AUTOSAR XML (schema 4-2-2)
package /STELLANTIS/EPT/ASWCs
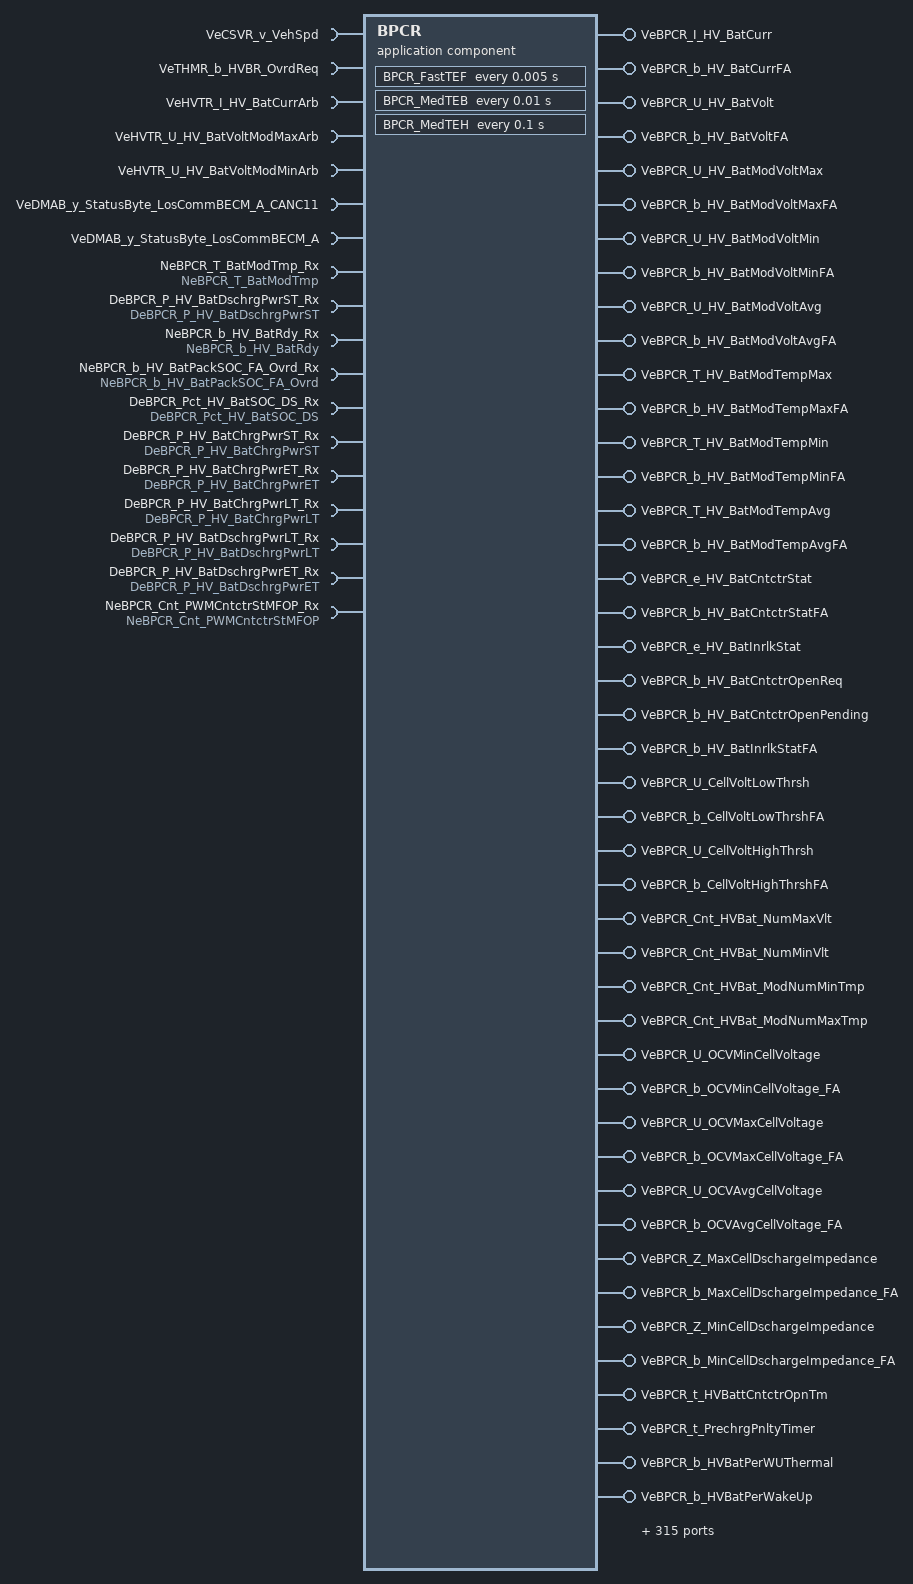
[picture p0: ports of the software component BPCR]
  application sw component type BPCR
    7 x require port, all with nonqueued-receiver-com-spec{data-element=Value, init-value=0}:
      VeCSVR_v_VehSpd: required-interface=VeCSVR_v_VehSpd
      VeTHMR_b_HVBR_OvrdReq: required-interface=VeTHMR_b_HVBR_OvrdReq
      VeHVTR_I_HV_BatCurrArb: required-interface=VeHVTR_I_HV_BatCurrArb
      VeHVTR_U_HV_BatVoltModMaxArb: required-interface=VeHVTR_U_HV_BatVoltModMaxArb
      VeHVTR_U_HV_BatVoltModMinArb: required-interface=VeHVTR_U_HV_BatVoltModMinArb
      VeDMAB_y_StatusByte_LosCommBECM_A_CANC11: required-interface=VeDMAB_y_StatusByte_LosCommBECM_A_CANC11
      VeDMAB_y_StatusByte_LosCommBECM_A: required-interface=VeDMAB_y_StatusByte_LosCommBECM_A
    348 x provide port:
      VeBPCR_I_HV_BatCurr: nonqueued-sender-com-spec{data-element=Value, init-value=0}, provided-interface=VeBPCR_I_HV_BatCurr
      VeBPCR_b_HV_BatCurrFA: nonqueued-sender-com-spec{data-element=Value, init-value=0}, provided-interface=VeBPCR_b_HV_BatCurrFA
      VeBPCR_U_HV_BatVolt: nonqueued-sender-com-spec{data-element=Value, init-value=0}, provided-interface=VeBPCR_U_HV_BatVolt
      VeBPCR_b_HV_BatVoltFA: nonqueued-sender-com-spec{data-element=Value, init-value=0}, provided-interface=VeBPCR_b_HV_BatVoltFA
      VeBPCR_U_HV_BatModVoltMax: nonqueued-sender-com-spec{data-element=Value, init-value=0}, provided-interface=VeBPCR_U_HV_BatModVoltMax
      VeBPCR_b_HV_BatModVoltMaxFA: nonqueued-sender-com-spec{data-element=Value, init-value=0}, provided-interface=VeBPCR_b_HV_BatModVoltMaxFA
      VeBPCR_U_HV_BatModVoltMin: nonqueued-sender-com-spec{data-element=Value, init-value=0}, provided-interface=VeBPCR_U_HV_BatModVoltMin
      VeBPCR_b_HV_BatModVoltMinFA: nonqueued-sender-com-spec{data-element=Value, init-value=0}, provided-interface=VeBPCR_b_HV_BatModVoltMinFA
      VeBPCR_U_HV_BatModVoltAvg: nonqueued-sender-com-spec{data-element=Value, init-value=0}, provided-interface=VeBPCR_U_HV_BatModVoltAvg
      VeBPCR_b_HV_BatModVoltAvgFA: nonqueued-sender-com-spec{data-element=Value, init-value=0}, provided-interface=VeBPCR_b_HV_BatModVoltAvgFA
      VeBPCR_T_HV_BatModTempMax: nonqueued-sender-com-spec{data-element=Value, init-value=0}, provided-interface=VeBPCR_T_HV_BatModTempMax
      VeBPCR_b_HV_BatModTempMaxFA: nonqueued-sender-com-spec{data-element=Value, init-value=0}, provided-interface=VeBPCR_b_HV_BatModTempMaxFA
      VeBPCR_T_HV_BatModTempMin: nonqueued-sender-com-spec{data-element=Value, init-value=0}, provided-interface=VeBPCR_T_HV_BatModTempMin
      VeBPCR_b_HV_BatModTempMinFA: nonqueued-sender-com-spec{data-element=Value, init-value=0}, provided-interface=VeBPCR_b_HV_BatModTempMinFA
      VeBPCR_T_HV_BatModTempAvg: nonqueued-sender-com-spec{data-element=Value, init-value=0}, provided-interface=VeBPCR_T_HV_BatModTempAvg
      VeBPCR_b_HV_BatModTempAvgFA: nonqueued-sender-com-spec{data-element=Value, init-value=0}, provided-interface=VeBPCR_b_HV_BatModTempAvgFA
      VeBPCR_e_HV_BatCntctrStat: nonqueued-sender-com-spec{data-element=Value, init-value=CeHVTR_e_Open}, provided-interface=VeBPCR_e_HV_BatCntctrStat
      VeBPCR_b_HV_BatCntctrStatFA: nonqueued-sender-com-spec{data-element=Value, init-value=0}, provided-interface=VeBPCR_b_HV_BatCntctrStatFA
      VeBPCR_e_HV_BatInrlkStat: nonqueued-sender-com-spec{data-element=Value, init-value=CeHVTR_e_IntrlkNotSourced}, provided-interface=VeBPCR_e_HV_BatInrlkStat
      VeBPCR_b_HV_BatCntctrOpenReq: nonqueued-sender-com-spec{data-element=Value, init-value=0}, provided-interface=VeBPCR_b_HV_BatCntctrOpenReq
      VeBPCR_b_HV_BatCntctrOpenPending: nonqueued-sender-com-spec{data-element=Value, init-value=0}, provided-interface=VeBPCR_b_HV_BatCntctrOpenPending
      VeBPCR_b_HV_BatInrlkStatFA: nonqueued-sender-com-spec{data-element=Value, init-value=0}, provided-interface=VeBPCR_b_HV_BatInrlkStatFA
      VeBPCR_U_CellVoltLowThrsh: nonqueued-sender-com-spec{data-element=Value, init-value=0}, provided-interface=VeBPCR_U_CellVoltLowThrsh
      VeBPCR_b_CellVoltLowThrshFA: nonqueued-sender-com-spec{data-element=Value, init-value=0}, provided-interface=VeBPCR_b_CellVoltLowThrshFA
      VeBPCR_U_CellVoltHighThrsh: nonqueued-sender-com-spec{data-element=Value, init-value=0}, provided-interface=VeBPCR_U_CellVoltHighThrsh
      VeBPCR_b_CellVoltHighThrshFA: nonqueued-sender-com-spec{data-element=Value, init-value=0}, provided-interface=VeBPCR_b_CellVoltHighThrshFA
      VeBPCR_Cnt_HVBat_NumMaxVlt: nonqueued-sender-com-spec{data-element=Value, init-value=0}, provided-interface=VeBPCR_Cnt_HVBat_NumMaxVlt
      VeBPCR_Cnt_HVBat_NumMinVlt: nonqueued-sender-com-spec{data-element=Value, init-value=0}, provided-interface=VeBPCR_Cnt_HVBat_NumMinVlt
      VeBPCR_Cnt_HVBat_ModNumMinTmp: nonqueued-sender-com-spec{data-element=Value, init-value=0}, provided-interface=VeBPCR_Cnt_HVBat_ModNumMinTmp
      VeBPCR_Cnt_HVBat_ModNumMaxTmp: nonqueued-sender-com-spec{data-element=Value, init-value=0}, provided-interface=VeBPCR_Cnt_HVBat_ModNumMaxTmp
      VeBPCR_U_OCVMinCellVoltage: nonqueued-sender-com-spec{data-element=Value, init-value=0}, provided-interface=VeBPCR_U_OCVMinCellVoltage
      VeBPCR_b_OCVMinCellVoltage_FA: nonqueued-sender-com-spec{data-element=Value, init-value=0}, provided-interface=VeBPCR_b_OCVMinCellVoltage_FA
      VeBPCR_U_OCVMaxCellVoltage: nonqueued-sender-com-spec{data-element=Value, init-value=0}, provided-interface=VeBPCR_U_OCVMaxCellVoltage
      VeBPCR_b_OCVMaxCellVoltage_FA: nonqueued-sender-com-spec{data-element=Value, init-value=0}, provided-interface=VeBPCR_b_OCVMaxCellVoltage_FA
      VeBPCR_U_OCVAvgCellVoltage: nonqueued-sender-com-spec{data-element=Value, init-value=0}, provided-interface=VeBPCR_U_OCVAvgCellVoltage
      VeBPCR_b_OCVAvgCellVoltage_FA: nonqueued-sender-com-spec{data-element=Value, init-value=0}, provided-interface=VeBPCR_b_OCVAvgCellVoltage_FA
      VeBPCR_Z_MaxCellDschargeImpedance: nonqueued-sender-com-spec{data-element=Value, init-value=0}, provided-interface=VeBPCR_Z_MaxCellDschargeImpedance
      VeBPCR_b_MaxCellDschargeImpedance_FA: nonqueued-sender-com-spec{data-element=Value, init-value=0}, provided-interface=VeBPCR_b_MaxCellDschargeImpedance_FA
      VeBPCR_Z_MinCellDschargeImpedance: nonqueued-sender-com-spec{data-element=Value, init-value=0}, provided-interface=VeBPCR_Z_MinCellDschargeImpedance
      VeBPCR_b_MinCellDschargeImpedance_FA: nonqueued-sender-com-spec{data-element=Value, init-value=0}, provided-interface=VeBPCR_b_MinCellDschargeImpedance_FA
      VeBPCR_t_HVBattCntctrOpnTm: nonqueued-sender-com-spec{data-element=Value, init-value=0}, provided-interface=VeBPCR_t_HVBattCntctrOpnTm
      VeBPCR_t_PrechrgPnltyTimer: nonqueued-sender-com-spec{data-element=Value, init-value=0}, provided-interface=VeBPCR_t_PrechrgPnltyTimer
      VeBPCR_b_HVBatPerWUThermal: nonqueued-sender-com-spec{data-element=Value, init-value=0}, provided-interface=VeBPCR_b_HVBatPerWUThermal
      VeBPCR_b_HVBatPerWakeUp: nonqueued-sender-com-spec{data-element=Value, init-value=0}, provided-interface=VeBPCR_b_HVBatPerWakeUp
      VeBPCR_t_HVBatSleepTime: nonqueued-sender-com-spec{data-element=Value, init-value=0}, provided-interface=VeBPCR_t_HVBatSleepTime
      VeBPCR_e_BPCMShtDwnRdy: nonqueued-sender-com-spec{data-element=Value, init-value=CeBPCR_e_Not_Ready_for_Shutdown}, provided-interface=VeBPCR_e_BPCMShtDwnRdy
      VeBPCR_e_PwrtrnHV_IsolStat: nonqueued-sender-com-spec{data-element=Value, init-value=CeHMIR_e_IsolUndetermined}, provided-interface=VeBPCR_e_PwrtrnHV_IsolStat
      VeBPCR_b_PwrLimON: nonqueued-sender-com-spec{data-element=Value, init-value=0}, provided-interface=VeBPCR_b_PwrLimON
      VeBPCR_Pct_HVBatSOH: nonqueued-sender-com-spec{data-element=Value, init-value=0}, provided-interface=VeBPCR_Pct_HVBatSOH
      VeBPCR_U_MaxCellVltAlld: nonqueued-sender-com-spec{data-element=Value, init-value=0}, provided-interface=VeBPCR_U_MaxCellVltAlld
      VeBPCR_b_MaxCellVltAlld_FA: nonqueued-sender-com-spec{data-element=Value, init-value=0}, provided-interface=VeBPCR_b_MaxCellVltAlld_FA
      VeBPCR_U_MinCellVltAlld: nonqueued-sender-com-spec{data-element=Value, init-value=0}, provided-interface=VeBPCR_U_MinCellVltAlld
      VeBPCR_b_MinCellVltAlld_FA: nonqueued-sender-com-spec{data-element=Value, init-value=0}, provided-interface=VeBPCR_b_MinCellVltAlld_FA
      VeBPCR_U_MaxPkVltAlld: nonqueued-sender-com-spec{data-element=Value, init-value=0}, provided-interface=VeBPCR_U_MaxPkVltAlld
      VeBPCR_b_MaxPkVltAlld_FA: nonqueued-sender-com-spec{data-element=Value, init-value=0}, provided-interface=VeBPCR_b_MaxPkVltAlld_FA
      VeBPCR_U_MinPkVltAlld: nonqueued-sender-com-spec{data-element=Value, init-value=0}, provided-interface=VeBPCR_U_MinPkVltAlld
      VeBPCR_b_MinPkVltAlld_FA: nonqueued-sender-com-spec{data-element=Value, init-value=0}, provided-interface=VeBPCR_b_MinPkVltAlld_FA
      VeBPCR_b_HVBatRdy: nonqueued-sender-com-spec{data-element=Value, init-value=0}, provided-interface=VeBPCR_b_HVBatRdy
      VeBPCR_Pct_HVBatSOHLow: nonqueued-sender-com-spec{data-element=Value, init-value=0}, provided-interface=VeBPCR_Pct_HVBatSOHLow
      VeBPCR_t_HVBatRealTimeClock: nonqueued-sender-com-spec{data-element=Value, init-value=0}, provided-interface=VeBPCR_t_HVBatRealTimeClock
      VeBPCR_e_HVBatIntrlkIntrnlStat: nonqueued-sender-com-spec{data-element=Value, init-value=CeBPCR_e_HVBatIntrlkSNA}, provided-interface=VeBPCR_e_HVBatIntrlkIntrnlStat
      VeBPCR_b_HVBatIntrlkIntrnlStatFA: nonqueued-sender-com-spec{data-element=Value, init-value=0}, provided-interface=VeBPCR_b_HVBatIntrlkIntrnlStatFA
      VeBPCR_b_HEVOnRqBPCM: nonqueued-sender-com-spec{data-element=Value, init-value=0}, provided-interface=VeBPCR_b_HEVOnRqBPCM
      VeBPCR_b_HEVOnRqBPCM_Debounced: nonqueued-sender-com-spec{data-element=Value, init-value=0}, provided-interface=VeBPCR_b_HEVOnRqBPCM_Debounced
      VeBPCR_b_BPCM_OVActv: nonqueued-sender-com-spec{data-element=Value, init-value=0}, provided-interface=VeBPCR_b_BPCM_OVActv
      VeBPCR_b_BPCM_UVActv: nonqueued-sender-com-spec{data-element=Value, init-value=0}, provided-interface=VeBPCR_b_BPCM_UVActv
      VeBPCR_e_HVBatRdy: nonqueued-sender-com-spec{data-element=Value, init-value=0}, provided-interface=VeBPCR_e_HVBatRdy
      VeBPCR_b_HVBatRealTimeClock_FA: nonqueued-sender-com-spec{data-element=Value, init-value=0}, provided-interface=VeBPCR_b_HVBatRealTimeClock_FA
      VeBPCR_e_PWMDecodedCntctrSts: nonqueued-sender-com-spec{data-element=Value, init-value=CeBPCR_e_CloseCntctrCmd}, provided-interface=VeBPCR_e_PWMDecodedCntctrSts
      VeBPCR_P_TracBat_EChrgPowLong: nonqueued-sender-com-spec{data-element=Value, init-value=0}, provided-interface=VeBPCR_P_TracBat_EChrgPowLong
      VeBPCR_b_TracBat_EChrgPowLongFA: nonqueued-sender-com-spec{data-element=Value, init-value=0}, provided-interface=VeBPCR_b_TracBat_EChrgPowLongFA
      VeBPCR_b_PWMTimerOOR: nonqueued-sender-com-spec{data-element=Value, init-value=0}, provided-interface=VeBPCR_b_PWMTimerOOR
      VeBPCR_b_CntctrCntrl_PWM_FA: nonqueued-sender-com-spec{data-element=Value, init-value=0}, provided-interface=VeBPCR_b_CntctrCntrl_PWM_FA
      VeBPCR_T_HVBatClgOutletTemp: nonqueued-sender-com-spec{data-element=Value, init-value=0}, provided-interface=VeBPCR_T_HVBatClgOutletTemp
      VeBPCR_b_HVBatClgOutletTempFA: nonqueued-sender-com-spec{data-element=Value, init-value=0}, provided-interface=VeBPCR_b_HVBatClgOutletTempFA
      VeBPCR_e_BPCM_LIN_BusOff: nonqueued-sender-com-spec{data-element=Value, init-value=CeBPCR_e_LIN_BusOff_Disabled}, provided-interface=VeBPCR_e_BPCM_LIN_BusOff
      VeBPCR_b_BPCM_LIN_BusOff_FA: nonqueued-sender-com-spec{data-element=Value, init-value=0}, provided-interface=VeBPCR_b_BPCM_LIN_BusOff_FA
      VeBPCR_b_BPCM_LIN_BusOff_SgnlRcvd: nonqueued-sender-com-spec{data-element=Value, init-value=0}, provided-interface=VeBPCR_b_BPCM_LIN_BusOff_SgnlRcvd
      VeBPCR_e_BPCM_LOC_BCP: nonqueued-sender-com-spec{data-element=Value, init-value=CeBPCR_e_LOC_BCP_False}, provided-interface=VeBPCR_e_BPCM_LOC_BCP
      VeBPCR_b_BPCM_LOC_BCP_FA: nonqueued-sender-com-spec{data-element=Value, init-value=0}, provided-interface=VeBPCR_b_BPCM_LOC_BCP_FA
      VeBPCR_b_BPCM_LOC_BCP_SgnlRcvd: nonqueued-sender-com-spec{data-element=Value, init-value=0}, provided-interface=VeBPCR_b_BPCM_LOC_BCP_SgnlRcvd
      VeBPCR_e_BPCM_LOC_BatClntHtr: nonqueued-sender-com-spec{data-element=Value, init-value=CeBPCR_e_LOC_BatClntHtr_False}, provided-interface=VeBPCR_e_BPCM_LOC_BatClntHtr
      VeBPCR_b_BPCM_LOC_BatClntHtr_FA: nonqueued-sender-com-spec{data-element=Value, init-value=0}, provided-interface=VeBPCR_b_BPCM_LOC_BatClntHtr_FA
      VeBPCR_b_BPCM_LOC_BatClntHtr_SgnlRcvd: nonqueued-sender-com-spec{data-element=Value, init-value=0}, provided-interface=VeBPCR_b_BPCM_LOC_BatClntHtr_SgnlRcvd
      VeBPCR_I_MaxChrgCurrAlwd: nonqueued-sender-com-spec{data-element=Value, init-value=0}, provided-interface=VeBPCR_I_MaxChrgCurrAlwd
      VeBPCR_e_ChargingStat_BPCM: nonqueued-sender-com-spec{data-element=Value, init-value=CeOBCR_e_BattNotReady}, provided-interface=VeBPCR_e_ChargingStat_BPCM
      VeBPCR_P_HV_BatDschrgPwrET: nonqueued-sender-com-spec{data-element=Value, init-value=0}, provided-interface=VeBPCR_P_HV_BatDschrgPwrET
      VeBPCR_b_HV_BatDschrgPwrET_FA: nonqueued-sender-com-spec{data-element=Value, init-value=0}, provided-interface=VeBPCR_b_HV_BatDschrgPwrET_FA
      VeBPCR_b_HV_BatDschrgPwrETSgnl_Rcvd: nonqueued-sender-com-spec{data-element=Value, init-value=0}, provided-interface=VeBPCR_b_HV_BatDschrgPwrETSgnl_Rcvd
      VeBPCR_P_HV_BatDschrgPwrLT: nonqueued-sender-com-spec{data-element=Value, init-value=0}, provided-interface=VeBPCR_P_HV_BatDschrgPwrLT
      VeBPCR_b_HV_BatDschrgPwrLT_FA: nonqueued-sender-com-spec{data-element=Value, init-value=0}, provided-interface=VeBPCR_b_HV_BatDschrgPwrLT_FA
      VeBPCR_b_HV_BatDschrgPwrLTSgnl_Rcvd: nonqueued-sender-com-spec{data-element=Value, init-value=0}, provided-interface=VeBPCR_b_HV_BatDschrgPwrLTSgnl_Rcvd
      VeBPCR_P_HV_BatDschrgPwrST: nonqueued-sender-com-spec{data-element=Value, init-value=0}, provided-interface=VeBPCR_P_HV_BatDschrgPwrST
      VeBPCR_b_HV_BatDschrgPwrST_FA: nonqueued-sender-com-spec{data-element=Value, init-value=0}, provided-interface=VeBPCR_b_HV_BatDschrgPwrST_FA
      VeBPCR_b_HV_BatDschrgPwrSTSgnl_Rcvd: nonqueued-sender-com-spec{data-element=Value, init-value=0}, provided-interface=VeBPCR_b_HV_BatDschrgPwrSTSgnl_Rcvd
      VeBPCR_P_HV_BatChrgPwrET: nonqueued-sender-com-spec{data-element=Value, init-value=0}, provided-interface=VeBPCR_P_HV_BatChrgPwrET
      VeBPCR_b_HV_BatChrgPwrET_FA: nonqueued-sender-com-spec{data-element=Value, init-value=0}, provided-interface=VeBPCR_b_HV_BatChrgPwrET_FA
      VeBPCR_b_HV_BatChrgPwrETSgnl_Rcvd: nonqueued-sender-com-spec{data-element=Value, init-value=0}, provided-interface=VeBPCR_b_HV_BatChrgPwrETSgnl_Rcvd
      VeBPCR_P_HV_BatChrgPwrLT: nonqueued-sender-com-spec{data-element=Value, init-value=0}, provided-interface=VeBPCR_P_HV_BatChrgPwrLT
      VeBPCR_b_HV_BatChrgPwrLT_FA: nonqueued-sender-com-spec{data-element=Value, init-value=0}, provided-interface=VeBPCR_b_HV_BatChrgPwrLT_FA
      VeBPCR_b_HV_BatChrgPwrLTSgnl_Rcvd: nonqueued-sender-com-spec{data-element=Value, init-value=0}, provided-interface=VeBPCR_b_HV_BatChrgPwrLTSgnl_Rcvd
      VeBPCR_P_HV_BatChrgPwrST: nonqueued-sender-com-spec{data-element=Value, init-value=0}, provided-interface=VeBPCR_P_HV_BatChrgPwrST
      VeBPCR_b_HV_BatChrgPwrST_FA: nonqueued-sender-com-spec{data-element=Value, init-value=0}, provided-interface=VeBPCR_b_HV_BatChrgPwrST_FA
      VeBPCR_b_HV_BatChrgPwrSTSgnl_Rcvd: nonqueued-sender-com-spec{data-element=Value, init-value=0}, provided-interface=VeBPCR_b_HV_BatChrgPwrSTSgnl_Rcvd
      VeBPCR_Pct_HV_BatPackSOC: nonqueued-sender-com-spec{data-element=Value, init-value=0}, provided-interface=VeBPCR_Pct_HV_BatPackSOC
      VeBPCR_b_HV_BatPackSOC_FA: nonqueued-sender-com-spec{data-element=Value, init-value=0}, provided-interface=VeBPCR_b_HV_BatPackSOC_FA
      VeBPCR_b_HV_BatPackSOC_SgnlRcvd: nonqueued-sender-com-spec{data-element=Value, init-value=0}, provided-interface=VeBPCR_b_HV_BatPackSOC_SgnlRcvd
      VeBPCR_q_FullAmpHrCap: nonqueued-sender-com-spec{data-element=Value, init-value=0}, provided-interface=VeBPCR_q_FullAmpHrCap
      VeBPCR_b_HVBatPerWU12VChrg: nonqueued-sender-com-spec{data-element=Value, init-value=0}, provided-interface=VeBPCR_b_HVBatPerWU12VChrg
      VeBPCR_b_HVBat_DC_CntctrOpn: nonqueued-sender-com-spec{data-element=Value, init-value=0}, provided-interface=VeBPCR_b_HVBat_DC_CntctrOpn
      VeBPCR_b_HVBat_DC_CntctrReq: nonqueued-sender-com-spec{data-element=Value, init-value=0}, provided-interface=VeBPCR_b_HVBat_DC_CntctrReq
      VeBPCR_b_DC_Isolation_Sts: nonqueued-sender-com-spec{data-element=Value, init-value=0}, provided-interface=VeBPCR_b_DC_Isolation_Sts
      VeBPCR_e_HVBat_DC_CntctrStat: nonqueued-sender-com-spec{data-element=Value, init-value=CeBPCR_e_DCCntctrSts_Open}, provided-interface=VeBPCR_e_HVBat_DC_CntctrStat
      VeBPCR_b_HVBat_DC_CntctrStat_FA: nonqueued-sender-com-spec{data-element=Value, init-value=0}, provided-interface=VeBPCR_b_HVBat_DC_CntctrStat_FA
      VeBPCR_b_ChargingStat_BPCMFA: nonqueued-sender-com-spec{data-element=Value, init-value=0}, provided-interface=VeBPCR_b_ChargingStat_BPCMFA
      VeBPCR_b_MaxChgCurrAlwdFA: nonqueued-sender-com-spec{data-element=Value, init-value=0}, provided-interface=VeBPCR_b_MaxChgCurrAlwdFA
      VeBPCR_q_RemainingAmpHrCap: nonqueued-sender-com-spec{data-element=Value, init-value=0}, provided-interface=VeBPCR_q_RemainingAmpHrCap
      VeBPCR_b_RemainingAmpHrCapFA: nonqueued-sender-com-spec{data-element=Value, init-value=0}, provided-interface=VeBPCR_b_RemainingAmpHrCapFA
      VeBPCR_T_BatModTmp: nonqueued-sender-com-spec{data-element=Value, init-value=0}, provided-interface=VeBPCR_T_BatModTmp
      VeBPCR_T_HV_BatModTempMax_Arb: nonqueued-sender-com-spec{data-element=Value, init-value=0}, provided-interface=VeBPCR_T_HV_BatModTempMax_Arb
      VeBPCR_T_HV_BatModTempMin_Arb: nonqueued-sender-com-spec{data-element=Value, init-value=0}, provided-interface=VeBPCR_T_HV_BatModTempMin_Arb
      VeBPCR_b_HV_BatDschrgPwrLT_FA_Ovrd: nonqueued-sender-com-spec{data-element=Value, init-value=0}, provided-interface=VeBPCR_b_HV_BatDschrgPwrLT_FA_Ovrd
      VeBPCR_P_HV_BatDschrgPwrLT_Arb: nonqueued-sender-com-spec{data-element=Value, init-value=0}, provided-interface=VeBPCR_P_HV_BatDschrgPwrLT_Arb
      VeBPCR_b_HV_BatChrgPwrLT_FA_Ovrd: nonqueued-sender-com-spec{data-element=Value, init-value=0}, provided-interface=VeBPCR_b_HV_BatChrgPwrLT_FA_Ovrd
      VeBPCR_P_HV_BatChrgPwrLT_Arb: nonqueued-sender-com-spec{data-element=Value, init-value=0}, provided-interface=VeBPCR_P_HV_BatChrgPwrLT_Arb
      VeBPCR_b_HV_BatDschrgPwrET_FA_Ovrd: nonqueued-sender-com-spec{data-element=Value, init-value=0}, provided-interface=VeBPCR_b_HV_BatDschrgPwrET_FA_Ovrd
      VeBPCR_P_HV_BatDschrgPwrET_Arb: nonqueued-sender-com-spec{data-element=Value, init-value=0}, provided-interface=VeBPCR_P_HV_BatDschrgPwrET_Arb
      VeBPCR_b_HV_BatChrgPwrET_FA_Ovrd: nonqueued-sender-com-spec{data-element=Value, init-value=0}, provided-interface=VeBPCR_b_HV_BatChrgPwrET_FA_Ovrd
      VeBPCR_P_HV_BatChrgPwrET_Arb: nonqueued-sender-com-spec{data-element=Value, init-value=0}, provided-interface=VeBPCR_P_HV_BatChrgPwrET_Arb
      VeBPCR_b_HV_BatDschrgPwrST_FA_Ovrd: nonqueued-sender-com-spec{data-element=Value, init-value=0}, provided-interface=VeBPCR_b_HV_BatDschrgPwrST_FA_Ovrd
      VeBPCR_P_HV_BatDschrgPwrST_Arb: nonqueued-sender-com-spec{data-element=Value, init-value=0}, provided-interface=VeBPCR_P_HV_BatDschrgPwrST_Arb
      VeBPCR_b_HV_BatChrgPwrST_FA_Ovrd: nonqueued-sender-com-spec{data-element=Value, init-value=0}, provided-interface=VeBPCR_b_HV_BatChrgPwrST_FA_Ovrd
      VeBPCR_P_HV_BatChrgPwrST_Arb: nonqueued-sender-com-spec{data-element=Value, init-value=0}, provided-interface=VeBPCR_P_HV_BatChrgPwrST_Arb
      VeBPCR_b_HV_BatPackSOC_FA_Ovrd: nonqueued-sender-com-spec{data-element=Value, init-value=0}, provided-interface=VeBPCR_b_HV_BatPackSOC_FA_Ovrd
      VeBPCR_U_CellVoltOVThrsh: nonqueued-sender-com-spec{data-element=Value, init-value=0}, provided-interface=VeBPCR_U_CellVoltOVThrsh
      VeBPCR_U_CellVoltUVThrsh: nonqueued-sender-com-spec{data-element=Value, init-value=0}, provided-interface=VeBPCR_U_CellVoltUVThrsh
      VeBPCR_b_HV_BatCurrSFA: nonqueued-sender-com-spec{data-element=Value, init-value=0}, provided-interface=VeBPCR_b_HV_BatCurrSFA
      VeBPCR_b_HV_BatPackSOC_SFA: nonqueued-sender-com-spec{data-element=Value, init-value=0}, provided-interface=VeBPCR_b_HV_BatPackSOC_SFA
      VeBPCR_b_HV_BatVoltModMaxSFA: nonqueued-sender-com-spec{data-element=Value, init-value=0}, provided-interface=VeBPCR_b_HV_BatVoltModMaxSFA
      VeBPCR_b_CmdBatPwrLimSFA_Enbl: nonqueued-sender-com-spec{data-element=Value, init-value=0}, provided-interface=VeBPCR_b_CmdBatPwrLimSFA_Enbl
      VeBPCR_b_HV_BatMaxModTmpSFA: nonqueued-sender-com-spec{data-element=Value, init-value=0}, provided-interface=VeBPCR_b_HV_BatMaxModTmpSFA
      VeBPCR_Pct_HV_BatPackSOC_Arb: nonqueued-sender-com-spec{data-element=Value, init-value=0}, provided-interface=VeBPCR_Pct_HV_BatPackSOC_Arb
      VeBPCR_Pct_HV_BatPackSOC_Ovrd: nonqueued-sender-com-spec{data-element=Value, init-value=0}, provided-interface=VeBPCR_Pct_HV_BatPackSOC_Ovrd
      VeBPCR_b_MIL_OnRq_BPCM_Debounced: nonqueued-sender-com-spec{data-element=Value, init-value=0}, provided-interface=VeBPCR_b_MIL_OnRq_BPCM_Debounced
      VeBPCR_b_ThrmlRnawyFlg: nonqueued-sender-com-spec{data-element=Value, init-value=0}, provided-interface=VeBPCR_b_ThrmlRnawyFlg
      VeBPCR_P_TracBat_EChrgPowLongMod: nonqueued-sender-com-spec{data-element=Value, init-value=0}, provided-interface=VeBPCR_P_TracBat_EChrgPowLongMod
      VeBPCR_b_StkOpnChkCmpl: nonqueued-sender-com-spec{data-element=Value, init-value=0}, provided-interface=VeBPCR_b_StkOpnChkCmpl
      VeBPCR_b_BatShtOffFlg: nonqueued-sender-com-spec{data-element=Value, init-value=0}, provided-interface=VeBPCR_b_BatShtOffFlg
      VeBPCR_e_BPCM_CommFail: nonqueued-sender-com-spec{data-element=Value, init-value=CeSRAR_e_CommFail_NoFault}, provided-interface=VeBPCR_e_BPCM_CommFail
      VeBPCR_b_BPCM_CommFailFA: nonqueued-sender-com-spec{data-element=Value, init-value=0}, provided-interface=VeBPCR_b_BPCM_CommFailFA
      VeBPCR_T_BusBarTemp: nonqueued-sender-com-spec{data-element=Value, init-value=0}, provided-interface=VeBPCR_T_BusBarTemp
      VeBPCR_T_BDUBusBarTemp: nonqueued-sender-com-spec{data-element=Value, init-value=0}, provided-interface=VeBPCR_T_BDUBusBarTemp
      VeBPCR_e_FaultSts_HybBatPosConConCirPer: nonqueued-sender-com-spec{data-element=Value, init-value=CeDFIB_e_Init}, provided-interface=VeBPCR_e_FaultSts_HybBatPosConConCirPer
      VeBPCR_e_DCIsolSts: nonqueued-sender-com-spec{data-element=Value, init-value=CeBPCR_e_DCIsolSts_NotPerformed}, provided-interface=VeBPCR_e_DCIsolSts
      VeBPCR_b_DCIsolStsFA: nonqueued-sender-com-spec{data-element=Value, init-value=0}, provided-interface=VeBPCR_b_DCIsolStsFA
      VeBPCR_U_HV_InternalStringVolt1: nonqueued-sender-com-spec{data-element=Value, init-value=0}, provided-interface=VeBPCR_U_HV_InternalStringVolt1
      VeBPCR_b_HV_InternalStringVolt1FA: nonqueued-sender-com-spec{data-element=Value, init-value=0}, provided-interface=VeBPCR_b_HV_InternalStringVolt1FA
      VeBPCR_U_HV_InternalStringVolt2: nonqueued-sender-com-spec{data-element=Value, init-value=0}, provided-interface=VeBPCR_U_HV_InternalStringVolt2
      VeBPCR_b_HV_InternalStringVolt2FA: nonqueued-sender-com-spec{data-element=Value, init-value=0}, provided-interface=VeBPCR_b_HV_InternalStringVolt2FA
      VeBPCR_U_HV_SeriesVolt: nonqueued-sender-com-spec{data-element=Value, init-value=0}, provided-interface=VeBPCR_U_HV_SeriesVolt
      VeBPCR_b_HV_SeriesVoltFA: nonqueued-sender-com-spec{data-element=Value, init-value=0}, provided-interface=VeBPCR_b_HV_SeriesVoltFA
      VeBPCR_b_HV_AuxLoadOffReq: nonqueued-sender-com-spec{data-element=Value, init-value=0}, provided-interface=VeBPCR_b_HV_AuxLoadOffReq
      VeBPCR_b_HV_AuxLoadOffReqFA: nonqueued-sender-com-spec{data-element=Value, init-value=0}, provided-interface=VeBPCR_b_HV_AuxLoadOffReqFA
      VeBPCR_I_HV_Current_String2: nonqueued-sender-com-spec{data-element=Value, init-value=0}, provided-interface=VeBPCR_I_HV_Current_String2
      VeBPCR_b_HV_Current_String2_FA: nonqueued-sender-com-spec{data-element=Value, init-value=0}, provided-interface=VeBPCR_b_HV_Current_String2_FA
      VeBPCR_U_BPCM_HV_InternalVoltage: nonqueued-sender-com-spec{data-element=Value, init-value=0}, provided-interface=VeBPCR_U_BPCM_HV_InternalVoltage
      VeBPCR_b_BPCM_HV_InternalVoltage_FA: nonqueued-sender-com-spec{data-element=Value, init-value=0}, provided-interface=VeBPCR_b_BPCM_HV_InternalVoltage_FA
      VeBPCR_e_HV_BatIsolStat: nonqueued-sender-com-spec{data-element=Value, init-value=CeHVTR_e_IsolUndetermined}, provided-interface=VeBPCR_e_HV_BatIsolStat
      VeBPCR_e_HV_BatIsolStat_raw: nonqueued-sender-com-spec{data-element=Value, init-value=CeBPCR_e_GFD_NotPerformed}, provided-interface=VeBPCR_e_HV_BatIsolStat_raw
      VeBPCR_e_HVTracBatCntctrConfig: nonqueued-sender-com-spec{data-element=Value, init-value=CeBPCR_e_HVTracBatConfig_Closed_Parallel}, provided-interface=VeBPCR_e_HVTracBatCntctrConfig
      VeBPCR_b_HVTracBatCntctrConfigFA: nonqueued-sender-com-spec{data-element=Value, init-value=0}, provided-interface=VeBPCR_b_HVTracBatCntctrConfigFA
      VeBPCR_e_HVDcChargeTypeStat: nonqueued-sender-com-spec{data-element=Value, init-value=CeBPCR_e_HVDcChargeStat_400V}, provided-interface=VeBPCR_e_HVDcChargeTypeStat
      VeBPCR_b_HVDcChargeTypeStatFA: nonqueued-sender-com-spec{data-element=Value, init-value=0}, provided-interface=VeBPCR_b_HVDcChargeTypeStatFA
      VeBPCR_b_HVBatCntrWeld_ImpdOpn: nonqueued-sender-com-spec{data-element=Value, init-value=0}, provided-interface=VeBPCR_b_HVBatCntrWeld_ImpdOpn
      VeBPCR_b_Flst_HVBatCntrWeld_ImpdOpn: nonqueued-sender-com-spec{data-element=Value, init-value=0}, provided-interface=VeBPCR_b_Flst_HVBatCntrWeld_ImpdOpn
      FsftBPCR_I_HV_BatCurr: server-com-spec=FsftBPCR_I_HV_BatCurr, provided-interface=FsftBPCR_I_HV_BatCurr
      FsftBPCR_I_MaxChgCurrAlwd: server-com-spec=FsftBPCR_I_MaxChgCurrAlwd, provided-interface=FsftBPCR_I_MaxChgCurrAlwd
      FsftBPCR_P_TracBat_EChrgPowLong: server-com-spec=FsftBPCR_P_TracBat_EChrgPowLong, provided-interface=FsftBPCR_P_TracBat_EChrgPowLong
      FsftBPCR_R_HV_BatImped: server-com-spec=FsftBPCR_R_HV_BatImped, provided-interface=FsftBPCR_R_HV_BatImped
      FsftBPCR_U_CellVoltHighThrsh: server-com-spec=FsftBPCR_U_CellVoltHighThrsh, provided-interface=FsftBPCR_U_CellVoltHighThrsh
      FsftBPCR_U_CellVoltLowThrsh: server-com-spec=FsftBPCR_U_CellVoltLowThrsh, provided-interface=FsftBPCR_U_CellVoltLowThrsh
      FsftBPCR_U_HV_BatModVoltAvg: server-com-spec=FsftBPCR_U_HV_BatModVoltAvg, provided-interface=FsftBPCR_U_HV_BatModVoltAvg
      FsftBPCR_U_HV_BatModVoltMax: server-com-spec=FsftBPCR_U_HV_BatModVoltMax, provided-interface=FsftBPCR_U_HV_BatModVoltMax
      FsftBPCR_U_HV_BatModVoltMin: server-com-spec=FsftBPCR_U_HV_BatModVoltMin, provided-interface=FsftBPCR_U_HV_BatModVoltMin
      FsftBPCR_U_HV_BatVolt: server-com-spec=FsftBPCR_U_HV_BatVolt, provided-interface=FsftBPCR_U_HV_BatVolt
      FsftBPCR_U_MaxCellVltAlld: server-com-spec=FsftBPCR_U_MaxCellVltAlld, provided-interface=FsftBPCR_U_MaxCellVltAlld
      FsftBPCR_U_MaxPkVltAlld: server-com-spec=FsftBPCR_U_MaxPkVltAlld, provided-interface=FsftBPCR_U_MaxPkVltAlld
      FsftBPCR_U_MinCellVltAlld: server-com-spec=FsftBPCR_U_MinCellVltAlld, provided-interface=FsftBPCR_U_MinCellVltAlld
      FsftBPCR_U_MinPkVltAlld: server-com-spec=FsftBPCR_U_MinPkVltAlld, provided-interface=FsftBPCR_U_MinPkVltAlld
      FsftBPCR_U_OCVAveCellVoltage: server-com-spec=FsftBPCR_U_OCVAveCellVoltage, provided-interface=FsftBPCR_U_OCVAveCellVoltage
      FsftBPCR_U_OCVMaxCellVoltage: server-com-spec=FsftBPCR_U_OCVMaxCellVoltage, provided-interface=FsftBPCR_U_OCVMaxCellVoltage
      FsftBPCR_U_OCVMinCellVoltage: server-com-spec=FsftBPCR_U_OCVMinCellVoltage, provided-interface=FsftBPCR_U_OCVMinCellVoltage
      FsftBPCR_Z_MaxCellDischargeImpedance: server-com-spec=FsftBPCR_Z_MaxCellDischargeImpedance, provided-interface=FsftBPCR_Z_MaxCellDischargeImpedance
      FsftBPCR_Z_MinCellDischargeImpedance: server-com-spec=FsftBPCR_Z_MinCellDischargeImpedance, provided-interface=FsftBPCR_Z_MinCellDischargeImpedance
      FsftBPCR_b_BPCM_LIN_BusOff: server-com-spec=FsftBPCR_b_BPCM_LIN_BusOff, provided-interface=FsftBPCR_b_BPCM_LIN_BusOff
      FsftBPCR_b_BPCM_LOC_BCP: server-com-spec=FsftBPCR_b_BPCM_LOC_BCP, provided-interface=FsftBPCR_b_BPCM_LOC_BCP
      FsftBPCR_b_BPCM_LOC_BatClntHtr: server-com-spec=FsftBPCR_b_BPCM_LOC_BatClntHtr, provided-interface=FsftBPCR_b_BPCM_LOC_BatClntHtr
      FsftBPCR_b_HVBatCntrWeld_ImpdOpn: server-com-spec=FsftBPCR_b_HVBatCntrWeld_ImpdOpn, provided-interface=FsftBPCR_b_HVBatCntrWeld_ImpdOpn
      FsftBPCR_b_HVBatRdy: server-com-spec=FsftBPCR_b_HVBatRdy, provided-interface=FsftBPCR_b_HVBatRdy
      FsftBPCR_b_HVBat_DC_CntctrStat: server-com-spec=FsftBPCR_b_HVBat_DC_CntctrStat, provided-interface=FsftBPCR_b_HVBat_DC_CntctrStat
      FsftBPCR_b_HV_AuxLoadOffReq: server-com-spec=FsftBPCR_b_HV_AuxLoadOffReq, provided-interface=FsftBPCR_b_HV_AuxLoadOffReq
      FsftBPCR_b_HV_BatChrgPwrET: server-com-spec=FsftBPCR_b_HV_BatChrgPwrET, provided-interface=FsftBPCR_b_HV_BatChrgPwrET
      FsftBPCR_b_HV_BatChrgPwrLT: server-com-spec=FsftBPCR_b_HV_BatChrgPwrLT, provided-interface=FsftBPCR_b_HV_BatChrgPwrLT
      FsftBPCR_b_HV_BatChrgPwrST: server-com-spec=FsftBPCR_b_HV_BatChrgPwrST, provided-interface=FsftBPCR_b_HV_BatChrgPwrST
      FsftBPCR_b_HV_BatCurrString2: server-com-spec=FsftBPCR_b_HV_BatCurrString2, provided-interface=FsftBPCR_b_HV_BatCurrString2
      FsftBPCR_b_HV_BatDschrgPwrET: server-com-spec=FsftBPCR_b_HV_BatDschrgPwrET, provided-interface=FsftBPCR_b_HV_BatDschrgPwrET
      FsftBPCR_b_HV_BatDschrgPwrLT: server-com-spec=FsftBPCR_b_HV_BatDschrgPwrLT, provided-interface=FsftBPCR_b_HV_BatDschrgPwrLT
      FsftBPCR_b_HV_BatDschrgPwrST: server-com-spec=FsftBPCR_b_HV_BatDschrgPwrST, provided-interface=FsftBPCR_b_HV_BatDschrgPwrST
      FsftBPCR_b_HV_BatModTempAvg: server-com-spec=FsftBPCR_b_HV_BatModTempAvg, provided-interface=FsftBPCR_b_HV_BatModTempAvg
      FsftBPCR_b_HV_BatModTempMax: server-com-spec=FsftBPCR_b_HV_BatModTempMax, provided-interface=FsftBPCR_b_HV_BatModTempMax
      FsftBPCR_b_HV_BatModTempMin: server-com-spec=FsftBPCR_b_HV_BatModTempMin, provided-interface=FsftBPCR_b_HV_BatModTempMin
      FsftBPCR_b_HV_BatPackSOC: server-com-spec=FsftBPCR_b_HV_BatPackSOC, provided-interface=FsftBPCR_b_HV_BatPackSOC
      FsftBPCR_b_HV_DcChargeTypeStat: server-com-spec=FsftBPCR_b_HV_DcChargeTypeStat, provided-interface=FsftBPCR_b_HV_DcChargeTypeStat
      FsftBPCR_b_HV_InternalStringVolt1: server-com-spec=FsftBPCR_b_HV_InternalStringVolt1, provided-interface=FsftBPCR_b_HV_InternalStringVolt1
      FsftBPCR_b_HV_InternalStringVolt2: server-com-spec=FsftBPCR_b_HV_InternalStringVolt2, provided-interface=FsftBPCR_b_HV_InternalStringVolt2
      FsftBPCR_b_HV_InternalVolt: server-com-spec=FsftBPCR_b_HV_InternalVolt, provided-interface=FsftBPCR_b_HV_InternalVolt
      FsftBPCR_b_HV_SeriesVolt: server-com-spec=FsftBPCR_b_HV_SeriesVolt, provided-interface=FsftBPCR_b_HV_SeriesVolt
      FsftBPCR_b_HV_TracBatCntctrConfig: server-com-spec=FsftBPCR_b_HV_TracBatCntctrConfig, provided-interface=FsftBPCR_b_HV_TracBatCntctrConfig
      FsftBPCR_b_ThrmlRnawy_Warn: server-com-spec=FsftBPCR_b_ThrmlRnawy_Warn, provided-interface=FsftBPCR_b_ThrmlRnawy_Warn
      FsftBPCR_cnt_HVBatt_ModNumMaxTmp: server-com-spec=FsftBPCR_cnt_HVBatt_ModNumMaxTmp, provided-interface=FsftBPCR_cnt_HVBatt_ModNumMaxTmp
      FsftBPCR_cnt_HVBatt_ModNumMinTmp: server-com-spec=FsftBPCR_cnt_HVBatt_ModNumMinTmp, provided-interface=FsftBPCR_cnt_HVBatt_ModNumMinTmp
      FsftBPCR_e_BPCM_Comm_Fail: server-com-spec=FsftBPCR_e_BPCM_Comm_Fail, provided-interface=FsftBPCR_e_BPCM_Comm_Fail
      FsftBPCR_e_ChargingStat_BPCM: server-com-spec=FsftBPCR_e_ChargingStat_BPCM, provided-interface=FsftBPCR_e_ChargingStat_BPCM
      FsftBPCR_e_DCIsolSts: server-com-spec=FsftBPCR_e_DCIsolSts, provided-interface=FsftBPCR_e_DCIsolSts
      FsftBPCR_e_HVBatIntrlkIntrnlStat: server-com-spec=FsftBPCR_e_HVBatIntrlkIntrnlStat, provided-interface=FsftBPCR_e_HVBatIntrlkIntrnlStat
      FsftBPCR_e_HV_BatCntctrStat: server-com-spec=FsftBPCR_e_HV_BatCntctrStat, provided-interface=FsftBPCR_e_HV_BatCntctrStat
      FsftBPCR_e_HV_BatInrlkStat: server-com-spec=FsftBPCR_e_HV_BatInrlkStat, provided-interface=FsftBPCR_e_HV_BatInrlkStat
      FsftBPCR_e_HV_BatIsolStat: server-com-spec=FsftBPCR_e_HV_BatIsolStat, provided-interface=FsftBPCR_e_HV_BatIsolStat
      FsftBPCR_q_FullAmpHrCap: server-com-spec=FsftBPCR_q_FullAmpHrCap, provided-interface=FsftBPCR_q_FullAmpHrCap
      FsftBPCR_q_RemainingAmpHrCap: server-com-spec=FsftBPCR_q_RemainingAmpHrCap, provided-interface=FsftBPCR_q_RemainingAmpHrCap
      FsftBPCR_t_HVBatRealTimeClock: server-com-spec=FsftBPCR_t_HVBatRealTimeClock, provided-interface=FsftBPCR_t_HVBatRealTimeClock
      FsftBPCR_t_HVBattCntctrOpnTm: server-com-spec=FsftBPCR_t_HVBattCntctrOpnTm, provided-interface=FsftBPCR_t_HVBattCntctrOpnTm
      PokeBPCR_Cnt_HVBatt_NumMaxVlt: server-com-spec{operation=PokeBPCR_Cnt_HVBatt_NumMaxVlt, queue-length=1}, provided-interface=PokeBPCR_Cnt_HVBatt_NumMaxVlt
      PokeBPCR_Cnt_HVBatt_NumMinVlt: server-com-spec{operation=PokeBPCR_Cnt_HVBatt_NumMinVlt, queue-length=1}, provided-interface=PokeBPCR_Cnt_HVBatt_NumMinVlt
      PokeBPCR_DC_CntctrCntrl_PWM: server-com-spec{operation=PokeBPCR_DC_CntctrCntrl_PWM, queue-length=1}, provided-interface=PokeBPCR_DC_CntctrCntrl_PWM
      PokeBPCR_I_HV_BatCurr: server-com-spec{operation=PokeBPCR_I_HV_BatCurr, queue-length=1}, provided-interface=PokeBPCR_I_HV_BatCurr
      PokeBPCR_I_HV_BatCurrString2: server-com-spec{operation=PokeBPCR_I_HV_BatCurrString2, queue-length=1}, provided-interface=PokeBPCR_I_HV_BatCurrString2
      PokeBPCR_I_MaxChgCurrAlwd: server-com-spec{operation=PokeBPCR_I_MaxChgCurrAlwd, queue-length=1}, provided-interface=PokeBPCR_I_MaxChgCurrAlwd
      PokeBPCR_I_MaxDisChgCurrAlwd: server-com-spec{operation=PokeBPCR_I_MaxDisChgCurrAlwd, queue-length=1}, provided-interface=PokeBPCR_I_MaxDisChgCurrAlwd
      PokeBPCR_P_HV_BatChrgPwrET: server-com-spec{operation=PokeBPCR_P_HV_BatChrgPwrET, queue-length=1}, provided-interface=PokeBPCR_P_HV_BatChrgPwrET
      PokeBPCR_P_HV_BatChrgPwrLT: server-com-spec{operation=PokeBPCR_P_HV_BatChrgPwrLT, queue-length=1}, provided-interface=PokeBPCR_P_HV_BatChrgPwrLT
      PokeBPCR_P_HV_BatChrgPwrST: server-com-spec{operation=PokeBPCR_P_HV_BatChrgPwrST, queue-length=1}, provided-interface=PokeBPCR_P_HV_BatChrgPwrST
      PokeBPCR_P_HV_BatDschrgPwrET: server-com-spec{operation=PokeBPCR_P_HV_BatDschrgPwrET, queue-length=1}, provided-interface=PokeBPCR_P_HV_BatDschrgPwrET
      PokeBPCR_P_HV_BatDschrgPwrLT: server-com-spec{operation=PokeBPCR_P_HV_BatDschrgPwrLT, queue-length=1}, provided-interface=PokeBPCR_P_HV_BatDschrgPwrLT
      PokeBPCR_P_HV_BatDschrgPwrST: server-com-spec{operation=PokeBPCR_P_HV_BatDschrgPwrST, queue-length=1}, provided-interface=PokeBPCR_P_HV_BatDschrgPwrST
      PokeBPCR_P_TracBat_EChrgPowLong: server-com-spec{operation=PokeBPCR_P_TracBat_EChrgPowLong, queue-length=1}, provided-interface=PokeBPCR_P_TracBat_EChrgPowLong
      PokeBPCR_Pct_ContctCntrlVerif: server-com-spec{operation=PokeBPCR_Pct_ContctCntrlVerif, queue-length=1}, provided-interface=PokeBPCR_Pct_ContctCntrlVerif
      PokeBPCR_Pct_HVBatSOH: server-com-spec{operation=PokeBPCR_Pct_HVBatSOH, queue-length=1}, provided-interface=PokeBPCR_Pct_HVBatSOH
      PokeBPCR_Pct_HVBatSOHLow: server-com-spec{operation=PokeBPCR_Pct_HVBatSOHLow, queue-length=1}, provided-interface=PokeBPCR_Pct_HVBatSOHLow
      PokeBPCR_Pct_HV_BatPackSOC: server-com-spec{operation=PokeBPCR_Pct_HV_BatPackSOC, queue-length=1}, provided-interface=PokeBPCR_Pct_HV_BatPackSOC
      PokeBPCR_R_HV_BatImped: server-com-spec{operation=PokeBPCR_R_HV_BatImped, queue-length=1}, provided-interface=PokeBPCR_R_HV_BatImped
      PokeBPCR_T_BDUBusBarTemp: server-com-spec{operation=PokeBPCR_T_BDUBusBarTemp, queue-length=1}, provided-interface=PokeBPCR_T_BDUBusBarTemp
      PokeBPCR_T_BusBarTemp: server-com-spec{operation=PokeBPCR_T_BusBarTemp, queue-length=1}, provided-interface=PokeBPCR_T_BusBarTemp
      PokeBPCR_T_HVBatClgOutletTemp: server-com-spec{operation=PokeBPCR_T_HVBatClgOutletTemp, queue-length=1}, provided-interface=PokeBPCR_T_HVBatClgOutletTemp
      PokeBPCR_T_HV_BatModTempAvg: server-com-spec{operation=PokeBPCR_T_HV_BatModTempAvg, queue-length=1}, provided-interface=PokeBPCR_T_HV_BatModTempAvg
      PokeBPCR_T_HV_BatModTempMax: server-com-spec{operation=PokeBPCR_T_HV_BatModTempMax, queue-length=1}, provided-interface=PokeBPCR_T_HV_BatModTempMax
      PokeBPCR_T_HV_BatModTempMin: server-com-spec{operation=PokeBPCR_T_HV_BatModTempMin, queue-length=1}, provided-interface=PokeBPCR_T_HV_BatModTempMin
      PokeBPCR_U_CellVoltHighThrsh: server-com-spec{operation=PokeBPCR_U_CellVoltHighThrsh, queue-length=1}, provided-interface=PokeBPCR_U_CellVoltHighThrsh
      PokeBPCR_U_CellVoltLowThrsh: server-com-spec{operation=PokeBPCR_U_CellVoltLowThrsh, queue-length=1}, provided-interface=PokeBPCR_U_CellVoltLowThrsh
      PokeBPCR_U_HV_BatModVoltAvg: server-com-spec{operation=PokeBPCR_U_HV_BatModVoltAvg, queue-length=1}, provided-interface=PokeBPCR_U_HV_BatModVoltAvg
      PokeBPCR_U_HV_BatModVoltMax: server-com-spec{operation=PokeBPCR_U_HV_BatModVoltMax, queue-length=1}, provided-interface=PokeBPCR_U_HV_BatModVoltMax
      PokeBPCR_U_HV_BatModVoltMin: server-com-spec{operation=PokeBPCR_U_HV_BatModVoltMin, queue-length=1}, provided-interface=PokeBPCR_U_HV_BatModVoltMin
      PokeBPCR_U_HV_BatVolt: server-com-spec{operation=PokeBPCR_U_HV_BatVolt, queue-length=1}, provided-interface=PokeBPCR_U_HV_BatVolt
      PokeBPCR_U_HV_InternalStringVolt1: server-com-spec{operation=PokeBPCR_U_HV_InternalStringVolt1, queue-length=1}, provided-interface=PokeBPCR_U_HV_InternalStringVolt1
      PokeBPCR_U_HV_InternalStringVolt2: server-com-spec{operation=PokeBPCR_U_HV_InternalStringVolt2, queue-length=1}, provided-interface=PokeBPCR_U_HV_InternalStringVolt2
      PokeBPCR_U_HV_InternalVolt: server-com-spec{operation=PokeBPCR_U_HV_InternalVolt, queue-length=1}, provided-interface=PokeBPCR_U_HV_InternalVolt
      PokeBPCR_U_HV_SeriesVolt: server-com-spec{operation=PokeBPCR_U_HV_SeriesVolt, queue-length=1}, provided-interface=PokeBPCR_U_HV_SeriesVolt
      PokeBPCR_U_MaxCellVltAlld: server-com-spec{operation=PokeBPCR_U_MaxCellVltAlld, queue-length=1}, provided-interface=PokeBPCR_U_MaxCellVltAlld
      PokeBPCR_U_MaxPkVltAlld: server-com-spec{operation=PokeBPCR_U_MaxPkVltAlld, queue-length=1}, provided-interface=PokeBPCR_U_MaxPkVltAlld
      PokeBPCR_U_MinCellVltAlld: server-com-spec{operation=PokeBPCR_U_MinCellVltAlld, queue-length=1}, provided-interface=PokeBPCR_U_MinCellVltAlld
      PokeBPCR_U_MinPkVltAlld: server-com-spec{operation=PokeBPCR_U_MinPkVltAlld, queue-length=1}, provided-interface=PokeBPCR_U_MinPkVltAlld
      PokeBPCR_U_OCVAveCellVoltage: server-com-spec{operation=PokeBPCR_U_OCVAveCellVoltage, queue-length=1}, provided-interface=PokeBPCR_U_OCVAveCellVoltage
      PokeBPCR_U_OCVMaxCellVoltage: server-com-spec{operation=PokeBPCR_U_OCVMaxCellVoltage, queue-length=1}, provided-interface=PokeBPCR_U_OCVMaxCellVoltage
      PokeBPCR_U_OCVMinCellVoltage: server-com-spec{operation=PokeBPCR_U_OCVMinCellVoltage, queue-length=1}, provided-interface=PokeBPCR_U_OCVMinCellVoltage
      PokeBPCR_U_OCVPckVoltage: server-com-spec{operation=PokeBPCR_U_OCVPckVoltage, queue-length=1}, provided-interface=PokeBPCR_U_OCVPckVoltage
      PokeBPCR_Z_MaxCellChargeImpedance: server-com-spec{operation=PokeBPCR_Z_MaxCellChargeImpedance, queue-length=1}, provided-interface=PokeBPCR_Z_MaxCellChargeImpedance
      PokeBPCR_Z_MaxCellDischargeImpedance: server-com-spec{operation=PokeBPCR_Z_MaxCellDischargeImpedance, queue-length=1}, provided-interface=PokeBPCR_Z_MaxCellDischargeImpedance
      PokeBPCR_Z_MinCellChargeImpedance: server-com-spec{operation=PokeBPCR_Z_MinCellChargeImpedance, queue-length=1}, provided-interface=PokeBPCR_Z_MinCellChargeImpedance
      PokeBPCR_Z_MinCellDischargeImpedance: server-com-spec{operation=PokeBPCR_Z_MinCellDischargeImpedance, queue-length=1}, provided-interface=PokeBPCR_Z_MinCellDischargeImpedance
      PokeBPCR_b_BalMd: server-com-spec{operation=PokeBPCR_b_BalMd, queue-length=1}, provided-interface=PokeBPCR_b_BalMd
      PokeBPCR_b_CellVoltImbalance: server-com-spec{operation=PokeBPCR_b_CellVoltImbalance, queue-length=1}, provided-interface=PokeBPCR_b_CellVoltImbalance
      PokeBPCR_b_ChrgFail_On_BPCM: server-com-spec{operation=PokeBPCR_b_ChrgFail_On_BPCM, queue-length=1}, provided-interface=PokeBPCR_b_ChrgFail_On_BPCM
      PokeBPCR_b_DC_Isolation_Sts: server-com-spec{operation=PokeBPCR_b_DC_Isolation_Sts, queue-length=1}, provided-interface=PokeBPCR_b_DC_Isolation_Sts
      PokeBPCR_b_EVSer_On_BPCM: server-com-spec{operation=PokeBPCR_b_EVSer_On_BPCM, queue-length=1}, provided-interface=PokeBPCR_b_EVSer_On_BPCM
      PokeBPCR_b_HBCNC_LV_LO: server-com-spec{operation=PokeBPCR_b_HBCNC_LV_LO, queue-length=1}, provided-interface=PokeBPCR_b_HBCNC_LV_LO
      PokeBPCR_b_HEVOnRqBPCM: server-com-spec{operation=PokeBPCR_b_HEVOnRqBPCM, queue-length=1}, provided-interface=PokeBPCR_b_HEVOnRqBPCM
      PokeBPCR_b_HVBatPerWU12VChrg: server-com-spec{operation=PokeBPCR_b_HVBatPerWU12VChrg, queue-length=1}, provided-interface=PokeBPCR_b_HVBatPerWU12VChrg
      PokeBPCR_b_HVBatPerWUBal: server-com-spec{operation=PokeBPCR_b_HVBatPerWUBal, queue-length=1}, provided-interface=PokeBPCR_b_HVBatPerWUBal
      PokeBPCR_b_HVBatPerWUCharge: server-com-spec{operation=PokeBPCR_b_HVBatPerWUCharge, queue-length=1}, provided-interface=PokeBPCR_b_HVBatPerWUCharge
      PokeBPCR_b_HVBatPerWUThermal: server-com-spec{operation=PokeBPCR_b_HVBatPerWUThermal, queue-length=1}, provided-interface=PokeBPCR_b_HVBatPerWUThermal
      PokeBPCR_b_HVBatRdy: server-com-spec{operation=PokeBPCR_b_HVBatRdy, queue-length=1}, provided-interface=PokeBPCR_b_HVBatRdy
      PokeBPCR_b_HVBatRdyForChrg: server-com-spec{operation=PokeBPCR_b_HVBatRdyForChrg, queue-length=1}, provided-interface=PokeBPCR_b_HVBatRdyForChrg
      PokeBPCR_b_HVBat_DC_CntctrOpn: server-com-spec{operation=PokeBPCR_b_HVBat_DC_CntctrOpn, queue-length=1}, provided-interface=PokeBPCR_b_HVBat_DC_CntctrOpn
      PokeBPCR_b_HVBat_DC_CntctrReq: server-com-spec{operation=PokeBPCR_b_HVBat_DC_CntctrReq, queue-length=1}, provided-interface=PokeBPCR_b_HVBat_DC_CntctrReq
      PokeBPCR_b_HVBat_Real_Time_Clock_V: server-com-spec{operation=PokeBPCR_b_HVBat_Real_Time_Clock_V, queue-length=1}, provided-interface=PokeBPCR_b_HVBat_Real_Time_Clock_V
      PokeBPCR_b_HVBattPerWakeUp: server-com-spec{operation=PokeBPCR_b_HVBattPerWakeUp, queue-length=1}, provided-interface=PokeBPCR_b_HVBattPerWakeUp
      PokeBPCR_b_HV_AuxLoadOffReq: server-com-spec{operation=PokeBPCR_b_HV_AuxLoadOffReq, queue-length=1}, provided-interface=PokeBPCR_b_HV_AuxLoadOffReq
      PokeBPCR_b_HV_BatCntctrOpenPending: server-com-spec{operation=PokeBPCR_b_HV_BatCntctrOpenPending, queue-length=1}, provided-interface=PokeBPCR_b_HV_BatCntctrOpenPending
      PokeBPCR_b_HV_BatCntctrOpenReq: server-com-spec{operation=PokeBPCR_b_HV_BatCntctrOpenReq, queue-length=1}, provided-interface=PokeBPCR_b_HV_BatCntctrOpenReq
      PokeBPCR_b_HV_BatDriveRdy: server-com-spec{operation=PokeBPCR_b_HV_BatDriveRdy, queue-length=1}, provided-interface=PokeBPCR_b_HV_BatDriveRdy
      PokeBPCR_b_MIL_OnRq_BPCM: server-com-spec{operation=PokeBPCR_b_MIL_OnRq_BPCM, queue-length=1}, provided-interface=PokeBPCR_b_MIL_OnRq_BPCM
      PokeBPCR_b_PwrLimON: server-com-spec{operation=PokeBPCR_b_PwrLimON, queue-length=1}, provided-interface=PokeBPCR_b_PwrLimON
      PokeBPCR_b_StkOpnChkCmpl: server-com-spec{operation=PokeBPCR_b_StkOpnChkCmpl, queue-length=1}, provided-interface=PokeBPCR_b_StkOpnChkCmpl
      PokeBPCR_cnt_BatteryModel: server-com-spec{operation=PokeBPCR_cnt_BatteryModel, queue-length=1}, provided-interface=PokeBPCR_cnt_BatteryModel
      PokeBPCR_cnt_HVBatt_ModNumMaxTmp: server-com-spec{operation=PokeBPCR_cnt_HVBatt_ModNumMaxTmp, queue-length=1}, provided-interface=PokeBPCR_cnt_HVBatt_ModNumMaxTmp
      PokeBPCR_cnt_HVBatt_ModNumMinTmp: server-com-spec{operation=PokeBPCR_cnt_HVBatt_ModNumMinTmp, queue-length=1}, provided-interface=PokeBPCR_cnt_HVBatt_ModNumMinTmp
      PokeBPCR_e_BPCMShtDwnRdy: server-com-spec{operation=PokeBPCR_e_BPCMShtDwnRdy, queue-length=1}, provided-interface=PokeBPCR_e_BPCMShtDwnRdy
      PokeBPCR_e_BPCM_Comm_Fail: server-com-spec{operation=PokeBPCR_e_BPCM_Comm_Fail, queue-length=1}, provided-interface=PokeBPCR_e_BPCM_Comm_Fail
      PokeBPCR_e_BPCM_LIN_BusOff: server-com-spec{operation=PokeBPCR_e_BPCM_LIN_BusOff, queue-length=1}, provided-interface=PokeBPCR_e_BPCM_LIN_BusOff
      PokeBPCR_e_BPCM_LOC_BCP: server-com-spec{operation=PokeBPCR_e_BPCM_LOC_BCP, queue-length=1}, provided-interface=PokeBPCR_e_BPCM_LOC_BCP
      PokeBPCR_e_BPCM_LOC_BatClntHtr: server-com-spec{operation=PokeBPCR_e_BPCM_LOC_BatClntHtr, queue-length=1}, provided-interface=PokeBPCR_e_BPCM_LOC_BatClntHtr
      PokeBPCR_e_ChargingStat_BPCM: server-com-spec{operation=PokeBPCR_e_ChargingStat_BPCM, queue-length=1}, provided-interface=PokeBPCR_e_ChargingStat_BPCM
      PokeBPCR_e_DCIsolSts: server-com-spec{operation=PokeBPCR_e_DCIsolSts, queue-length=1}, provided-interface=PokeBPCR_e_DCIsolSts
      PokeBPCR_e_HVBatCntrWeld_ImpdOpn: server-com-spec{operation=PokeBPCR_e_HVBatCntrWeld_ImpdOpn, queue-length=1}, provided-interface=PokeBPCR_e_HVBatCntrWeld_ImpdOpn
      PokeBPCR_e_HVBatIntrlkIntrnlStat: server-com-spec{operation=PokeBPCR_e_HVBatIntrlkIntrnlStat, queue-length=1}, provided-interface=PokeBPCR_e_HVBatIntrlkIntrnlStat
      PokeBPCR_e_HVBatPerWU_Rsn: server-com-spec{operation=PokeBPCR_e_HVBatPerWU_Rsn, queue-length=1}, provided-interface=PokeBPCR_e_HVBatPerWU_Rsn
      PokeBPCR_e_HVBat_DC_CntctrStat: server-com-spec{operation=PokeBPCR_e_HVBat_DC_CntctrStat, queue-length=1}, provided-interface=PokeBPCR_e_HVBat_DC_CntctrStat
      PokeBPCR_e_HV_BatCntctrStat: server-com-spec{operation=PokeBPCR_e_HV_BatCntctrStat, queue-length=1}, provided-interface=PokeBPCR_e_HV_BatCntctrStat
      PokeBPCR_e_HV_BatInrlkStat: server-com-spec{operation=PokeBPCR_e_HV_BatInrlkStat, queue-length=1}, provided-interface=PokeBPCR_e_HV_BatInrlkStat
      PokeBPCR_e_HV_BatIsolStat: server-com-spec{operation=PokeBPCR_e_HV_BatIsolStat, queue-length=1}, provided-interface=PokeBPCR_e_HV_BatIsolStat
      PokeBPCR_e_HV_DcChargeTypeStat: server-com-spec{operation=PokeBPCR_e_HV_DcChargeTypeStat, queue-length=1}, provided-interface=PokeBPCR_e_HV_DcChargeTypeStat
      PokeBPCR_e_HV_TracBatCntctrConfig: server-com-spec{operation=PokeBPCR_e_HV_TracBatCntctrConfig, queue-length=1}, provided-interface=PokeBPCR_e_HV_TracBatCntctrConfig
      PokeBPCR_e_PowerModeState: server-com-spec{operation=PokeBPCR_e_PowerModeState, queue-length=1}, provided-interface=PokeBPCR_e_PowerModeState
      PokeBPCR_e_PwrtrnHV_IsolStat: server-com-spec{operation=PokeBPCR_e_PwrtrnHV_IsolStat, queue-length=1}, provided-interface=PokeBPCR_e_PwrtrnHV_IsolStat
      PokeBPCR_e_ThrmlRnawy_Warn: server-com-spec{operation=PokeBPCR_e_ThrmlRnawy_Warn, queue-length=1}, provided-interface=PokeBPCR_e_ThrmlRnawy_Warn
      PokeBPCR_i_DC_Isolation_Sts_M182: server-com-spec{operation=PokeBPCR_i_DC_Isolation_Sts_M182, queue-length=1}, provided-interface=PokeBPCR_i_DC_Isolation_Sts_M182
      PokeBPCR_q_FullAmpHrCap: server-com-spec{operation=PokeBPCR_q_FullAmpHrCap, queue-length=1}, provided-interface=PokeBPCR_q_FullAmpHrCap
      PokeBPCR_q_RemainingAmpHrCap: server-com-spec{operation=PokeBPCR_q_RemainingAmpHrCap, queue-length=1}, provided-interface=PokeBPCR_q_RemainingAmpHrCap
      PokeBPCR_t_BSW_PWMCntctrTmr: server-com-spec{operation=PokeBPCR_t_BSW_PWMCntctrTmr, queue-length=1}, provided-interface=PokeBPCR_t_BSW_PWMCntctrTmr
      PokeBPCR_t_HVBatRealTimeClock: server-com-spec{operation=PokeBPCR_t_HVBatRealTimeClock, queue-length=1}, provided-interface=PokeBPCR_t_HVBatRealTimeClock
      PokeBPCR_t_HVBatSleepTime: server-com-spec{operation=PokeBPCR_t_HVBatSleepTime, queue-length=1}, provided-interface=PokeBPCR_t_HVBatSleepTime
      PokeBPCR_t_HVBattCntctrOpnTm: server-com-spec{operation=PokeBPCR_t_HVBattCntctrOpnTm, queue-length=1}, provided-interface=PokeBPCR_t_HVBattCntctrOpnTm
      PokeBPCR_t_PrechrgPnltyTimer: server-com-spec{operation=PokeBPCR_t_PrechrgPnltyTimer, queue-length=1}, provided-interface=PokeBPCR_t_PrechrgPnltyTimer
      TmotBPCR_b_HVBatCntrWeld_ImpdOpn: server-com-spec=TmotBPCR_b_HVBatCntrWeld_ImpdOpn, provided-interface=TmotBPCR_b_HVBatCntrWeld_ImpdOpn
      TmotBPCR_b_HVBatRdy: server-com-spec=TmotBPCR_b_HVBatRdy, provided-interface=TmotBPCR_b_HVBatRdy
      TmotBPCR_b_HV_BatChrgPwrET: server-com-spec=TmotBPCR_b_HV_BatChrgPwrET, provided-interface=TmotBPCR_b_HV_BatChrgPwrET
      TmotBPCR_b_HV_BatChrgPwrLT: server-com-spec=TmotBPCR_b_HV_BatChrgPwrLT, provided-interface=TmotBPCR_b_HV_BatChrgPwrLT
      TmotBPCR_b_HV_BatChrgPwrST: server-com-spec=TmotBPCR_b_HV_BatChrgPwrST, provided-interface=TmotBPCR_b_HV_BatChrgPwrST
      TmotBPCR_b_HV_BatDschrgPwrET: server-com-spec=TmotBPCR_b_HV_BatDschrgPwrET, provided-interface=TmotBPCR_b_HV_BatDschrgPwrET
      TmotBPCR_b_HV_BatDschrgPwrLT: server-com-spec=TmotBPCR_b_HV_BatDschrgPwrLT, provided-interface=TmotBPCR_b_HV_BatDschrgPwrLT
      TmotBPCR_b_HV_BatDschrgPwrST: server-com-spec=TmotBPCR_b_HV_BatDschrgPwrST, provided-interface=TmotBPCR_b_HV_BatDschrgPwrST
      TmotBPCR_b_HV_BatModTempAvg: server-com-spec=TmotBPCR_b_HV_BatModTempAvg, provided-interface=TmotBPCR_b_HV_BatModTempAvg
      TmotBPCR_b_HV_BatModTempMax: server-com-spec=TmotBPCR_b_HV_BatModTempMax, provided-interface=TmotBPCR_b_HV_BatModTempMax
      TmotBPCR_b_HV_BatModTempMin: server-com-spec=TmotBPCR_b_HV_BatModTempMin, provided-interface=TmotBPCR_b_HV_BatModTempMin
      TmotBPCR_b_HV_BatPackSOC: server-com-spec=TmotBPCR_b_HV_BatPackSOC, provided-interface=TmotBPCR_b_HV_BatPackSOC
      TmotBPCR_e_BPCM_LIN_BusOff: server-com-spec=TmotBPCR_e_BPCM_LIN_BusOff, provided-interface=TmotBPCR_e_BPCM_LIN_BusOff
      TmotBPCR_e_BPCM_LOC_BCP: server-com-spec=TmotBPCR_e_BPCM_LOC_BCP, provided-interface=TmotBPCR_e_BPCM_LOC_BCP
      TmotBPCR_e_BPCM_LOC_BatClntHtr: server-com-spec=TmotBPCR_e_BPCM_LOC_BatClntHtr, provided-interface=TmotBPCR_e_BPCM_LOC_BatClntHtr
    11 x require port:
      NeBPCR_T_BatModTmp_Rx: nv-require-com-spec{init-value=-100, variable=NeBPCR_T_BatModTmp}, required-interface=NeBPCR_T_BatModTmp
      DeBPCR_P_HV_BatDschrgPwrST_Rx: nv-require-com-spec{init-value=-100, variable=DeBPCR_P_HV_BatDschrgPwrST}, required-interface=DeBPCR_P_HV_BatDschrgPwrST
      NeBPCR_b_HV_BatRdy_Rx: nv-require-com-spec{init-value=0, variable=NeBPCR_b_HV_BatRdy}, required-interface=NeBPCR_b_HV_BatRdy
      NeBPCR_b_HV_BatPackSOC_FA_Ovrd_Rx: nv-require-com-spec{init-value=0, variable=NeBPCR_b_HV_BatPackSOC_FA_Ovrd}, required-interface=NeBPCR_b_HV_BatPackSOC_FA_Ovrd
      DeBPCR_Pct_HV_BatSOC_DS_Rx: nv-require-com-spec{init-value=-100, variable=DeBPCR_Pct_HV_BatSOC_DS}, required-interface=DeBPCR_Pct_HV_BatSOC_DS
      DeBPCR_P_HV_BatChrgPwrST_Rx: nv-require-com-spec{init-value=-100, variable=DeBPCR_P_HV_BatChrgPwrST}, required-interface=DeBPCR_P_HV_BatChrgPwrST
      DeBPCR_P_HV_BatChrgPwrET_Rx: nv-require-com-spec{init-value=-100, variable=DeBPCR_P_HV_BatChrgPwrET}, required-interface=DeBPCR_P_HV_BatChrgPwrET
      DeBPCR_P_HV_BatChrgPwrLT_Rx: nv-require-com-spec{init-value=-100, variable=DeBPCR_P_HV_BatChrgPwrLT}, required-interface=DeBPCR_P_HV_BatChrgPwrLT
      DeBPCR_P_HV_BatDschrgPwrLT_Rx: nv-require-com-spec{init-value=-100, variable=DeBPCR_P_HV_BatDschrgPwrLT}, required-interface=DeBPCR_P_HV_BatDschrgPwrLT
      DeBPCR_P_HV_BatDschrgPwrET_Rx: nv-require-com-spec{init-value=-100, variable=DeBPCR_P_HV_BatDschrgPwrET}, required-interface=DeBPCR_P_HV_BatDschrgPwrET
      NeBPCR_Cnt_PWMCntctrStMFOP_Rx: nv-require-com-spec{init-value=0, variable=NeBPCR_Cnt_PWMCntctrStMFOP}, required-interface=NeBPCR_Cnt_PWMCntctrStMFOP
    11 x provide port:
      NeBPCR_T_BatModTmp: nv-provide-com-spec{ram-block-init-value=-100, variable=NeBPCR_T_BatModTmp}, provided-interface=NeBPCR_T_BatModTmp
      DeBPCR_P_HV_BatDschrgPwrST: nv-provide-com-spec{ram-block-init-value=-100, variable=DeBPCR_P_HV_BatDschrgPwrST}, provided-interface=DeBPCR_P_HV_BatDschrgPwrST
      NeBPCR_b_HV_BatRdy: nv-provide-com-spec{ram-block-init-value=0, variable=NeBPCR_b_HV_BatRdy}, provided-interface=NeBPCR_b_HV_BatRdy
      NeBPCR_b_HV_BatPackSOC_FA_Ovrd: nv-provide-com-spec{ram-block-init-value=0, variable=NeBPCR_b_HV_BatPackSOC_FA_Ovrd}, provided-interface=NeBPCR_b_HV_BatPackSOC_FA_Ovrd
      DeBPCR_Pct_HV_BatSOC_DS: nv-provide-com-spec{ram-block-init-value=-100, variable=DeBPCR_Pct_HV_BatSOC_DS}, provided-interface=DeBPCR_Pct_HV_BatSOC_DS
      DeBPCR_P_HV_BatChrgPwrST: nv-provide-com-spec{ram-block-init-value=-100, variable=DeBPCR_P_HV_BatChrgPwrST}, provided-interface=DeBPCR_P_HV_BatChrgPwrST
      DeBPCR_P_HV_BatChrgPwrET: nv-provide-com-spec{ram-block-init-value=-100, variable=DeBPCR_P_HV_BatChrgPwrET}, provided-interface=DeBPCR_P_HV_BatChrgPwrET
      DeBPCR_P_HV_BatChrgPwrLT: nv-provide-com-spec{ram-block-init-value=-100, variable=DeBPCR_P_HV_BatChrgPwrLT}, provided-interface=DeBPCR_P_HV_BatChrgPwrLT
      DeBPCR_P_HV_BatDschrgPwrLT: nv-provide-com-spec{ram-block-init-value=-100, variable=DeBPCR_P_HV_BatDschrgPwrLT}, provided-interface=DeBPCR_P_HV_BatDschrgPwrLT
      DeBPCR_P_HV_BatDschrgPwrET: nv-provide-com-spec{ram-block-init-value=-100, variable=DeBPCR_P_HV_BatDschrgPwrET}, provided-interface=DeBPCR_P_HV_BatDschrgPwrET
      NeBPCR_Cnt_PWMCntctrStMFOP: nv-provide-com-spec{ram-block-init-value=0, variable=NeBPCR_Cnt_PWMCntctrStMFOP}, provided-interface=NeBPCR_Cnt_PWMCntctrStMFOP
    behavior IB_BPCR: data-type-mapping=msADTtoIDTMapping, handle-termination-and-restart=NO-SUPPORT
      timing event Event_FastTEF: start-on-event=BPCR_FastTEF, period=0.005
      timing event Event_MedTEB: start-on-event=BPCR_MedTEB, period=0.01
      timing event Event_MedTEH: start-on-event=BPCR_MedTEH, period=0.1
      173 x operation invoked event:
        Event_FsftBPCR_I_HV_BatCurr: start-on-event=FsftBPCR_I_HV_BatCurr, operation=FsftBPCR_I_HV_BatCurr.FsftBPCR_I_HV_BatCurr
        Event_FsftBPCR_I_MaxChgCurrAlwd: start-on-event=FsftBPCR_I_MaxChgCurrAlwd, operation=FsftBPCR_I_MaxChgCurrAlwd.FsftBPCR_I_MaxChgCurrAlwd
        Event_FsftBPCR_P_TracBat_EChrgPowLong: start-on-event=FsftBPCR_P_TracBat_EChrgPowLong, operation=FsftBPCR_P_TracBat_EChrgPowLong.FsftBPCR_P_TracBat_EChrgPowLong
        Event_FsftBPCR_R_HV_BatImped: start-on-event=FsftBPCR_R_HV_BatImped, operation=FsftBPCR_R_HV_BatImped.FsftBPCR_R_HV_BatImped
        Event_FsftBPCR_U_CellVoltHighThrsh: start-on-event=FsftBPCR_U_CellVoltHighThrsh, operation=FsftBPCR_U_CellVoltHighThrsh.FsftBPCR_U_CellVoltHighThrsh
        Event_FsftBPCR_U_CellVoltLowThrsh: start-on-event=FsftBPCR_U_CellVoltLowThrsh, operation=FsftBPCR_U_CellVoltLowThrsh.FsftBPCR_U_CellVoltLowThrsh
        Event_FsftBPCR_U_HV_BatModVoltAvg: start-on-event=FsftBPCR_U_HV_BatModVoltAvg, operation=FsftBPCR_U_HV_BatModVoltAvg.FsftBPCR_U_HV_BatModVoltAvg
        Event_FsftBPCR_U_HV_BatModVoltMax: start-on-event=FsftBPCR_U_HV_BatModVoltMax, operation=FsftBPCR_U_HV_BatModVoltMax.FsftBPCR_U_HV_BatModVoltMax
        Event_FsftBPCR_U_HV_BatModVoltMin: start-on-event=FsftBPCR_U_HV_BatModVoltMin, operation=FsftBPCR_U_HV_BatModVoltMin.FsftBPCR_U_HV_BatModVoltMin
        Event_FsftBPCR_U_HV_BatVolt: start-on-event=FsftBPCR_U_HV_BatVolt, operation=FsftBPCR_U_HV_BatVolt.FsftBPCR_U_HV_BatVolt
        Event_FsftBPCR_U_MaxCellVltAlld: start-on-event=FsftBPCR_U_MaxCellVltAlld, operation=FsftBPCR_U_MaxCellVltAlld.FsftBPCR_U_MaxCellVltAlld
        Event_FsftBPCR_U_MaxPkVltAlld: start-on-event=FsftBPCR_U_MaxPkVltAlld, operation=FsftBPCR_U_MaxPkVltAlld.FsftBPCR_U_MaxPkVltAlld
        Event_FsftBPCR_U_MinCellVltAlld: start-on-event=FsftBPCR_U_MinCellVltAlld, operation=FsftBPCR_U_MinCellVltAlld.FsftBPCR_U_MinCellVltAlld
        Event_FsftBPCR_U_MinPkVltAlld: start-on-event=FsftBPCR_U_MinPkVltAlld, operation=FsftBPCR_U_MinPkVltAlld.FsftBPCR_U_MinPkVltAlld
        Event_FsftBPCR_U_OCVAveCellVoltage: start-on-event=FsftBPCR_U_OCVAveCellVoltage, operation=FsftBPCR_U_OCVAveCellVoltage.FsftBPCR_U_OCVAveCellVoltage
        Event_FsftBPCR_U_OCVMaxCellVoltage: start-on-event=FsftBPCR_U_OCVMaxCellVoltage, operation=FsftBPCR_U_OCVMaxCellVoltage.FsftBPCR_U_OCVMaxCellVoltage
        Event_FsftBPCR_U_OCVMinCellVoltage: start-on-event=FsftBPCR_U_OCVMinCellVoltage, operation=FsftBPCR_U_OCVMinCellVoltage.FsftBPCR_U_OCVMinCellVoltage
        Event_FsftBPCR_Z_MaxCellDischargeImpedance: start-on-event=FsftBPCR_Z_MaxCellDischargeImpedance, operation=FsftBPCR_Z_MaxCellDischargeImpedance.FsftBPCR_Z_MaxCellDischargeImpedance
        Event_FsftBPCR_Z_MinCellDischargeImpedance: start-on-event=FsftBPCR_Z_MinCellDischargeImpedance, operation=FsftBPCR_Z_MinCellDischargeImpedance.FsftBPCR_Z_MinCellDischargeImpedance
        Event_FsftBPCR_b_BPCM_LIN_BusOff: start-on-event=FsftBPCR_b_BPCM_LIN_BusOff, operation=FsftBPCR_b_BPCM_LIN_BusOff.FsftBPCR_b_BPCM_LIN_BusOff
        Event_FsftBPCR_b_BPCM_LOC_BCP: start-on-event=FsftBPCR_b_BPCM_LOC_BCP, operation=FsftBPCR_b_BPCM_LOC_BCP.FsftBPCR_b_BPCM_LOC_BCP
        Event_FsftBPCR_b_BPCM_LOC_BatClntHtr: start-on-event=FsftBPCR_b_BPCM_LOC_BatClntHtr, operation=FsftBPCR_b_BPCM_LOC_BatClntHtr.FsftBPCR_b_BPCM_LOC_BatClntHtr
        Event_FsftBPCR_b_HVBatCntrWeld_ImpdOpn: start-on-event=FsftBPCR_b_HVBatCntrWeld_ImpdOpn, operation=FsftBPCR_b_HVBatCntrWeld_ImpdOpn.FsftBPCR_b_HVBatCntrWeld_ImpdOpn
        Event_FsftBPCR_b_HVBatRdy: start-on-event=FsftBPCR_b_HVBatRdy, operation=FsftBPCR_b_HVBatRdy.FsftBPCR_b_HVBatRdy
        Event_FsftBPCR_b_HVBat_DC_CntctrStat: start-on-event=FsftBPCR_b_HVBat_DC_CntctrStat, operation=FsftBPCR_b_HVBat_DC_CntctrStat.FsftBPCR_b_HVBat_DC_CntctrStat
        Event_FsftBPCR_b_HV_AuxLoadOffReq: start-on-event=FsftBPCR_b_HV_AuxLoadOffReq, operation=FsftBPCR_b_HV_AuxLoadOffReq.FsftBPCR_b_HV_AuxLoadOffReq
        Event_FsftBPCR_b_HV_BatChrgPwrET: start-on-event=FsftBPCR_b_HV_BatChrgPwrET, operation=FsftBPCR_b_HV_BatChrgPwrET.FsftBPCR_b_HV_BatChrgPwrET
        Event_FsftBPCR_b_HV_BatChrgPwrLT: start-on-event=FsftBPCR_b_HV_BatChrgPwrLT, operation=FsftBPCR_b_HV_BatChrgPwrLT.FsftBPCR_b_HV_BatChrgPwrLT
        Event_FsftBPCR_b_HV_BatChrgPwrST: start-on-event=FsftBPCR_b_HV_BatChrgPwrST, operation=FsftBPCR_b_HV_BatChrgPwrST.FsftBPCR_b_HV_BatChrgPwrST
        Event_FsftBPCR_b_HV_BatCurrString2: start-on-event=FsftBPCR_b_HV_BatCurrString2, operation=FsftBPCR_b_HV_BatCurrString2.FsftBPCR_b_HV_BatCurrString2
        Event_FsftBPCR_b_HV_BatDschrgPwrET: start-on-event=FsftBPCR_b_HV_BatDschrgPwrET, operation=FsftBPCR_b_HV_BatDschrgPwrET.FsftBPCR_b_HV_BatDschrgPwrET
        Event_FsftBPCR_b_HV_BatDschrgPwrLT: start-on-event=FsftBPCR_b_HV_BatDschrgPwrLT, operation=FsftBPCR_b_HV_BatDschrgPwrLT.FsftBPCR_b_HV_BatDschrgPwrLT
        Event_FsftBPCR_b_HV_BatDschrgPwrST: start-on-event=FsftBPCR_b_HV_BatDschrgPwrST, operation=FsftBPCR_b_HV_BatDschrgPwrST.FsftBPCR_b_HV_BatDschrgPwrST
        Event_FsftBPCR_b_HV_BatModTempAvg: start-on-event=FsftBPCR_b_HV_BatModTempAvg, operation=FsftBPCR_b_HV_BatModTempAvg.FsftBPCR_b_HV_BatModTempAvg
        Event_FsftBPCR_b_HV_BatModTempMax: start-on-event=FsftBPCR_b_HV_BatModTempMax, operation=FsftBPCR_b_HV_BatModTempMax.FsftBPCR_b_HV_BatModTempMax
        Event_FsftBPCR_b_HV_BatModTempMin: start-on-event=FsftBPCR_b_HV_BatModTempMin, operation=FsftBPCR_b_HV_BatModTempMin.FsftBPCR_b_HV_BatModTempMin
        Event_FsftBPCR_b_HV_BatPackSOC: start-on-event=FsftBPCR_b_HV_BatPackSOC, operation=FsftBPCR_b_HV_BatPackSOC.FsftBPCR_b_HV_BatPackSOC
        Event_FsftBPCR_b_HV_DcChargeTypeStat: start-on-event=FsftBPCR_b_HV_DcChargeTypeStat, operation=FsftBPCR_b_HV_DcChargeTypeStat.FsftBPCR_b_HV_DcChargeTypeStat
        Event_FsftBPCR_b_HV_InternalStringVolt1: start-on-event=FsftBPCR_b_HV_InternalStringVolt1, operation=FsftBPCR_b_HV_InternalStringVolt1.FsftBPCR_b_HV_InternalStringVolt1
        Event_FsftBPCR_b_HV_InternalStringVolt2: start-on-event=FsftBPCR_b_HV_InternalStringVolt2, operation=FsftBPCR_b_HV_InternalStringVolt2.FsftBPCR_b_HV_InternalStringVolt2
        Event_FsftBPCR_b_HV_InternalVolt: start-on-event=FsftBPCR_b_HV_InternalVolt, operation=FsftBPCR_b_HV_InternalVolt.FsftBPCR_b_HV_InternalVolt
        Event_FsftBPCR_b_HV_SeriesVolt: start-on-event=FsftBPCR_b_HV_SeriesVolt, operation=FsftBPCR_b_HV_SeriesVolt.FsftBPCR_b_HV_SeriesVolt
        Event_FsftBPCR_b_HV_TracBatCntctrConfig: start-on-event=FsftBPCR_b_HV_TracBatCntctrConfig, operation=FsftBPCR_b_HV_TracBatCntctrConfig.FsftBPCR_b_HV_TracBatCntctrConfig
        Event_FsftBPCR_b_ThrmlRnawy_Warn: start-on-event=FsftBPCR_b_ThrmlRnawy_Warn, operation=FsftBPCR_b_ThrmlRnawy_Warn.FsftBPCR_b_ThrmlRnawy_Warn
        Event_FsftBPCR_cnt_HVBatt_ModNumMaxTmp: start-on-event=FsftBPCR_cnt_HVBatt_ModNumMaxTmp, operation=FsftBPCR_cnt_HVBatt_ModNumMaxTmp.FsftBPCR_cnt_HVBatt_ModNumMaxTmp
        Event_FsftBPCR_cnt_HVBatt_ModNumMinTmp: start-on-event=FsftBPCR_cnt_HVBatt_ModNumMinTmp, operation=FsftBPCR_cnt_HVBatt_ModNumMinTmp.FsftBPCR_cnt_HVBatt_ModNumMinTmp
        Event_FsftBPCR_e_BPCM_Comm_Fail: start-on-event=FsftBPCR_e_BPCM_Comm_Fail, operation=FsftBPCR_e_BPCM_Comm_Fail.FsftBPCR_e_BPCM_Comm_Fail
        Event_FsftBPCR_e_ChargingStat_BPCM: start-on-event=FsftBPCR_e_ChargingStat_BPCM, operation=FsftBPCR_e_ChargingStat_BPCM.FsftBPCR_e_ChargingStat_BPCM
        Event_FsftBPCR_e_DCIsolSts: start-on-event=FsftBPCR_e_DCIsolSts, operation=FsftBPCR_e_DCIsolSts.FsftBPCR_e_DCIsolSts
        Event_FsftBPCR_e_HVBatIntrlkIntrnlStat: start-on-event=FsftBPCR_e_HVBatIntrlkIntrnlStat, operation=FsftBPCR_e_HVBatIntrlkIntrnlStat.FsftBPCR_e_HVBatIntrlkIntrnlStat
        Event_FsftBPCR_e_HV_BatCntctrStat: start-on-event=FsftBPCR_e_HV_BatCntctrStat, operation=FsftBPCR_e_HV_BatCntctrStat.FsftBPCR_e_HV_BatCntctrStat
        Event_FsftBPCR_e_HV_BatInrlkStat: start-on-event=FsftBPCR_e_HV_BatInrlkStat, operation=FsftBPCR_e_HV_BatInrlkStat.FsftBPCR_e_HV_BatInrlkStat
        Event_FsftBPCR_e_HV_BatIsolStat: start-on-event=FsftBPCR_e_HV_BatIsolStat, operation=FsftBPCR_e_HV_BatIsolStat.FsftBPCR_e_HV_BatIsolStat
        Event_FsftBPCR_q_FullAmpHrCap: start-on-event=FsftBPCR_q_FullAmpHrCap, operation=FsftBPCR_q_FullAmpHrCap.FsftBPCR_q_FullAmpHrCap
        Event_FsftBPCR_q_RemainingAmpHrCap: start-on-event=FsftBPCR_q_RemainingAmpHrCap, operation=FsftBPCR_q_RemainingAmpHrCap.FsftBPCR_q_RemainingAmpHrCap
        Event_FsftBPCR_t_HVBatRealTimeClock: start-on-event=FsftBPCR_t_HVBatRealTimeClock, operation=FsftBPCR_t_HVBatRealTimeClock.FsftBPCR_t_HVBatRealTimeClock
        Event_FsftBPCR_t_HVBattCntctrOpnTm: start-on-event=FsftBPCR_t_HVBattCntctrOpnTm, operation=FsftBPCR_t_HVBattCntctrOpnTm.FsftBPCR_t_HVBattCntctrOpnTm
        Event_PokeBPCR_Cnt_HVBatt_NumMaxVlt: start-on-event=PokeBPCR_Cnt_HVBatt_NumMaxVlt, operation=PokeBPCR_Cnt_HVBatt_NumMaxVlt.PokeBPCR_Cnt_HVBatt_NumMaxVlt
        Event_PokeBPCR_Cnt_HVBatt_NumMinVlt: start-on-event=PokeBPCR_Cnt_HVBatt_NumMinVlt, operation=PokeBPCR_Cnt_HVBatt_NumMinVlt.PokeBPCR_Cnt_HVBatt_NumMinVlt
        Event_PokeBPCR_DC_CntctrCntrl_PWM: start-on-event=PokeBPCR_DC_CntctrCntrl_PWM, operation=PokeBPCR_DC_CntctrCntrl_PWM.PokeBPCR_DC_CntctrCntrl_PWM
        Event_PokeBPCR_I_HV_BatCurr: start-on-event=PokeBPCR_I_HV_BatCurr, operation=PokeBPCR_I_HV_BatCurr.PokeBPCR_I_HV_BatCurr
        Event_PokeBPCR_I_HV_BatCurrString2: start-on-event=PokeBPCR_I_HV_BatCurrString2, operation=PokeBPCR_I_HV_BatCurrString2.PokeBPCR_I_HV_BatCurrString2
        Event_PokeBPCR_I_MaxChgCurrAlwd: start-on-event=PokeBPCR_I_MaxChgCurrAlwd, operation=PokeBPCR_I_MaxChgCurrAlwd.PokeBPCR_I_MaxChgCurrAlwd
        Event_PokeBPCR_I_MaxDisChgCurrAlwd: start-on-event=PokeBPCR_I_MaxDisChgCurrAlwd, operation=PokeBPCR_I_MaxDisChgCurrAlwd.PokeBPCR_I_MaxDisChgCurrAlwd
        Event_PokeBPCR_P_HV_BatChrgPwrET: start-on-event=PokeBPCR_P_HV_BatChrgPwrET, operation=PokeBPCR_P_HV_BatChrgPwrET.PokeBPCR_P_HV_BatChrgPwrET
        Event_PokeBPCR_P_HV_BatChrgPwrLT: start-on-event=PokeBPCR_P_HV_BatChrgPwrLT, operation=PokeBPCR_P_HV_BatChrgPwrLT.PokeBPCR_P_HV_BatChrgPwrLT
        Event_PokeBPCR_P_HV_BatChrgPwrST: start-on-event=PokeBPCR_P_HV_BatChrgPwrST, operation=PokeBPCR_P_HV_BatChrgPwrST.PokeBPCR_P_HV_BatChrgPwrST
        Event_PokeBPCR_P_HV_BatDschrgPwrET: start-on-event=PokeBPCR_P_HV_BatDschrgPwrET, operation=PokeBPCR_P_HV_BatDschrgPwrET.PokeBPCR_P_HV_BatDschrgPwrET
        Event_PokeBPCR_P_HV_BatDschrgPwrLT: start-on-event=PokeBPCR_P_HV_BatDschrgPwrLT, operation=PokeBPCR_P_HV_BatDschrgPwrLT.PokeBPCR_P_HV_BatDschrgPwrLT
        Event_PokeBPCR_P_HV_BatDschrgPwrST: start-on-event=PokeBPCR_P_HV_BatDschrgPwrST, operation=PokeBPCR_P_HV_BatDschrgPwrST.PokeBPCR_P_HV_BatDschrgPwrST
        Event_PokeBPCR_P_TracBat_EChrgPowLong: start-on-event=PokeBPCR_P_TracBat_EChrgPowLong, operation=PokeBPCR_P_TracBat_EChrgPowLong.PokeBPCR_P_TracBat_EChrgPowLong
        Event_PokeBPCR_Pct_ContctCntrlVerif: start-on-event=PokeBPCR_Pct_ContctCntrlVerif, operation=PokeBPCR_Pct_ContctCntrlVerif.PokeBPCR_Pct_ContctCntrlVerif
        Event_PokeBPCR_Pct_HVBatSOH: start-on-event=PokeBPCR_Pct_HVBatSOH, operation=PokeBPCR_Pct_HVBatSOH.PokeBPCR_Pct_HVBatSOH
        Event_PokeBPCR_Pct_HVBatSOHLow: start-on-event=PokeBPCR_Pct_HVBatSOHLow, operation=PokeBPCR_Pct_HVBatSOHLow.PokeBPCR_Pct_HVBatSOHLow
        Event_PokeBPCR_Pct_HV_BatPackSOC: start-on-event=PokeBPCR_Pct_HV_BatPackSOC, operation=PokeBPCR_Pct_HV_BatPackSOC.PokeBPCR_Pct_HV_BatPackSOC
        Event_PokeBPCR_R_HV_BatImped: start-on-event=PokeBPCR_R_HV_BatImped, operation=PokeBPCR_R_HV_BatImped.PokeBPCR_R_HV_BatImped
        Event_PokeBPCR_T_BDUBusBarTemp: start-on-event=PokeBPCR_T_BDUBusBarTemp, operation=PokeBPCR_T_BDUBusBarTemp.PokeBPCR_T_BDUBusBarTemp
        Event_PokeBPCR_T_BusBarTemp: start-on-event=PokeBPCR_T_BusBarTemp, operation=PokeBPCR_T_BusBarTemp.PokeBPCR_T_BusBarTemp
        Event_PokeBPCR_T_HVBatClgOutletTemp: start-on-event=PokeBPCR_T_HVBatClgOutletTemp, operation=PokeBPCR_T_HVBatClgOutletTemp.PokeBPCR_T_HVBatClgOutletTemp
        Event_PokeBPCR_T_HV_BatModTempAvg: start-on-event=PokeBPCR_T_HV_BatModTempAvg, operation=PokeBPCR_T_HV_BatModTempAvg.PokeBPCR_T_HV_BatModTempAvg
        Event_PokeBPCR_T_HV_BatModTempMax: start-on-event=PokeBPCR_T_HV_BatModTempMax, operation=PokeBPCR_T_HV_BatModTempMax.PokeBPCR_T_HV_BatModTempMax
        Event_PokeBPCR_T_HV_BatModTempMin: start-on-event=PokeBPCR_T_HV_BatModTempMin, operation=PokeBPCR_T_HV_BatModTempMin.PokeBPCR_T_HV_BatModTempMin
        Event_PokeBPCR_U_CellVoltHighThrsh: start-on-event=PokeBPCR_U_CellVoltHighThrsh, operation=PokeBPCR_U_CellVoltHighThrsh.PokeBPCR_U_CellVoltHighThrsh
        Event_PokeBPCR_U_CellVoltLowThrsh: start-on-event=PokeBPCR_U_CellVoltLowThrsh, operation=PokeBPCR_U_CellVoltLowThrsh.PokeBPCR_U_CellVoltLowThrsh
        Event_PokeBPCR_U_HV_BatModVoltAvg: start-on-event=PokeBPCR_U_HV_BatModVoltAvg, operation=PokeBPCR_U_HV_BatModVoltAvg.PokeBPCR_U_HV_BatModVoltAvg
        Event_PokeBPCR_U_HV_BatModVoltMax: start-on-event=PokeBPCR_U_HV_BatModVoltMax, operation=PokeBPCR_U_HV_BatModVoltMax.PokeBPCR_U_HV_BatModVoltMax
        Event_PokeBPCR_U_HV_BatModVoltMin: start-on-event=PokeBPCR_U_HV_BatModVoltMin, operation=PokeBPCR_U_HV_BatModVoltMin.PokeBPCR_U_HV_BatModVoltMin
        Event_PokeBPCR_U_HV_BatVolt: start-on-event=PokeBPCR_U_HV_BatVolt, operation=PokeBPCR_U_HV_BatVolt.PokeBPCR_U_HV_BatVolt
        Event_PokeBPCR_U_HV_InternalStringVolt1: start-on-event=PokeBPCR_U_HV_InternalStringVolt1, operation=PokeBPCR_U_HV_InternalStringVolt1.PokeBPCR_U_HV_InternalStringVolt1
        Event_PokeBPCR_U_HV_InternalStringVolt2: start-on-event=PokeBPCR_U_HV_InternalStringVolt2, operation=PokeBPCR_U_HV_InternalStringVolt2.PokeBPCR_U_HV_InternalStringVolt2
        Event_PokeBPCR_U_HV_InternalVolt: start-on-event=PokeBPCR_U_HV_InternalVolt, operation=PokeBPCR_U_HV_InternalVolt.PokeBPCR_U_HV_InternalVolt
        Event_PokeBPCR_U_HV_SeriesVolt: start-on-event=PokeBPCR_U_HV_SeriesVolt, operation=PokeBPCR_U_HV_SeriesVolt.PokeBPCR_U_HV_SeriesVolt
        Event_PokeBPCR_U_MaxCellVltAlld: start-on-event=PokeBPCR_U_MaxCellVltAlld, operation=PokeBPCR_U_MaxCellVltAlld.PokeBPCR_U_MaxCellVltAlld
        Event_PokeBPCR_U_MaxPkVltAlld: start-on-event=PokeBPCR_U_MaxPkVltAlld, operation=PokeBPCR_U_MaxPkVltAlld.PokeBPCR_U_MaxPkVltAlld
        Event_PokeBPCR_U_MinCellVltAlld: start-on-event=PokeBPCR_U_MinCellVltAlld, operation=PokeBPCR_U_MinCellVltAlld.PokeBPCR_U_MinCellVltAlld
        Event_PokeBPCR_U_MinPkVltAlld: start-on-event=PokeBPCR_U_MinPkVltAlld, operation=PokeBPCR_U_MinPkVltAlld.PokeBPCR_U_MinPkVltAlld
        Event_PokeBPCR_U_OCVAveCellVoltage: start-on-event=PokeBPCR_U_OCVAveCellVoltage, operation=PokeBPCR_U_OCVAveCellVoltage.PokeBPCR_U_OCVAveCellVoltage
        Event_PokeBPCR_U_OCVMaxCellVoltage: start-on-event=PokeBPCR_U_OCVMaxCellVoltage, operation=PokeBPCR_U_OCVMaxCellVoltage.PokeBPCR_U_OCVMaxCellVoltage
        Event_PokeBPCR_U_OCVMinCellVoltage: start-on-event=PokeBPCR_U_OCVMinCellVoltage, operation=PokeBPCR_U_OCVMinCellVoltage.PokeBPCR_U_OCVMinCellVoltage
        Event_PokeBPCR_U_OCVPckVoltage: start-on-event=PokeBPCR_U_OCVPckVoltage, operation=PokeBPCR_U_OCVPckVoltage.PokeBPCR_U_OCVPckVoltage
        Event_PokeBPCR_Z_MaxCellChargeImpedance: start-on-event=PokeBPCR_Z_MaxCellChargeImpedance, operation=PokeBPCR_Z_MaxCellChargeImpedance.PokeBPCR_Z_MaxCellChargeImpedance
        Event_PokeBPCR_Z_MaxCellDischargeImpedance: start-on-event=PokeBPCR_Z_MaxCellDischargeImpedance, operation=PokeBPCR_Z_MaxCellDischargeImpedance.PokeBPCR_Z_MaxCellDischargeImpedance
        Event_PokeBPCR_Z_MinCellChargeImpedance: start-on-event=PokeBPCR_Z_MinCellChargeImpedance, operation=PokeBPCR_Z_MinCellChargeImpedance.PokeBPCR_Z_MinCellChargeImpedance
        Event_PokeBPCR_Z_MinCellDischargeImpedance: start-on-event=PokeBPCR_Z_MinCellDischargeImpedance, operation=PokeBPCR_Z_MinCellDischargeImpedance.PokeBPCR_Z_MinCellDischargeImpedance
        Event_PokeBPCR_b_BalMd: start-on-event=PokeBPCR_b_BalMd, operation=PokeBPCR_b_BalMd.PokeBPCR_b_BalMd
        Event_PokeBPCR_b_CellVoltImbalance: start-on-event=PokeBPCR_b_CellVoltImbalance, operation=PokeBPCR_b_CellVoltImbalance.PokeBPCR_b_CellVoltImbalance
        Event_PokeBPCR_b_ChrgFail_On_BPCM: start-on-event=PokeBPCR_b_ChrgFail_On_BPCM, operation=PokeBPCR_b_ChrgFail_On_BPCM.PokeBPCR_b_ChrgFail_On_BPCM
        Event_PokeBPCR_b_DC_Isolation_Sts: start-on-event=PokeBPCR_b_DC_Isolation_Sts, operation=PokeBPCR_b_DC_Isolation_Sts.PokeBPCR_b_DC_Isolation_Sts
        Event_PokeBPCR_b_EVSer_On_BPCM: start-on-event=PokeBPCR_b_EVSer_On_BPCM, operation=PokeBPCR_b_EVSer_On_BPCM.PokeBPCR_b_EVSer_On_BPCM
        Event_PokeBPCR_b_HBCNC_LV_LO: start-on-event=PokeBPCR_b_HBCNC_LV_LO, operation=PokeBPCR_b_HBCNC_LV_LO.PokeBPCR_b_HBCNC_LV_LO
        Event_PokeBPCR_b_HEVOnRqBPCM: start-on-event=PokeBPCR_b_HEVOnRqBPCM, operation=PokeBPCR_b_HEVOnRqBPCM.PokeBPCR_b_HEVOnRqBPCM
        Event_PokeBPCR_b_HVBatPerWU12VChrg: start-on-event=PokeBPCR_b_HVBatPerWU12VChrg, operation=PokeBPCR_b_HVBatPerWU12VChrg.PokeBPCR_b_HVBatPerWU12VChrg
        Event_PokeBPCR_b_HVBatPerWUBal: start-on-event=PokeBPCR_b_HVBatPerWUBal, operation=PokeBPCR_b_HVBatPerWUBal.PokeBPCR_b_HVBatPerWUBal
        Event_PokeBPCR_b_HVBatPerWUCharge: start-on-event=PokeBPCR_b_HVBatPerWUCharge, operation=PokeBPCR_b_HVBatPerWUCharge.PokeBPCR_b_HVBatPerWUCharge
        Event_PokeBPCR_b_HVBatPerWUThermal: start-on-event=PokeBPCR_b_HVBatPerWUThermal, operation=PokeBPCR_b_HVBatPerWUThermal.PokeBPCR_b_HVBatPerWUThermal
        Event_PokeBPCR_b_HVBatRdy: start-on-event=PokeBPCR_b_HVBatRdy, operation=PokeBPCR_b_HVBatRdy.PokeBPCR_b_HVBatRdy
        Event_PokeBPCR_b_HVBatRdyForChrg: start-on-event=PokeBPCR_b_HVBatRdyForChrg, operation=PokeBPCR_b_HVBatRdyForChrg.PokeBPCR_b_HVBatRdyForChrg
        Event_PokeBPCR_b_HVBat_DC_CntctrOpn: start-on-event=PokeBPCR_b_HVBat_DC_CntctrOpn, operation=PokeBPCR_b_HVBat_DC_CntctrOpn.PokeBPCR_b_HVBat_DC_CntctrOpn
        Event_PokeBPCR_b_HVBat_DC_CntctrReq: start-on-event=PokeBPCR_b_HVBat_DC_CntctrReq, operation=PokeBPCR_b_HVBat_DC_CntctrReq.PokeBPCR_b_HVBat_DC_CntctrReq
        Event_PokeBPCR_b_HVBat_Real_Time_Clock_V: start-on-event=PokeBPCR_b_HVBat_Real_Time_Clock_V, operation=PokeBPCR_b_HVBat_Real_Time_Clock_V.PokeBPCR_b_HVBat_Real_Time_Clock_V
        Event_PokeBPCR_b_HVBattPerWakeUp: start-on-event=PokeBPCR_b_HVBattPerWakeUp, operation=PokeBPCR_b_HVBattPerWakeUp.PokeBPCR_b_HVBattPerWakeUp
        Event_PokeBPCR_b_HV_AuxLoadOffReq: start-on-event=PokeBPCR_b_HV_AuxLoadOffReq, operation=PokeBPCR_b_HV_AuxLoadOffReq.PokeBPCR_b_HV_AuxLoadOffReq
        Event_PokeBPCR_b_HV_BatCntctrOpenPending: start-on-event=PokeBPCR_b_HV_BatCntctrOpenPending, operation=PokeBPCR_b_HV_BatCntctrOpenPending.PokeBPCR_b_HV_BatCntctrOpenPending
        Event_PokeBPCR_b_HV_BatCntctrOpenReq: start-on-event=PokeBPCR_b_HV_BatCntctrOpenReq, operation=PokeBPCR_b_HV_BatCntctrOpenReq.PokeBPCR_b_HV_BatCntctrOpenReq
        Event_PokeBPCR_b_HV_BatDriveRdy: start-on-event=PokeBPCR_b_HV_BatDriveRdy, operation=PokeBPCR_b_HV_BatDriveRdy.PokeBPCR_b_HV_BatDriveRdy
        Event_PokeBPCR_b_MIL_OnRq_BPCM: start-on-event=PokeBPCR_b_MIL_OnRq_BPCM, operation=PokeBPCR_b_MIL_OnRq_BPCM.PokeBPCR_b_MIL_OnRq_BPCM
        Event_PokeBPCR_b_PwrLimON: start-on-event=PokeBPCR_b_PwrLimON, operation=PokeBPCR_b_PwrLimON.PokeBPCR_b_PwrLimON
        Event_PokeBPCR_b_StkOpnChkCmpl: start-on-event=PokeBPCR_b_StkOpnChkCmpl, operation=PokeBPCR_b_StkOpnChkCmpl.PokeBPCR_b_StkOpnChkCmpl
        Event_PokeBPCR_cnt_BatteryModel: start-on-event=PokeBPCR_cnt_BatteryModel, operation=PokeBPCR_cnt_BatteryModel.PokeBPCR_cnt_BatteryModel
        Event_PokeBPCR_cnt_HVBatt_ModNumMaxTmp: start-on-event=PokeBPCR_cnt_HVBatt_ModNumMaxTmp, operation=PokeBPCR_cnt_HVBatt_ModNumMaxTmp.PokeBPCR_cnt_HVBatt_ModNumMaxTmp
        Event_PokeBPCR_cnt_HVBatt_ModNumMinTmp: start-on-event=PokeBPCR_cnt_HVBatt_ModNumMinTmp, operation=PokeBPCR_cnt_HVBatt_ModNumMinTmp.PokeBPCR_cnt_HVBatt_ModNumMinTmp
        Event_PokeBPCR_e_BPCMShtDwnRdy: start-on-event=PokeBPCR_e_BPCMShtDwnRdy, operation=PokeBPCR_e_BPCMShtDwnRdy.PokeBPCR_e_BPCMShtDwnRdy
        Event_PokeBPCR_e_BPCM_Comm_Fail: start-on-event=PokeBPCR_e_BPCM_Comm_Fail, operation=PokeBPCR_e_BPCM_Comm_Fail.PokeBPCR_e_BPCM_Comm_Fail
        Event_PokeBPCR_e_BPCM_LIN_BusOff: start-on-event=PokeBPCR_e_BPCM_LIN_BusOff, operation=PokeBPCR_e_BPCM_LIN_BusOff.PokeBPCR_e_BPCM_LIN_BusOff
        Event_PokeBPCR_e_BPCM_LOC_BCP: start-on-event=PokeBPCR_e_BPCM_LOC_BCP, operation=PokeBPCR_e_BPCM_LOC_BCP.PokeBPCR_e_BPCM_LOC_BCP
        Event_PokeBPCR_e_BPCM_LOC_BatClntHtr: start-on-event=PokeBPCR_e_BPCM_LOC_BatClntHtr, operation=PokeBPCR_e_BPCM_LOC_BatClntHtr.PokeBPCR_e_BPCM_LOC_BatClntHtr
        Event_PokeBPCR_e_ChargingStat_BPCM: start-on-event=PokeBPCR_e_ChargingStat_BPCM, operation=PokeBPCR_e_ChargingStat_BPCM.PokeBPCR_e_ChargingStat_BPCM
        Event_PokeBPCR_e_DCIsolSts: start-on-event=PokeBPCR_e_DCIsolSts, operation=PokeBPCR_e_DCIsolSts.PokeBPCR_e_DCIsolSts
        Event_PokeBPCR_e_HVBatCntrWeld_ImpdOpn: start-on-event=PokeBPCR_e_HVBatCntrWeld_ImpdOpn, operation=PokeBPCR_e_HVBatCntrWeld_ImpdOpn.PokeBPCR_e_HVBatCntrWeld_ImpdOpn
        Event_PokeBPCR_e_HVBatIntrlkIntrnlStat: start-on-event=PokeBPCR_e_HVBatIntrlkIntrnlStat, operation=PokeBPCR_e_HVBatIntrlkIntrnlStat.PokeBPCR_e_HVBatIntrlkIntrnlStat
        Event_PokeBPCR_e_HVBatPerWU_Rsn: start-on-event=PokeBPCR_e_HVBatPerWU_Rsn, operation=PokeBPCR_e_HVBatPerWU_Rsn.PokeBPCR_e_HVBatPerWU_Rsn
        Event_PokeBPCR_e_HVBat_DC_CntctrStat: start-on-event=PokeBPCR_e_HVBat_DC_CntctrStat, operation=PokeBPCR_e_HVBat_DC_CntctrStat.PokeBPCR_e_HVBat_DC_CntctrStat
        Event_PokeBPCR_e_HV_BatCntctrStat: start-on-event=PokeBPCR_e_HV_BatCntctrStat, operation=PokeBPCR_e_HV_BatCntctrStat.PokeBPCR_e_HV_BatCntctrStat
        Event_PokeBPCR_e_HV_BatInrlkStat: start-on-event=PokeBPCR_e_HV_BatInrlkStat, operation=PokeBPCR_e_HV_BatInrlkStat.PokeBPCR_e_HV_BatInrlkStat
        Event_PokeBPCR_e_HV_BatIsolStat: start-on-event=PokeBPCR_e_HV_BatIsolStat, operation=PokeBPCR_e_HV_BatIsolStat.PokeBPCR_e_HV_BatIsolStat
        Event_PokeBPCR_e_HV_DcChargeTypeStat: start-on-event=PokeBPCR_e_HV_DcChargeTypeStat, operation=PokeBPCR_e_HV_DcChargeTypeStat.PokeBPCR_e_HV_DcChargeTypeStat
        Event_PokeBPCR_e_HV_TracBatCntctrConfig: start-on-event=PokeBPCR_e_HV_TracBatCntctrConfig, operation=PokeBPCR_e_HV_TracBatCntctrConfig.PokeBPCR_e_HV_TracBatCntctrConfig
        Event_PokeBPCR_e_PowerModeState: start-on-event=PokeBPCR_e_PowerModeState, operation=PokeBPCR_e_PowerModeState.PokeBPCR_e_PowerModeState
        Event_PokeBPCR_e_PwrtrnHV_IsolStat: start-on-event=PokeBPCR_e_PwrtrnHV_IsolStat, operation=PokeBPCR_e_PwrtrnHV_IsolStat.PokeBPCR_e_PwrtrnHV_IsolStat
        Event_PokeBPCR_e_ThrmlRnawy_Warn: start-on-event=PokeBPCR_e_ThrmlRnawy_Warn, operation=PokeBPCR_e_ThrmlRnawy_Warn.PokeBPCR_e_ThrmlRnawy_Warn
        Event_PokeBPCR_i_DC_Isolation_Sts_M182: start-on-event=PokeBPCR_i_DC_Isolation_Sts_M182, operation=PokeBPCR_i_DC_Isolation_Sts_M182.PokeBPCR_i_DC_Isolation_Sts_M182
        Event_PokeBPCR_q_FullAmpHrCap: start-on-event=PokeBPCR_q_FullAmpHrCap, operation=PokeBPCR_q_FullAmpHrCap.PokeBPCR_q_FullAmpHrCap
        Event_PokeBPCR_q_RemainingAmpHrCap: start-on-event=PokeBPCR_q_RemainingAmpHrCap, operation=PokeBPCR_q_RemainingAmpHrCap.PokeBPCR_q_RemainingAmpHrCap
        Event_PokeBPCR_t_BSW_PWMCntctrTmr: start-on-event=PokeBPCR_t_BSW_PWMCntctrTmr, operation=PokeBPCR_t_BSW_PWMCntctrTmr.PokeBPCR_t_BSW_PWMCntctrTmr
        Event_PokeBPCR_t_HVBatRealTimeClock: start-on-event=PokeBPCR_t_HVBatRealTimeClock, operation=PokeBPCR_t_HVBatRealTimeClock.PokeBPCR_t_HVBatRealTimeClock
        Event_PokeBPCR_t_HVBatSleepTime: start-on-event=PokeBPCR_t_HVBatSleepTime, operation=PokeBPCR_t_HVBatSleepTime.PokeBPCR_t_HVBatSleepTime
        Event_PokeBPCR_t_HVBattCntctrOpnTm: start-on-event=PokeBPCR_t_HVBattCntctrOpnTm, operation=PokeBPCR_t_HVBattCntctrOpnTm.PokeBPCR_t_HVBattCntctrOpnTm
        Event_PokeBPCR_t_PrechrgPnltyTimer: start-on-event=PokeBPCR_t_PrechrgPnltyTimer, operation=PokeBPCR_t_PrechrgPnltyTimer.PokeBPCR_t_PrechrgPnltyTimer
        Event_TmotBPCR_b_HVBatCntrWeld_ImpdOpn: start-on-event=TmotBPCR_b_HVBatCntrWeld_ImpdOpn, operation=TmotBPCR_b_HVBatCntrWeld_ImpdOpn.TmotBPCR_b_HVBatCntrWeld_ImpdOpn
        Event_TmotBPCR_b_HVBatRdy: start-on-event=TmotBPCR_b_HVBatRdy, operation=TmotBPCR_b_HVBatRdy.TmotBPCR_b_HVBatRdy
        Event_TmotBPCR_b_HV_BatChrgPwrET: start-on-event=TmotBPCR_b_HV_BatChrgPwrET, operation=TmotBPCR_b_HV_BatChrgPwrET.TmotBPCR_b_HV_BatChrgPwrET
        Event_TmotBPCR_b_HV_BatChrgPwrLT: start-on-event=TmotBPCR_b_HV_BatChrgPwrLT, operation=TmotBPCR_b_HV_BatChrgPwrLT.TmotBPCR_b_HV_BatChrgPwrLT
        Event_TmotBPCR_b_HV_BatChrgPwrST: start-on-event=TmotBPCR_b_HV_BatChrgPwrST, operation=TmotBPCR_b_HV_BatChrgPwrST.TmotBPCR_b_HV_BatChrgPwrST
        Event_TmotBPCR_b_HV_BatDschrgPwrET: start-on-event=TmotBPCR_b_HV_BatDschrgPwrET, operation=TmotBPCR_b_HV_BatDschrgPwrET.TmotBPCR_b_HV_BatDschrgPwrET
        Event_TmotBPCR_b_HV_BatDschrgPwrLT: start-on-event=TmotBPCR_b_HV_BatDschrgPwrLT, operation=TmotBPCR_b_HV_BatDschrgPwrLT.TmotBPCR_b_HV_BatDschrgPwrLT
        Event_TmotBPCR_b_HV_BatDschrgPwrST: start-on-event=TmotBPCR_b_HV_BatDschrgPwrST, operation=TmotBPCR_b_HV_BatDschrgPwrST.TmotBPCR_b_HV_BatDschrgPwrST
        Event_TmotBPCR_b_HV_BatModTempAvg: start-on-event=TmotBPCR_b_HV_BatModTempAvg, operation=TmotBPCR_b_HV_BatModTempAvg.TmotBPCR_b_HV_BatModTempAvg
        Event_TmotBPCR_b_HV_BatModTempMax: start-on-event=TmotBPCR_b_HV_BatModTempMax, operation=TmotBPCR_b_HV_BatModTempMax.TmotBPCR_b_HV_BatModTempMax
        Event_TmotBPCR_b_HV_BatModTempMin: start-on-event=TmotBPCR_b_HV_BatModTempMin, operation=TmotBPCR_b_HV_BatModTempMin.TmotBPCR_b_HV_BatModTempMin
        Event_TmotBPCR_b_HV_BatPackSOC: start-on-event=TmotBPCR_b_HV_BatPackSOC, operation=TmotBPCR_b_HV_BatPackSOC.TmotBPCR_b_HV_BatPackSOC
        Event_TmotBPCR_e_BPCM_LIN_BusOff: start-on-event=TmotBPCR_e_BPCM_LIN_BusOff, operation=TmotBPCR_e_BPCM_LIN_BusOff.TmotBPCR_e_BPCM_LIN_BusOff
        Event_TmotBPCR_e_BPCM_LOC_BCP: start-on-event=TmotBPCR_e_BPCM_LOC_BCP, operation=TmotBPCR_e_BPCM_LOC_BCP.TmotBPCR_e_BPCM_LOC_BCP
        Event_TmotBPCR_e_BPCM_LOC_BatClntHtr: start-on-event=TmotBPCR_e_BPCM_LOC_BatClntHtr, operation=TmotBPCR_e_BPCM_LOC_BatClntHtr.TmotBPCR_e_BPCM_LOC_BatClntHtr
      init event Event_BPCR_ac_Init: start-on-event=BPCR_ac_Init
      init event Event_PwrOn: start-on-event=BPCR_PwrOn
      init event Event_PwrOff: start-on-event=BPCR_PwrOff
      explicit-inter-runnable-variables:
        67 x data, all with category=VALUE, sw-calibration-access=READ-ONLY:
          CntctrCntrl_PWM_write_IRV: type=Float, init-value=0
          BSW_PWMCntctrTmr_write_IRV: type=UInt32, init-value=0
          BSW_PWMTmrRcvd_write_IRV: type=UInt8, init-value=0
          HEVOnRqBPCM_write_IRV: type=Boolean, init-value=0
          VeBPCR_b_HV_BatModTempAvgSgnl_Rcvd_write_IRV: type=Boolean, init-value=0
          VeBPCR_b_HV_BatModTempMinSgnl_Rcvd_write_IRV: type=Boolean, init-value=0
          VeBPCR_b_HV_BatModTempMaxSgnl_Rcvd_write_IRV: type=Boolean, init-value=0
          HV_BatModTempAvg_write_IRV: type=Float, init-value=0
          HV_BatModTempAvgFA_write_IRV: type=Boolean, init-value=0
          HV_BatModTempMin_write_IRV: type=Float, init-value=0
          HV_BatModTempMinFA_write_IRV: type=Boolean, init-value=0
          HV_BatModTempMax_write_IRV: type=Float, init-value=0
          HV_BatModTempMaxFA_write_IRV: type=Boolean, init-value=0
          HV_BatRdySgnl_Rcvd_write_IRV: type=Boolean, init-value=0
          HVBatRdy_Init_write_IRV: type=Boolean, init-value=0
          HVBatCntrWeld_ImpdOpn_write_IRV: type=TeBPCR_e_HVBatCntrWeld_ImpdOpn, init-value=CeBPCR_e_Normal
          VeBPCR_b_HVBatCntrWeld_ImpdOpnSgnl_Rcvd_write_IRV: type=Boolean, init-value=0
          MILOnRqBPCM_Init_write_IRV: type=Boolean, init-value=0
          VeBPCI_U_BatVoltModMaxArb_Init_write_IRV: type=Float, init-value=0
          VeBPCI_U_BatVoltModMinArb_Init_write_IRV: type=Float, init-value=0
          HV_BatModVoltMax_write_IRV: type=Float, init-value=0
          CellVoltHighThrsh_write_IRV: type=Float, init-value=0
          HV_BatModVoltMaxFA_write_IRV: type=Boolean, init-value=0
          HV_BatModVoltMin_write_IRV: type=Float, init-value=0
          CellVoltLowThrsh_write_IRV: type=Float, init-value=0
          HV_BatModVoltMinFA_write_IRV: type=Boolean, init-value=0
          HV_BatCntctrOpenPending_write_IRV: type=Boolean, init-value=0
          HV_BatCntctrStat_write_IRV: type=TeHVTR_e_HV_BatCntctrStat, init-value=CeHVTR_e_Open
          HV_BatCntctrStatFA_write_IRV: type=Boolean, init-value=0
          HV_BatCntctrOpenReq_write_IRV: type=Boolean, init-value=0
          VeBPCR_e_PWMDecodedCntctrSts_write_IRV: type=TeBPCR_e_PWMDecoded_CntctrSts, init-value=CeBPCR_e_CloseCntctrCmd
          HVBat_ThrmlRnawy_WarnFA_Init_write_IRV: type=Boolean, init-value=0
          HVBat_ThrmlRnawy_Warn_Init_write_IRV: type=TeBPCR_e_ThrmlRnawy_WarnSts, init-value=CeBPCR_e_DefaultThrmlRnawy
          VeBPCR_b_PWMTimerOOR_write_IRV: type=Boolean, init-value=0
          VeBPCR_b_PWMBlankAct_write_IRV: type=Boolean, init-value=0
          PwrLimON_IRV: type=Boolean, init-value=0
          VeBPCR_T_HV_BatModTempMax_write_IRV: type=Float, init-value=0
          VeBPCR_T_HV_BatModTempMin_write_IRV: type=Float, init-value=0
          HVBatDschrgPowLT_Init_write_IRV: type=Float, init-value=0
          HVBatDschrgPowLT_FA_Init_write_IRV: type=Boolean, init-value=0
          VeBPCR_b_HV_BatDschrgPwrLTSgnl_Rcvd_write_IRV: type=Boolean, init-value=0
          HVBatChrgPowLT_Init_write_IRV: type=Float, init-value=0
          HVBatChrgPowLT_FA_Init_write_IRV: type=Boolean, init-value=0
          VeBPCR_b_HV_BatChrgPwrLTSgnl_Rcvd_write_IRV: type=Boolean, init-value=0
          HVBatDschrgPowET_Init_write_IRV: type=Float, init-value=0
          HVBatDschrgPowET_FA_Init_write_IRV: type=Boolean, init-value=0
          VeBPCR_b_HV_BatDschrgPwrETSgnl_Rcvd_write_IRV: type=Boolean, init-value=0
          HVBatChrgPowET_Init_write_IRV: type=Float, init-value=0
          HVBatChrgPowET_FA_Init_write_IRV: type=Boolean, init-value=0
          VeBPCR_b_HV_BatChrgPwrETSgnl_Rcvd_write_IRV: type=Boolean, init-value=0
          HVBatDschrgPowST_Init_write_IRV: type=Float, init-value=0
          HVBatDschrgPowST_FA_Init_write_IRV: type=Boolean, init-value=0
          VeBPCR_b_HV_BatDschrgPwrSTSgnl_Rcvd_write_IRV: type=Boolean, init-value=0
          HVBatChrgPowST_Init_write_IRV: type=Float, init-value=0
          HVBatChrgPowST_FA_Init_write_IRV: type=Boolean, init-value=0
          VeBPCR_b_HV_BatChrgPwrSTSgnl_Rcvd_write_IRV: type=Boolean, init-value=0
          HV_BatCurrFA_write_IRV: type=Boolean, init-value=0
          HVBatPackSOC_Init_write_IRV: type=Float, init-value=0
          HVBatPackSOC_FA_Init_write_IRV: type=Boolean, init-value=0
          VeBPCR_b_HV_BatPackSOCSgnl_Rcvd_write_IRV: type=Boolean, init-value=0
          CellVoltHighThrshFAInit_write_IRV: type=Boolean, init-value=0
          CellVoltLowThrshFAInit_write_IRV: type=Boolean, init-value=0
          TracBat_EChrgPowLong_write_IRV: type=Float, init-value=0
          TracBat_EChrgPowLongV_write_IRV: type=Boolean, init-value=0
          VeBPCR_T_BatModTmp_write_IRV: type=Float, init-value=0
          VeBPCI_U_BatVoltModMinArb_write_IRV: type=Float, init-value=0
          VeBPCI_U_BatVoltModMaxArb_write_IRV: type=Float, init-value=0
      179 x runnable:
        BPCR_ac_Init
          data-send-points:
            174 x access:
              OUT_VeBPCR_I_HV_BatCurr_Value: accessed-variable=VeBPCR_I_HV_BatCurr.Value
              OUT_VeBPCR_b_HV_BatCurrFA_Value: accessed-variable=VeBPCR_b_HV_BatCurrFA.Value
              OUT_VeBPCR_U_HV_BatVolt_Value: accessed-variable=VeBPCR_U_HV_BatVolt.Value
              OUT_VeBPCR_b_HV_BatVoltFA_Value: accessed-variable=VeBPCR_b_HV_BatVoltFA.Value
              OUT_VeBPCR_U_HV_BatModVoltMax_Value: accessed-variable=VeBPCR_U_HV_BatModVoltMax.Value
              OUT_VeBPCR_b_HV_BatModVoltMaxFA_Value: accessed-variable=VeBPCR_b_HV_BatModVoltMaxFA.Value
              OUT_VeBPCR_U_HV_BatModVoltMin_Value: accessed-variable=VeBPCR_U_HV_BatModVoltMin.Value
              OUT_VeBPCR_b_HV_BatModVoltMinFA_Value: accessed-variable=VeBPCR_b_HV_BatModVoltMinFA.Value
              OUT_VeBPCR_U_HV_BatModVoltAvg_Value: accessed-variable=VeBPCR_U_HV_BatModVoltAvg.Value
              OUT_VeBPCR_b_HV_BatModVoltAvgFA_Value: accessed-variable=VeBPCR_b_HV_BatModVoltAvgFA.Value
              OUT_VeBPCR_T_HV_BatModTempMax_Value: accessed-variable=VeBPCR_T_HV_BatModTempMax.Value
              OUT_VeBPCR_b_HV_BatModTempMaxFA_Value: accessed-variable=VeBPCR_b_HV_BatModTempMaxFA.Value
              OUT_VeBPCR_T_HV_BatModTempMin_Value: accessed-variable=VeBPCR_T_HV_BatModTempMin.Value
              OUT_VeBPCR_b_HV_BatModTempMinFA_Value: accessed-variable=VeBPCR_b_HV_BatModTempMinFA.Value
              OUT_VeBPCR_T_HV_BatModTempAvg_Value: accessed-variable=VeBPCR_T_HV_BatModTempAvg.Value
              OUT_VeBPCR_b_HV_BatModTempAvgFA_Value: accessed-variable=VeBPCR_b_HV_BatModTempAvgFA.Value
              OUT_VeBPCR_e_HV_BatCntctrStat_Value: accessed-variable=VeBPCR_e_HV_BatCntctrStat.Value
              OUT_VeBPCR_b_HV_BatCntctrStatFA_Value: accessed-variable=VeBPCR_b_HV_BatCntctrStatFA.Value
              OUT_VeBPCR_e_HV_BatInrlkStat_Value: accessed-variable=VeBPCR_e_HV_BatInrlkStat.Value
              OUT_VeBPCR_b_HV_BatCntctrOpenReq_Value: accessed-variable=VeBPCR_b_HV_BatCntctrOpenReq.Value
              OUT_VeBPCR_b_HV_BatCntctrOpenPending_Value: accessed-variable=VeBPCR_b_HV_BatCntctrOpenPending.Value
              OUT_VeBPCR_b_HV_BatInrlkStatFA_Value: accessed-variable=VeBPCR_b_HV_BatInrlkStatFA.Value
              OUT_VeBPCR_U_CellVoltLowThrsh_Value: accessed-variable=VeBPCR_U_CellVoltLowThrsh.Value
              OUT_VeBPCR_b_CellVoltLowThrshFA_Value: accessed-variable=VeBPCR_b_CellVoltLowThrshFA.Value
              OUT_VeBPCR_U_CellVoltHighThrsh_Value: accessed-variable=VeBPCR_U_CellVoltHighThrsh.Value
              OUT_VeBPCR_b_CellVoltHighThrshFA_Value: accessed-variable=VeBPCR_b_CellVoltHighThrshFA.Value
              OUT_VeBPCR_Cnt_HVBat_NumMaxVlt_Value: accessed-variable=VeBPCR_Cnt_HVBat_NumMaxVlt.Value
              OUT_VeBPCR_Cnt_HVBat_NumMinVlt_Value: accessed-variable=VeBPCR_Cnt_HVBat_NumMinVlt.Value
              OUT_VeBPCR_Cnt_HVBat_ModNumMinTmp_Value: accessed-variable=VeBPCR_Cnt_HVBat_ModNumMinTmp.Value
              OUT_VeBPCR_Cnt_HVBat_ModNumMaxTmp_Value: accessed-variable=VeBPCR_Cnt_HVBat_ModNumMaxTmp.Value
              OUT_VeBPCR_U_OCVMinCellVoltage_Value: accessed-variable=VeBPCR_U_OCVMinCellVoltage.Value
              OUT_VeBPCR_b_OCVMinCellVoltage_FA_Value: accessed-variable=VeBPCR_b_OCVMinCellVoltage_FA.Value
              OUT_VeBPCR_U_OCVMaxCellVoltage_Value: accessed-variable=VeBPCR_U_OCVMaxCellVoltage.Value
              OUT_VeBPCR_b_OCVMaxCellVoltage_FA_Value: accessed-variable=VeBPCR_b_OCVMaxCellVoltage_FA.Value
              OUT_VeBPCR_U_OCVAvgCellVoltage_Value: accessed-variable=VeBPCR_U_OCVAvgCellVoltage.Value
              OUT_VeBPCR_b_OCVAvgCellVoltage_FA_Value: accessed-variable=VeBPCR_b_OCVAvgCellVoltage_FA.Value
              OUT_VeBPCR_Z_MaxCellDschargeImpedance_Value: accessed-variable=VeBPCR_Z_MaxCellDschargeImpedance.Value
              OUT_VeBPCR_b_MaxCellDschargeImpedance_FA_Value: accessed-variable=VeBPCR_b_MaxCellDschargeImpedance_FA.Value
              OUT_VeBPCR_Z_MinCellDschargeImpedance_Value: accessed-variable=VeBPCR_Z_MinCellDschargeImpedance.Value
              OUT_VeBPCR_b_MinCellDschargeImpedance_FA_Value: accessed-variable=VeBPCR_b_MinCellDschargeImpedance_FA.Value
              OUT_VeBPCR_t_HVBattCntctrOpnTm_Value: accessed-variable=VeBPCR_t_HVBattCntctrOpnTm.Value
              OUT_VeBPCR_t_PrechrgPnltyTimer_Value: accessed-variable=VeBPCR_t_PrechrgPnltyTimer.Value
              OUT_VeBPCR_b_HVBatPerWUThermal_Value: accessed-variable=VeBPCR_b_HVBatPerWUThermal.Value
              OUT_VeBPCR_b_HVBatPerWakeUp_Value: accessed-variable=VeBPCR_b_HVBatPerWakeUp.Value
              OUT_VeBPCR_t_HVBatSleepTime_Value: accessed-variable=VeBPCR_t_HVBatSleepTime.Value
              OUT_VeBPCR_e_BPCMShtDwnRdy_Value: accessed-variable=VeBPCR_e_BPCMShtDwnRdy.Value
              OUT_VeBPCR_e_PwrtrnHV_IsolStat_Value: accessed-variable=VeBPCR_e_PwrtrnHV_IsolStat.Value
              OUT_VeBPCR_Pct_HVBatSOH_Value: accessed-variable=VeBPCR_Pct_HVBatSOH.Value
              OUT_VeBPCR_U_MaxCellVltAlld_Value: accessed-variable=VeBPCR_U_MaxCellVltAlld.Value
              OUT_VeBPCR_b_MaxCellVltAlld_FA_Value: accessed-variable=VeBPCR_b_MaxCellVltAlld_FA.Value
              OUT_VeBPCR_U_MinCellVltAlld_Value: accessed-variable=VeBPCR_U_MinCellVltAlld.Value
              OUT_VeBPCR_b_MinCellVltAlld_FA_Value: accessed-variable=VeBPCR_b_MinCellVltAlld_FA.Value
              OUT_VeBPCR_U_MaxPkVltAlld_Value: accessed-variable=VeBPCR_U_MaxPkVltAlld.Value
              OUT_VeBPCR_b_MaxPkVltAlld_FA_Value: accessed-variable=VeBPCR_b_MaxPkVltAlld_FA.Value
              OUT_VeBPCR_U_MinPkVltAlld_Value: accessed-variable=VeBPCR_U_MinPkVltAlld.Value
              OUT_VeBPCR_b_MinPkVltAlld_FA_Value: accessed-variable=VeBPCR_b_MinPkVltAlld_FA.Value
              OUT_VeBPCR_b_HVBatRdy_Value: accessed-variable=VeBPCR_b_HVBatRdy.Value
              OUT_VeBPCR_Pct_HVBatSOHLow_Value: accessed-variable=VeBPCR_Pct_HVBatSOHLow.Value
              OUT_VeBPCR_t_HVBatRealTimeClock_Value: accessed-variable=VeBPCR_t_HVBatRealTimeClock.Value
              OUT_VeBPCR_e_HVBatIntrlkIntrnlStat_Value: accessed-variable=VeBPCR_e_HVBatIntrlkIntrnlStat.Value
              OUT_VeBPCR_b_HVBatIntrlkIntrnlStatFA_Value: accessed-variable=VeBPCR_b_HVBatIntrlkIntrnlStatFA.Value
              OUT_VeBPCR_b_HEVOnRqBPCM_Value: accessed-variable=VeBPCR_b_HEVOnRqBPCM.Value
              OUT_VeBPCR_b_HEVOnRqBPCM_Debounced_Value: accessed-variable=VeBPCR_b_HEVOnRqBPCM_Debounced.Value
              OUT_VeBPCR_b_BPCM_OVActv_Value: accessed-variable=VeBPCR_b_BPCM_OVActv.Value
              OUT_VeBPCR_b_BPCM_UVActv_Value: accessed-variable=VeBPCR_b_BPCM_UVActv.Value
              OUT_VeBPCR_e_HVBatRdy_Value: accessed-variable=VeBPCR_e_HVBatRdy.Value
              OUT_VeBPCR_b_HVBatRealTimeClock_FA_Value: accessed-variable=VeBPCR_b_HVBatRealTimeClock_FA.Value
              OUT_VeBPCR_e_PWMDecodedCntctrSts_Value: accessed-variable=VeBPCR_e_PWMDecodedCntctrSts.Value
              OUT_VeBPCR_P_TracBat_EChrgPowLong_Value: accessed-variable=VeBPCR_P_TracBat_EChrgPowLong.Value
              OUT_VeBPCR_b_TracBat_EChrgPowLongFA_Value: accessed-variable=VeBPCR_b_TracBat_EChrgPowLongFA.Value
              OUT_VeBPCR_b_PWMTimerOOR_Value: accessed-variable=VeBPCR_b_PWMTimerOOR.Value
              OUT_VeBPCR_b_CntctrCntrl_PWM_FA_Value: accessed-variable=VeBPCR_b_CntctrCntrl_PWM_FA.Value
              OUT_VeBPCR_T_HVBatClgOutletTemp_Value: accessed-variable=VeBPCR_T_HVBatClgOutletTemp.Value
              OUT_VeBPCR_b_HVBatClgOutletTempFA_Value: accessed-variable=VeBPCR_b_HVBatClgOutletTempFA.Value
              OUT_VeBPCR_e_BPCM_LIN_BusOff_Value: accessed-variable=VeBPCR_e_BPCM_LIN_BusOff.Value
              OUT_VeBPCR_b_BPCM_LIN_BusOff_FA_Value: accessed-variable=VeBPCR_b_BPCM_LIN_BusOff_FA.Value
              OUT_VeBPCR_b_BPCM_LIN_BusOff_SgnlRcvd_Value: accessed-variable=VeBPCR_b_BPCM_LIN_BusOff_SgnlRcvd.Value
              OUT_VeBPCR_e_BPCM_LOC_BCP_Value: accessed-variable=VeBPCR_e_BPCM_LOC_BCP.Value
              OUT_VeBPCR_b_BPCM_LOC_BCP_FA_Value: accessed-variable=VeBPCR_b_BPCM_LOC_BCP_FA.Value
              OUT_VeBPCR_b_BPCM_LOC_BCP_SgnlRcvd_Value: accessed-variable=VeBPCR_b_BPCM_LOC_BCP_SgnlRcvd.Value
              OUT_VeBPCR_e_BPCM_LOC_BatClntHtr_Value: accessed-variable=VeBPCR_e_BPCM_LOC_BatClntHtr.Value
              OUT_VeBPCR_b_BPCM_LOC_BatClntHtr_FA_Value: accessed-variable=VeBPCR_b_BPCM_LOC_BatClntHtr_FA.Value
              OUT_VeBPCR_b_BPCM_LOC_BatClntHtr_SgnlRcvd_Value: accessed-variable=VeBPCR_b_BPCM_LOC_BatClntHtr_SgnlRcvd.Value
              OUT_VeBPCR_I_MaxChrgCurrAlwd_Value: accessed-variable=VeBPCR_I_MaxChrgCurrAlwd.Value
              OUT_VeBPCR_e_ChargingStat_BPCM_Value: accessed-variable=VeBPCR_e_ChargingStat_BPCM.Value
              OUT_VeBPCR_P_HV_BatDschrgPwrET_Value: accessed-variable=VeBPCR_P_HV_BatDschrgPwrET.Value
              OUT_VeBPCR_b_HV_BatDschrgPwrET_FA_Value: accessed-variable=VeBPCR_b_HV_BatDschrgPwrET_FA.Value
              OUT_VeBPCR_b_HV_BatDschrgPwrETSgnl_Rcvd_Value: accessed-variable=VeBPCR_b_HV_BatDschrgPwrETSgnl_Rcvd.Value
              OUT_VeBPCR_P_HV_BatDschrgPwrLT_Value: accessed-variable=VeBPCR_P_HV_BatDschrgPwrLT.Value
              OUT_VeBPCR_b_HV_BatDschrgPwrLT_FA_Value: accessed-variable=VeBPCR_b_HV_BatDschrgPwrLT_FA.Value
              OUT_VeBPCR_b_HV_BatDschrgPwrLTSgnl_Rcvd_Value: accessed-variable=VeBPCR_b_HV_BatDschrgPwrLTSgnl_Rcvd.Value
              OUT_VeBPCR_P_HV_BatDschrgPwrST_Value: accessed-variable=VeBPCR_P_HV_BatDschrgPwrST.Value
              OUT_VeBPCR_b_HV_BatDschrgPwrST_FA_Value: accessed-variable=VeBPCR_b_HV_BatDschrgPwrST_FA.Value
              OUT_VeBPCR_b_HV_BatDschrgPwrSTSgnl_Rcvd_Value: accessed-variable=VeBPCR_b_HV_BatDschrgPwrSTSgnl_Rcvd.Value
              OUT_VeBPCR_P_HV_BatChrgPwrET_Value: accessed-variable=VeBPCR_P_HV_BatChrgPwrET.Value
              OUT_VeBPCR_b_HV_BatChrgPwrET_FA_Value: accessed-variable=VeBPCR_b_HV_BatChrgPwrET_FA.Value
              OUT_VeBPCR_b_HV_BatChrgPwrETSgnl_Rcvd_Value: accessed-variable=VeBPCR_b_HV_BatChrgPwrETSgnl_Rcvd.Value
              OUT_VeBPCR_P_HV_BatChrgPwrLT_Value: accessed-variable=VeBPCR_P_HV_BatChrgPwrLT.Value
              OUT_VeBPCR_b_HV_BatChrgPwrLT_FA_Value: accessed-variable=VeBPCR_b_HV_BatChrgPwrLT_FA.Value
              OUT_VeBPCR_b_HV_BatChrgPwrLTSgnl_Rcvd_Value: accessed-variable=VeBPCR_b_HV_BatChrgPwrLTSgnl_Rcvd.Value
              OUT_VeBPCR_P_HV_BatChrgPwrST_Value: accessed-variable=VeBPCR_P_HV_BatChrgPwrST.Value
              OUT_VeBPCR_b_HV_BatChrgPwrST_FA_Value: accessed-variable=VeBPCR_b_HV_BatChrgPwrST_FA.Value
              OUT_VeBPCR_b_HV_BatChrgPwrSTSgnl_Rcvd_Value: accessed-variable=VeBPCR_b_HV_BatChrgPwrSTSgnl_Rcvd.Value
              OUT_VeBPCR_Pct_HV_BatPackSOC_Value: accessed-variable=VeBPCR_Pct_HV_BatPackSOC.Value
              OUT_VeBPCR_b_HV_BatPackSOC_FA_Value: accessed-variable=VeBPCR_b_HV_BatPackSOC_FA.Value
              OUT_VeBPCR_b_HV_BatPackSOC_SgnlRcvd_Value: accessed-variable=VeBPCR_b_HV_BatPackSOC_SgnlRcvd.Value
              OUT_VeBPCR_q_FullAmpHrCap_Value: accessed-variable=VeBPCR_q_FullAmpHrCap.Value
              OUT_VeBPCR_b_HVBatPerWU12VChrg_Value: accessed-variable=VeBPCR_b_HVBatPerWU12VChrg.Value
              OUT_VeBPCR_b_HVBat_DC_CntctrOpn_Value: accessed-variable=VeBPCR_b_HVBat_DC_CntctrOpn.Value
              OUT_VeBPCR_b_HVBat_DC_CntctrReq_Value: accessed-variable=VeBPCR_b_HVBat_DC_CntctrReq.Value
              OUT_VeBPCR_b_DC_Isolation_Sts_Value: accessed-variable=VeBPCR_b_DC_Isolation_Sts.Value
              OUT_VeBPCR_e_HVBat_DC_CntctrStat_Value: accessed-variable=VeBPCR_e_HVBat_DC_CntctrStat.Value
              OUT_VeBPCR_b_HVBat_DC_CntctrStat_FA_Value: accessed-variable=VeBPCR_b_HVBat_DC_CntctrStat_FA.Value
              OUT_VeBPCR_b_ChargingStat_BPCMFA_Value: accessed-variable=VeBPCR_b_ChargingStat_BPCMFA.Value
              OUT_VeBPCR_b_MaxChgCurrAlwdFA_Value: accessed-variable=VeBPCR_b_MaxChgCurrAlwdFA.Value
              OUT_VeBPCR_q_RemainingAmpHrCap_Value: accessed-variable=VeBPCR_q_RemainingAmpHrCap.Value
              OUT_VeBPCR_b_RemainingAmpHrCapFA_Value: accessed-variable=VeBPCR_b_RemainingAmpHrCapFA.Value
              OUT_VeBPCR_T_BatModTmp_Value: accessed-variable=VeBPCR_T_BatModTmp.Value
              OUT_VeBPCR_T_HV_BatModTempMax_Arb_Value: accessed-variable=VeBPCR_T_HV_BatModTempMax_Arb.Value
              OUT_VeBPCR_T_HV_BatModTempMin_Arb_Value: accessed-variable=VeBPCR_T_HV_BatModTempMin_Arb.Value
              OUT_VeBPCR_b_HV_BatDschrgPwrLT_FA_Ovrd_Value: accessed-variable=VeBPCR_b_HV_BatDschrgPwrLT_FA_Ovrd.Value
              OUT_VeBPCR_P_HV_BatDschrgPwrLT_Arb_Value: accessed-variable=VeBPCR_P_HV_BatDschrgPwrLT_Arb.Value
              OUT_VeBPCR_b_HV_BatChrgPwrLT_FA_Ovrd_Value: accessed-variable=VeBPCR_b_HV_BatChrgPwrLT_FA_Ovrd.Value
              OUT_VeBPCR_P_HV_BatChrgPwrLT_Arb_Value: accessed-variable=VeBPCR_P_HV_BatChrgPwrLT_Arb.Value
              OUT_VeBPCR_b_HV_BatDschrgPwrET_FA_Ovrd_Value: accessed-variable=VeBPCR_b_HV_BatDschrgPwrET_FA_Ovrd.Value
              OUT_VeBPCR_P_HV_BatDschrgPwrET_Arb_Value: accessed-variable=VeBPCR_P_HV_BatDschrgPwrET_Arb.Value
              OUT_VeBPCR_b_HV_BatChrgPwrET_FA_Ovrd_Value: accessed-variable=VeBPCR_b_HV_BatChrgPwrET_FA_Ovrd.Value
              OUT_VeBPCR_P_HV_BatChrgPwrET_Arb_Value: accessed-variable=VeBPCR_P_HV_BatChrgPwrET_Arb.Value
              OUT_VeBPCR_b_HV_BatDschrgPwrST_FA_Ovrd_Value: accessed-variable=VeBPCR_b_HV_BatDschrgPwrST_FA_Ovrd.Value
              OUT_VeBPCR_P_HV_BatDschrgPwrST_Arb_Value: accessed-variable=VeBPCR_P_HV_BatDschrgPwrST_Arb.Value
              OUT_VeBPCR_b_HV_BatChrgPwrST_FA_Ovrd_Value: accessed-variable=VeBPCR_b_HV_BatChrgPwrST_FA_Ovrd.Value
              OUT_VeBPCR_P_HV_BatChrgPwrST_Arb_Value: accessed-variable=VeBPCR_P_HV_BatChrgPwrST_Arb.Value
              OUT_VeBPCR_b_HV_BatPackSOC_FA_Ovrd_Value: accessed-variable=VeBPCR_b_HV_BatPackSOC_FA_Ovrd.Value
              OUT_VeBPCR_U_CellVoltOVThrsh_Value: accessed-variable=VeBPCR_U_CellVoltOVThrsh.Value
              OUT_VeBPCR_U_CellVoltUVThrsh_Value: accessed-variable=VeBPCR_U_CellVoltUVThrsh.Value
              OUT_VeBPCR_b_HV_BatCurrSFA_Value: accessed-variable=VeBPCR_b_HV_BatCurrSFA.Value
              OUT_VeBPCR_b_HV_BatPackSOC_SFA_Value: accessed-variable=VeBPCR_b_HV_BatPackSOC_SFA.Value
              OUT_VeBPCR_b_HV_BatVoltModMaxSFA_Value: accessed-variable=VeBPCR_b_HV_BatVoltModMaxSFA.Value
              OUT_VeBPCR_b_CmdBatPwrLimSFA_Enbl_Value: accessed-variable=VeBPCR_b_CmdBatPwrLimSFA_Enbl.Value
              OUT_VeBPCR_b_HV_BatMaxModTmpSFA_Value: accessed-variable=VeBPCR_b_HV_BatMaxModTmpSFA.Value
              OUT_VeBPCR_Pct_HV_BatPackSOC_Arb_Value: accessed-variable=VeBPCR_Pct_HV_BatPackSOC_Arb.Value
              OUT_VeBPCR_Pct_HV_BatPackSOC_Ovrd_Value: accessed-variable=VeBPCR_Pct_HV_BatPackSOC_Ovrd.Value
              OUT_VeBPCR_b_MIL_OnRq_BPCM_Debounced_Value: accessed-variable=VeBPCR_b_MIL_OnRq_BPCM_Debounced.Value
              OUT_VeBPCR_b_ThrmlRnawyFlg_Value: accessed-variable=VeBPCR_b_ThrmlRnawyFlg.Value
              OUT_VeBPCR_P_TracBat_EChrgPowLongMod_Value: accessed-variable=VeBPCR_P_TracBat_EChrgPowLongMod.Value
              OUT_VeBPCR_b_StkOpnChkCmpl_Value: accessed-variable=VeBPCR_b_StkOpnChkCmpl.Value
              OUT_VeBPCR_b_BatShtOffFlg_Value: accessed-variable=VeBPCR_b_BatShtOffFlg.Value
              OUT_VeBPCR_e_BPCM_CommFail_Value: accessed-variable=VeBPCR_e_BPCM_CommFail.Value
              OUT_VeBPCR_b_BPCM_CommFailFA_Value: accessed-variable=VeBPCR_b_BPCM_CommFailFA.Value
              OUT_VeBPCR_T_BusBarTemp_Value: accessed-variable=VeBPCR_T_BusBarTemp.Value
              OUT_VeBPCR_T_BDUBusBarTemp_Value: accessed-variable=VeBPCR_T_BDUBusBarTemp.Value
              OUT_VeBPCR_e_FaultSts_HybBatPosConConCirPer_Value: accessed-variable=VeBPCR_e_FaultSts_HybBatPosConConCirPer.Value
              OUT_VeBPCR_e_DCIsolSts_Value: accessed-variable=VeBPCR_e_DCIsolSts.Value
              OUT_VeBPCR_b_DCIsolStsFA_Value: accessed-variable=VeBPCR_b_DCIsolStsFA.Value
              OUT_VeBPCR_U_HV_InternalStringVolt1_Value: accessed-variable=VeBPCR_U_HV_InternalStringVolt1.Value
              OUT_VeBPCR_b_HV_InternalStringVolt1FA_Value: accessed-variable=VeBPCR_b_HV_InternalStringVolt1FA.Value
              OUT_VeBPCR_U_HV_InternalStringVolt2_Value: accessed-variable=VeBPCR_U_HV_InternalStringVolt2.Value
              OUT_VeBPCR_b_HV_InternalStringVolt2FA_Value: accessed-variable=VeBPCR_b_HV_InternalStringVolt2FA.Value
              OUT_VeBPCR_U_HV_SeriesVolt_Value: accessed-variable=VeBPCR_U_HV_SeriesVolt.Value
              OUT_VeBPCR_b_HV_SeriesVoltFA_Value: accessed-variable=VeBPCR_b_HV_SeriesVoltFA.Value
              OUT_VeBPCR_b_HV_AuxLoadOffReq_Value: accessed-variable=VeBPCR_b_HV_AuxLoadOffReq.Value
              OUT_VeBPCR_b_HV_AuxLoadOffReqFA_Value: accessed-variable=VeBPCR_b_HV_AuxLoadOffReqFA.Value
              OUT_VeBPCR_I_HV_Current_String2_Value: accessed-variable=VeBPCR_I_HV_Current_String2.Value
              OUT_VeBPCR_b_HV_Current_String2_FA_Value: accessed-variable=VeBPCR_b_HV_Current_String2_FA.Value
              OUT_VeBPCR_U_BPCM_HV_InternalVoltage_Value: accessed-variable=VeBPCR_U_BPCM_HV_InternalVoltage.Value
              OUT_VeBPCR_b_BPCM_HV_InternalVoltage_FA_Value: accessed-variable=VeBPCR_b_BPCM_HV_InternalVoltage_FA.Value
              OUT_VeBPCR_e_HV_BatIsolStat_Value: accessed-variable=VeBPCR_e_HV_BatIsolStat.Value
              OUT_VeBPCR_e_HV_BatIsolStat_raw_Value: accessed-variable=VeBPCR_e_HV_BatIsolStat_raw.Value
              OUT_VeBPCR_e_HVTracBatCntctrConfig_Value: accessed-variable=VeBPCR_e_HVTracBatCntctrConfig.Value
              OUT_VeBPCR_b_HVTracBatCntctrConfigFA_Value: accessed-variable=VeBPCR_b_HVTracBatCntctrConfigFA.Value
              OUT_VeBPCR_e_HVDcChargeTypeStat_Value: accessed-variable=VeBPCR_e_HVDcChargeTypeStat.Value
              OUT_VeBPCR_b_HVDcChargeTypeStatFA_Value: accessed-variable=VeBPCR_b_HVDcChargeTypeStatFA.Value
              OUT_VeBPCR_b_HVBatCntrWeld_ImpdOpn_Value: accessed-variable=VeBPCR_b_HVBatCntrWeld_ImpdOpn.Value
              OUT_VeBPCR_b_Flst_HVBatCntrWeld_ImpdOpn_Value: accessed-variable=VeBPCR_b_Flst_HVBatCntrWeld_ImpdOpn.Value
          written-local-variables:
            access WV_VeBPCI_U_BatVoltModMaxArb_Init_write_IRV: accessed-variable=VeBPCI_U_BatVoltModMaxArb_Init_write_IRV
            access WV_VeBPCI_U_BatVoltModMinArb_Init_write_IRV: accessed-variable=VeBPCI_U_BatVoltModMinArb_Init_write_IRV
        BPCR_PwrOn
          data-receive-point-by-arguments:
            13 x access:
              IN_DeBPCR_P_HV_BatChrgPwrET_Rx_DeBPCR_P_HV_BatChrgPwrET: accessed-variable=DeBPCR_P_HV_BatChrgPwrET_Rx.DeBPCR_P_HV_BatChrgPwrET
              IN_DeBPCR_P_HV_BatChrgPwrLT_Rx_DeBPCR_P_HV_BatChrgPwrLT: accessed-variable=DeBPCR_P_HV_BatChrgPwrLT_Rx.DeBPCR_P_HV_BatChrgPwrLT
              IN_DeBPCR_P_HV_BatChrgPwrST_Rx_DeBPCR_P_HV_BatChrgPwrST: accessed-variable=DeBPCR_P_HV_BatChrgPwrST_Rx.DeBPCR_P_HV_BatChrgPwrST
              IN_DeBPCR_P_HV_BatDschrgPwrET_Rx_DeBPCR_P_HV_BatDschrgPwrET: accessed-variable=DeBPCR_P_HV_BatDschrgPwrET_Rx.DeBPCR_P_HV_BatDschrgPwrET
              IN_DeBPCR_P_HV_BatDschrgPwrLT_Rx_DeBPCR_P_HV_BatDschrgPwrLT: accessed-variable=DeBPCR_P_HV_BatDschrgPwrLT_Rx.DeBPCR_P_HV_BatDschrgPwrLT
              IN_DeBPCR_P_HV_BatDschrgPwrST_Rx_DeBPCR_P_HV_BatDschrgPwrST: accessed-variable=DeBPCR_P_HV_BatDschrgPwrST_Rx.DeBPCR_P_HV_BatDschrgPwrST
              IN_DeBPCR_Pct_HV_BatSOC_DS_Rx_DeBPCR_Pct_HV_BatSOC_DS: accessed-variable=DeBPCR_Pct_HV_BatSOC_DS_Rx.DeBPCR_Pct_HV_BatSOC_DS
              IN_NeBPCR_Cnt_PWMCntctrStMFOP_Rx_NeBPCR_Cnt_PWMCntctrStMFOP: accessed-variable=NeBPCR_Cnt_PWMCntctrStMFOP_Rx.NeBPCR_Cnt_PWMCntctrStMFOP
              IN_NeBPCR_T_BatModTmp_Rx_NeBPCR_T_BatModTmp: accessed-variable=NeBPCR_T_BatModTmp_Rx.NeBPCR_T_BatModTmp
              IN_NeBPCR_b_HV_BatPackSOC_FA_Ovrd_Rx_NeBPCR_b_HV_BatPackSOC_FA_Ovrd: accessed-variable=NeBPCR_b_HV_BatPackSOC_FA_Ovrd_Rx.NeBPCR_b_HV_BatPackSOC_FA_Ovrd
              IN_NeBPCR_b_HV_BatRdy_Rx_NeBPCR_b_HV_BatRdy: accessed-variable=NeBPCR_b_HV_BatRdy_Rx.NeBPCR_b_HV_BatRdy
              IN_VeHVTR_U_HV_BatVoltModMaxArb_Value: accessed-variable=VeHVTR_U_HV_BatVoltModMaxArb.Value
              IN_VeHVTR_U_HV_BatVoltModMinArb_Value: accessed-variable=VeHVTR_U_HV_BatVoltModMinArb.Value
          data-send-points:
            174 x access:
              OUT_VeBPCR_b_HV_BatModVoltMaxFA_Value: accessed-variable=VeBPCR_b_HV_BatModVoltMaxFA.Value
              OUT_VeBPCR_b_HV_BatModTempMinFA_Value: accessed-variable=VeBPCR_b_HV_BatModTempMinFA.Value
              OUT_VeBPCR_T_BusBarTemp_Value: accessed-variable=VeBPCR_T_BusBarTemp.Value
              OUT_VeBPCR_b_HV_BatModVoltAvgFA_Value: accessed-variable=VeBPCR_b_HV_BatModVoltAvgFA.Value
              OUT_VeBPCR_U_HV_BatModVoltAvg_Value: accessed-variable=VeBPCR_U_HV_BatModVoltAvg.Value
              OUT_VeBPCR_b_HV_BatModTempAvgFA_Value: accessed-variable=VeBPCR_b_HV_BatModTempAvgFA.Value
              OUT_VeBPCR_U_CellVoltLowThrsh_Value: accessed-variable=VeBPCR_U_CellVoltLowThrsh.Value
              OUT_VeBPCR_U_OCVMaxCellVoltage_Value: accessed-variable=VeBPCR_U_OCVMaxCellVoltage.Value
              OUT_VeBPCR_b_HV_BatVoltFA_Value: accessed-variable=VeBPCR_b_HV_BatVoltFA.Value
              OUT_VeBPCR_U_CellVoltHighThrsh_Value: accessed-variable=VeBPCR_U_CellVoltHighThrsh.Value
              OUT_VeBPCR_T_BDUBusBarTemp_Value: accessed-variable=VeBPCR_T_BDUBusBarTemp.Value
              OUT_VeBPCR_b_HV_BatCurrFA_Value: accessed-variable=VeBPCR_b_HV_BatCurrFA.Value
              OUT_VeBPCR_Cnt_HVBat_NumMaxVlt_Value: accessed-variable=VeBPCR_Cnt_HVBat_NumMaxVlt.Value
              OUT_VeBPCR_Cnt_HVBat_NumMinVlt_Value: accessed-variable=VeBPCR_Cnt_HVBat_NumMinVlt.Value
              OUT_VeBPCR_Cnt_HVBat_ModNumMinTmp_Value: accessed-variable=VeBPCR_Cnt_HVBat_ModNumMinTmp.Value
              OUT_VeBPCR_Cnt_HVBat_ModNumMaxTmp_Value: accessed-variable=VeBPCR_Cnt_HVBat_ModNumMaxTmp.Value
              OUT_VeBPCR_U_OCVMinCellVoltage_Value: accessed-variable=VeBPCR_U_OCVMinCellVoltage.Value
              OUT_VeBPCR_I_HV_BatCurr_Value: accessed-variable=VeBPCR_I_HV_BatCurr.Value
              OUT_VeBPCR_b_OCVMinCellVoltage_FA_Value: accessed-variable=VeBPCR_b_OCVMinCellVoltage_FA.Value
              OUT_VeBPCR_b_OCVMaxCellVoltage_FA_Value: accessed-variable=VeBPCR_b_OCVMaxCellVoltage_FA.Value
              OUT_VeBPCR_U_OCVAvgCellVoltage_Value: accessed-variable=VeBPCR_U_OCVAvgCellVoltage.Value
              OUT_VeBPCR_b_OCVAvgCellVoltage_FA_Value: accessed-variable=VeBPCR_b_OCVAvgCellVoltage_FA.Value
              OUT_VeBPCR_Z_MaxCellDschargeImpedance_Value: accessed-variable=VeBPCR_Z_MaxCellDschargeImpedance.Value
              OUT_VeBPCR_b_MaxCellDschargeImpedance_FA_Value: accessed-variable=VeBPCR_b_MaxCellDschargeImpedance_FA.Value
              OUT_VeBPCR_U_HV_BatVolt_Value: accessed-variable=VeBPCR_U_HV_BatVolt.Value
              OUT_VeBPCR_Z_MinCellDschargeImpedance_Value: accessed-variable=VeBPCR_Z_MinCellDschargeImpedance.Value
              OUT_VeBPCR_b_MinCellDschargeImpedance_FA_Value: accessed-variable=VeBPCR_b_MinCellDschargeImpedance_FA.Value
              OUT_VeBPCR_U_MaxCellVltAlld_Value: accessed-variable=VeBPCR_U_MaxCellVltAlld.Value
              OUT_VeBPCR_b_MaxCellVltAlld_FA_Value: accessed-variable=VeBPCR_b_MaxCellVltAlld_FA.Value
              OUT_VeBPCR_U_MinCellVltAlld_Value: accessed-variable=VeBPCR_U_MinCellVltAlld.Value
              OUT_VeBPCR_b_MinCellVltAlld_FA_Value: accessed-variable=VeBPCR_b_MinCellVltAlld_FA.Value
              OUT_VeBPCR_U_MaxPkVltAlld_Value: accessed-variable=VeBPCR_U_MaxPkVltAlld.Value
              OUT_VeBPCR_b_MaxPkVltAlld_FA_Value: accessed-variable=VeBPCR_b_MaxPkVltAlld_FA.Value
              OUT_VeBPCR_U_MinPkVltAlld_Value: accessed-variable=VeBPCR_U_MinPkVltAlld.Value
              OUT_VeBPCR_U_HV_BatModVoltMax_Value: accessed-variable=VeBPCR_U_HV_BatModVoltMax.Value
              OUT_VeBPCR_b_MinPkVltAlld_FA_Value: accessed-variable=VeBPCR_b_MinPkVltAlld_FA.Value
              OUT_VeBPCR_b_CellVoltHighThrshFA_Value: accessed-variable=VeBPCR_b_CellVoltHighThrshFA.Value
              OUT_VeBPCR_b_CellVoltLowThrshFA_Value: accessed-variable=VeBPCR_b_CellVoltLowThrshFA.Value
              OUT_VeBPCR_b_MaxChgCurrAlwdFA_Value: accessed-variable=VeBPCR_b_MaxChgCurrAlwdFA.Value
              OUT_VeBPCR_T_HVBatClgOutletTemp_Value: accessed-variable=VeBPCR_T_HVBatClgOutletTemp.Value
              OUT_VeBPCR_b_HVBatClgOutletTempFA_Value: accessed-variable=VeBPCR_b_HVBatClgOutletTempFA.Value
              OUT_VeBPCR_I_MaxChrgCurrAlwd_Value: accessed-variable=VeBPCR_I_MaxChrgCurrAlwd.Value
              OUT_VeBPCR_b_HV_BatModVoltMinFA_Value: accessed-variable=VeBPCR_b_HV_BatModVoltMinFA.Value
              OUT_VeBPCR_U_HV_BatModVoltMin_Value: accessed-variable=VeBPCR_U_HV_BatModVoltMin.Value
              OUT_VeBPCR_b_HV_BatModTempMaxFA_Value: accessed-variable=VeBPCR_b_HV_BatModTempMaxFA.Value
              OUT_VeBPCR_b_RemainingAmpHrCapFA_Value: accessed-variable=VeBPCR_b_RemainingAmpHrCapFA.Value
              OUT_VeBPCR_e_HV_BatInrlkStat_Value: accessed-variable=VeBPCR_e_HV_BatInrlkStat.Value
              OUT_VeBPCR_t_PrechrgPnltyTimer_Value: accessed-variable=VeBPCR_t_PrechrgPnltyTimer.Value
              OUT_VeBPCR_b_HVBatPerWUThermal_Value: accessed-variable=VeBPCR_b_HVBatPerWUThermal.Value
              OUT_VeBPCR_b_BPCM_CommFailFA_Value: accessed-variable=VeBPCR_b_BPCM_CommFailFA.Value
              OUT_VeBPCR_b_HVBatPerWakeUp_Value: accessed-variable=VeBPCR_b_HVBatPerWakeUp.Value
              OUT_VeBPCR_t_HVBatSleepTime_Value: accessed-variable=VeBPCR_t_HVBatSleepTime.Value
              OUT_VeBPCR_e_BPCMShtDwnRdy_Value: accessed-variable=VeBPCR_e_BPCMShtDwnRdy.Value
              OUT_VeBPCR_e_PwrtrnHV_IsolStat_Value: accessed-variable=VeBPCR_e_PwrtrnHV_IsolStat.Value
              OUT_VeBPCR_t_HVBattCntctrOpnTm_Value: accessed-variable=VeBPCR_t_HVBattCntctrOpnTm.Value
              OUT_VeBPCR_e_HV_BatIsolStat_Value: accessed-variable=VeBPCR_e_HV_BatIsolStat.Value
              OUT_VeBPCR_Pct_HVBatSOH_Value: accessed-variable=VeBPCR_Pct_HVBatSOH.Value
              OUT_VeBPCR_Pct_HVBatSOHLow_Value: accessed-variable=VeBPCR_Pct_HVBatSOHLow.Value
              OUT_VeBPCR_t_HVBatRealTimeClock_Value: accessed-variable=VeBPCR_t_HVBatRealTimeClock.Value
              OUT_VeBPCR_e_HVBatIntrlkIntrnlStat_Value: accessed-variable=VeBPCR_e_HVBatIntrlkIntrnlStat.Value
              OUT_VeBPCR_b_HVBatIntrlkIntrnlStatFA_Value: accessed-variable=VeBPCR_b_HVBatIntrlkIntrnlStatFA.Value
              OUT_VeBPCR_b_HEVOnRqBPCM_Value: accessed-variable=VeBPCR_b_HEVOnRqBPCM.Value
              OUT_VeBPCR_e_HVBatRdy_Value: accessed-variable=VeBPCR_e_HVBatRdy.Value
              OUT_VeBPCR_b_ChargingStat_BPCMFA_Value: accessed-variable=VeBPCR_b_ChargingStat_BPCMFA.Value
              OUT_VeBPCR_b_HVBatRealTimeClock_FA_Value: accessed-variable=VeBPCR_b_HVBatRealTimeClock_FA.Value
              OUT_VeBPCR_P_TracBat_EChrgPowLong_Value: accessed-variable=VeBPCR_P_TracBat_EChrgPowLong.Value
              OUT_VeBPCR_b_TracBat_EChrgPowLongFA_Value: accessed-variable=VeBPCR_b_TracBat_EChrgPowLongFA.Value
              OUT_VeBPCR_b_CntctrCntrl_PWM_FA_Value: accessed-variable=VeBPCR_b_CntctrCntrl_PWM_FA.Value
              OUT_VeBPCR_q_RemainingAmpHrCap_Value: accessed-variable=VeBPCR_q_RemainingAmpHrCap.Value
              OUT_VeBPCR_e_BPCM_LIN_BusOff_Value: accessed-variable=VeBPCR_e_BPCM_LIN_BusOff.Value
              OUT_VeBPCR_e_BPCM_LOC_BCP_Value: accessed-variable=VeBPCR_e_BPCM_LOC_BCP.Value
              OUT_VeBPCR_e_BPCM_LOC_BatClntHtr_Value: accessed-variable=VeBPCR_e_BPCM_LOC_BatClntHtr.Value
              OUT_VeBPCR_e_ChargingStat_BPCM_Value: accessed-variable=VeBPCR_e_ChargingStat_BPCM.Value
              OUT_VeBPCR_b_HVBatPerWU12VChrg_Value: accessed-variable=VeBPCR_b_HVBatPerWU12VChrg.Value
              OUT_VeBPCR_b_HV_BatInrlkStatFA_Value: accessed-variable=VeBPCR_b_HV_BatInrlkStatFA.Value
              OUT_VeBPCR_e_BPCM_CommFail_Value: accessed-variable=VeBPCR_e_BPCM_CommFail.Value
              OUT_VeBPCR_e_PWMDecodedCntctrSts_Value: accessed-variable=VeBPCR_e_PWMDecodedCntctrSts.Value
              OUT_VeBPCR_b_PWMTimerOOR_Value: accessed-variable=VeBPCR_b_PWMTimerOOR.Value
              OUT_VeBPCR_b_HV_BatDschrgPwrET_FA_Value: accessed-variable=VeBPCR_b_HV_BatDschrgPwrET_FA.Value
              OUT_VeBPCR_b_HV_BatChrgPwrST_FA_Value: accessed-variable=VeBPCR_b_HV_BatChrgPwrST_FA.Value
              OUT_VeBPCR_P_HV_BatChrgPwrST_Value: accessed-variable=VeBPCR_P_HV_BatChrgPwrST.Value
              OUT_VeBPCR_Pct_HV_BatPackSOC_Value: accessed-variable=VeBPCR_Pct_HV_BatPackSOC.Value
              OUT_VeBPCR_b_HV_BatPackSOC_FA_Value: accessed-variable=VeBPCR_b_HV_BatPackSOC_FA.Value
              OUT_VeBPCR_P_HV_BatDschrgPwrET_Value: accessed-variable=VeBPCR_P_HV_BatDschrgPwrET.Value
              OUT_VeBPCR_q_FullAmpHrCap_Value: accessed-variable=VeBPCR_q_FullAmpHrCap.Value
              OUT_VeBPCR_b_HV_BatDschrgPwrLT_FA_Value: accessed-variable=VeBPCR_b_HV_BatDschrgPwrLT_FA.Value
              OUT_VeBPCR_P_HV_BatDschrgPwrLT_Value: accessed-variable=VeBPCR_P_HV_BatDschrgPwrLT.Value
              OUT_VeBPCR_b_HV_BatDschrgPwrST_FA_Value: accessed-variable=VeBPCR_b_HV_BatDschrgPwrST_FA.Value
              OUT_VeBPCR_P_HV_BatDschrgPwrST_Value: accessed-variable=VeBPCR_P_HV_BatDschrgPwrST.Value
              OUT_VeBPCR_b_HV_BatChrgPwrET_FA_Value: accessed-variable=VeBPCR_b_HV_BatChrgPwrET_FA.Value
              OUT_VeBPCR_P_HV_BatChrgPwrET_Value: accessed-variable=VeBPCR_P_HV_BatChrgPwrET.Value
              OUT_VeBPCR_P_HV_BatChrgPwrLT_Value: accessed-variable=VeBPCR_P_HV_BatChrgPwrLT.Value
              OUT_VeBPCR_b_HV_BatChrgPwrLT_FA_Value: accessed-variable=VeBPCR_b_HV_BatChrgPwrLT_FA.Value
              OUT_VeBPCR_b_HVBat_DC_CntctrOpn_Value: accessed-variable=VeBPCR_b_HVBat_DC_CntctrOpn.Value
              OUT_VeBPCR_b_HVBat_DC_CntctrReq_Value: accessed-variable=VeBPCR_b_HVBat_DC_CntctrReq.Value
              OUT_VeBPCR_b_DC_Isolation_Sts_Value: accessed-variable=VeBPCR_b_DC_Isolation_Sts.Value
              OUT_VeBPCR_b_StkOpnChkCmpl_Value: accessed-variable=VeBPCR_b_StkOpnChkCmpl.Value
              OUT_VeBPCR_e_HVBat_DC_CntctrStat_Value: accessed-variable=VeBPCR_e_HVBat_DC_CntctrStat.Value
              OUT_VeBPCR_b_HVBat_DC_CntctrStat_FA_Value: accessed-variable=VeBPCR_b_HVBat_DC_CntctrStat_FA.Value
              OUT_VeBPCR_T_BatModTmp_Value: accessed-variable=VeBPCR_T_BatModTmp.Value
              OUT_VeBPCR_b_HV_BatPackSOC_FA_Ovrd_Value: accessed-variable=VeBPCR_b_HV_BatPackSOC_FA_Ovrd.Value
              OUT_VeBPCR_Pct_HV_BatPackSOC_Arb_Value: accessed-variable=VeBPCR_Pct_HV_BatPackSOC_Arb.Value
              OUT_VeBPCR_T_HV_BatModTempMax_Value: accessed-variable=VeBPCR_T_HV_BatModTempMax.Value
              OUT_VeBPCR_T_HV_BatModTempMin_Value: accessed-variable=VeBPCR_T_HV_BatModTempMin.Value
              OUT_VeBPCR_T_HV_BatModTempAvg_Value: accessed-variable=VeBPCR_T_HV_BatModTempAvg.Value
              OUT_VeBPCR_e_HV_BatCntctrStat_Value: accessed-variable=VeBPCR_e_HV_BatCntctrStat.Value
              OUT_VeBPCR_b_HV_BatCntctrStatFA_Value: accessed-variable=VeBPCR_b_HV_BatCntctrStatFA.Value
              OUT_VeBPCR_b_HV_BatCntctrOpenReq_Value: accessed-variable=VeBPCR_b_HV_BatCntctrOpenReq.Value
              OUT_VeBPCR_b_HV_BatCntctrOpenPending_Value: accessed-variable=VeBPCR_b_HV_BatCntctrOpenPending.Value
              OUT_VeBPCR_b_HVBatRdy_Value: accessed-variable=VeBPCR_b_HVBatRdy.Value
              OUT_VeBPCR_b_HEVOnRqBPCM_Debounced_Value: accessed-variable=VeBPCR_b_HEVOnRqBPCM_Debounced.Value
              OUT_VeBPCR_b_BPCM_OVActv_Value: accessed-variable=VeBPCR_b_BPCM_OVActv.Value
              OUT_VeBPCR_b_BPCM_UVActv_Value: accessed-variable=VeBPCR_b_BPCM_UVActv.Value
              OUT_VeBPCR_b_Flst_HVBatCntrWeld_ImpdOpn_Value: accessed-variable=VeBPCR_b_Flst_HVBatCntrWeld_ImpdOpn.Value
              OUT_VeBPCR_b_HVBatCntrWeld_ImpdOpn_Value: accessed-variable=VeBPCR_b_HVBatCntrWeld_ImpdOpn.Value
              OUT_VeBPCR_b_BPCM_LIN_BusOff_FA_Value: accessed-variable=VeBPCR_b_BPCM_LIN_BusOff_FA.Value
              OUT_VeBPCR_b_BPCM_LIN_BusOff_SgnlRcvd_Value: accessed-variable=VeBPCR_b_BPCM_LIN_BusOff_SgnlRcvd.Value
              OUT_VeBPCR_b_BPCM_LOC_BCP_FA_Value: accessed-variable=VeBPCR_b_BPCM_LOC_BCP_FA.Value
              OUT_VeBPCR_b_BPCM_LOC_BCP_SgnlRcvd_Value: accessed-variable=VeBPCR_b_BPCM_LOC_BCP_SgnlRcvd.Value
              OUT_VeBPCR_b_BPCM_LOC_BatClntHtr_FA_Value: accessed-variable=VeBPCR_b_BPCM_LOC_BatClntHtr_FA.Value
              OUT_VeBPCR_b_BPCM_LOC_BatClntHtr_SgnlRcvd_Value: accessed-variable=VeBPCR_b_BPCM_LOC_BatClntHtr_SgnlRcvd.Value
              OUT_VeBPCR_b_HV_BatDschrgPwrETSgnl_Rcvd_Value: accessed-variable=VeBPCR_b_HV_BatDschrgPwrETSgnl_Rcvd.Value
              OUT_VeBPCR_b_HV_BatDschrgPwrLTSgnl_Rcvd_Value: accessed-variable=VeBPCR_b_HV_BatDschrgPwrLTSgnl_Rcvd.Value
              OUT_VeBPCR_b_HV_BatDschrgPwrSTSgnl_Rcvd_Value: accessed-variable=VeBPCR_b_HV_BatDschrgPwrSTSgnl_Rcvd.Value
              OUT_VeBPCR_b_HV_BatChrgPwrETSgnl_Rcvd_Value: accessed-variable=VeBPCR_b_HV_BatChrgPwrETSgnl_Rcvd.Value
              OUT_VeBPCR_b_HV_BatChrgPwrLTSgnl_Rcvd_Value: accessed-variable=VeBPCR_b_HV_BatChrgPwrLTSgnl_Rcvd.Value
              OUT_VeBPCR_b_HV_BatChrgPwrSTSgnl_Rcvd_Value: accessed-variable=VeBPCR_b_HV_BatChrgPwrSTSgnl_Rcvd.Value
              OUT_VeBPCR_b_HV_BatPackSOC_SgnlRcvd_Value: accessed-variable=VeBPCR_b_HV_BatPackSOC_SgnlRcvd.Value
              OUT_VeBPCR_T_HV_BatModTempMax_Arb_Value: accessed-variable=VeBPCR_T_HV_BatModTempMax_Arb.Value
              OUT_VeBPCR_T_HV_BatModTempMin_Arb_Value: accessed-variable=VeBPCR_T_HV_BatModTempMin_Arb.Value
              OUT_VeBPCR_b_HV_BatDschrgPwrLT_FA_Ovrd_Value: accessed-variable=VeBPCR_b_HV_BatDschrgPwrLT_FA_Ovrd.Value
              OUT_VeBPCR_P_HV_BatDschrgPwrLT_Arb_Value: accessed-variable=VeBPCR_P_HV_BatDschrgPwrLT_Arb.Value
              OUT_VeBPCR_b_HV_BatChrgPwrLT_FA_Ovrd_Value: accessed-variable=VeBPCR_b_HV_BatChrgPwrLT_FA_Ovrd.Value
              OUT_VeBPCR_P_HV_BatChrgPwrLT_Arb_Value: accessed-variable=VeBPCR_P_HV_BatChrgPwrLT_Arb.Value
              OUT_VeBPCR_b_HV_BatDschrgPwrET_FA_Ovrd_Value: accessed-variable=VeBPCR_b_HV_BatDschrgPwrET_FA_Ovrd.Value
              OUT_VeBPCR_P_HV_BatDschrgPwrET_Arb_Value: accessed-variable=VeBPCR_P_HV_BatDschrgPwrET_Arb.Value
              OUT_VeBPCR_b_HV_BatChrgPwrET_FA_Ovrd_Value: accessed-variable=VeBPCR_b_HV_BatChrgPwrET_FA_Ovrd.Value
              OUT_VeBPCR_P_HV_BatChrgPwrET_Arb_Value: accessed-variable=VeBPCR_P_HV_BatChrgPwrET_Arb.Value
              OUT_VeBPCR_b_HV_BatDschrgPwrST_FA_Ovrd_Value: accessed-variable=VeBPCR_b_HV_BatDschrgPwrST_FA_Ovrd.Value
              OUT_VeBPCR_P_HV_BatDschrgPwrST_Arb_Value: accessed-variable=VeBPCR_P_HV_BatDschrgPwrST_Arb.Value
              OUT_VeBPCR_b_HV_BatChrgPwrST_FA_Ovrd_Value: accessed-variable=VeBPCR_b_HV_BatChrgPwrST_FA_Ovrd.Value
              OUT_VeBPCR_P_HV_BatChrgPwrST_Arb_Value: accessed-variable=VeBPCR_P_HV_BatChrgPwrST_Arb.Value
              OUT_VeBPCR_U_CellVoltOVThrsh_Value: accessed-variable=VeBPCR_U_CellVoltOVThrsh.Value
              OUT_VeBPCR_U_CellVoltUVThrsh_Value: accessed-variable=VeBPCR_U_CellVoltUVThrsh.Value
              OUT_VeBPCR_b_HV_BatCurrSFA_Value: accessed-variable=VeBPCR_b_HV_BatCurrSFA.Value
              OUT_VeBPCR_b_HV_BatPackSOC_SFA_Value: accessed-variable=VeBPCR_b_HV_BatPackSOC_SFA.Value
              OUT_VeBPCR_b_HV_BatVoltModMaxSFA_Value: accessed-variable=VeBPCR_b_HV_BatVoltModMaxSFA.Value
              OUT_VeBPCR_b_CmdBatPwrLimSFA_Enbl_Value: accessed-variable=VeBPCR_b_CmdBatPwrLimSFA_Enbl.Value
              OUT_VeBPCR_b_HV_BatMaxModTmpSFA_Value: accessed-variable=VeBPCR_b_HV_BatMaxModTmpSFA.Value
              OUT_VeBPCR_Pct_HV_BatPackSOC_Ovrd_Value: accessed-variable=VeBPCR_Pct_HV_BatPackSOC_Ovrd.Value
              OUT_VeBPCR_b_MIL_OnRq_BPCM_Debounced_Value: accessed-variable=VeBPCR_b_MIL_OnRq_BPCM_Debounced.Value
              OUT_VeBPCR_b_ThrmlRnawyFlg_Value: accessed-variable=VeBPCR_b_ThrmlRnawyFlg.Value
              OUT_VeBPCR_P_TracBat_EChrgPowLongMod_Value: accessed-variable=VeBPCR_P_TracBat_EChrgPowLongMod.Value
              OUT_VeBPCR_b_BatShtOffFlg_Value: accessed-variable=VeBPCR_b_BatShtOffFlg.Value
              OUT_VeBPCR_e_FaultSts_HybBatPosConConCirPer_Value: accessed-variable=VeBPCR_e_FaultSts_HybBatPosConConCirPer.Value
              OUT_VeBPCR_e_DCIsolSts_Value: accessed-variable=VeBPCR_e_DCIsolSts.Value
              OUT_VeBPCR_b_DCIsolStsFA_Value: accessed-variable=VeBPCR_b_DCIsolStsFA.Value
              OUT_VeBPCR_b_HV_InternalStringVolt1FA_Value: accessed-variable=VeBPCR_b_HV_InternalStringVolt1FA.Value
              OUT_VeBPCR_U_HV_InternalStringVolt1_Value: accessed-variable=VeBPCR_U_HV_InternalStringVolt1.Value
              OUT_VeBPCR_b_HV_InternalStringVolt2FA_Value: accessed-variable=VeBPCR_b_HV_InternalStringVolt2FA.Value
              OUT_VeBPCR_U_HV_InternalStringVolt2_Value: accessed-variable=VeBPCR_U_HV_InternalStringVolt2.Value
              OUT_VeBPCR_b_HV_SeriesVoltFA_Value: accessed-variable=VeBPCR_b_HV_SeriesVoltFA.Value
              OUT_VeBPCR_U_HV_SeriesVolt_Value: accessed-variable=VeBPCR_U_HV_SeriesVolt.Value
              OUT_VeBPCR_e_HVTracBatCntctrConfig_Value: accessed-variable=VeBPCR_e_HVTracBatCntctrConfig.Value
              OUT_VeBPCR_b_HVTracBatCntctrConfigFA_Value: accessed-variable=VeBPCR_b_HVTracBatCntctrConfigFA.Value
              OUT_VeBPCR_e_HVDcChargeTypeStat_Value: accessed-variable=VeBPCR_e_HVDcChargeTypeStat.Value
              OUT_VeBPCR_b_HVDcChargeTypeStatFA_Value: accessed-variable=VeBPCR_b_HVDcChargeTypeStatFA.Value
              OUT_VeBPCR_b_HV_AuxLoadOffReq_Value: accessed-variable=VeBPCR_b_HV_AuxLoadOffReq.Value
              OUT_VeBPCR_b_HV_AuxLoadOffReqFA_Value: accessed-variable=VeBPCR_b_HV_AuxLoadOffReqFA.Value
              OUT_VeBPCR_I_HV_Current_String2_Value: accessed-variable=VeBPCR_I_HV_Current_String2.Value
              OUT_VeBPCR_b_HV_Current_String2_FA_Value: accessed-variable=VeBPCR_b_HV_Current_String2_FA.Value
              OUT_VeBPCR_U_BPCM_HV_InternalVoltage_Value: accessed-variable=VeBPCR_U_BPCM_HV_InternalVoltage.Value
              OUT_VeBPCR_b_BPCM_HV_InternalVoltage_FA_Value: accessed-variable=VeBPCR_b_BPCM_HV_InternalVoltage_FA.Value
              OUT_VeBPCR_e_HV_BatIsolStat_raw_Value: accessed-variable=VeBPCR_e_HV_BatIsolStat_raw.Value
          written-local-variables:
            56 x access:
              WV_BSW_PWMCntctrTmr_write_IRV: accessed-variable=BSW_PWMCntctrTmr_write_IRV
              WV_BSW_PWMTmrRcvd_write_IRV: accessed-variable=BSW_PWMTmrRcvd_write_IRV
              WV_CellVoltHighThrshFAInit_write_IRV: accessed-variable=CellVoltHighThrshFAInit_write_IRV
              WV_CellVoltHighThrsh_write_IRV: accessed-variable=CellVoltHighThrsh_write_IRV
              WV_CellVoltLowThrshFAInit_write_IRV: accessed-variable=CellVoltLowThrshFAInit_write_IRV
              WV_CellVoltLowThrsh_write_IRV: accessed-variable=CellVoltLowThrsh_write_IRV
              WV_CntctrCntrl_PWM_write_IRV: accessed-variable=CntctrCntrl_PWM_write_IRV
              WV_HEVOnRqBPCM_write_IRV: accessed-variable=HEVOnRqBPCM_write_IRV
              WV_HVBatChrgPowET_FA_Init_write_IRV: accessed-variable=HVBatChrgPowET_FA_Init_write_IRV
              WV_HVBatChrgPowET_Init_write_IRV: accessed-variable=HVBatChrgPowET_Init_write_IRV
              WV_HVBatChrgPowLT_FA_Init_write_IRV: accessed-variable=HVBatChrgPowLT_FA_Init_write_IRV
              WV_HVBatChrgPowLT_Init_write_IRV: accessed-variable=HVBatChrgPowLT_Init_write_IRV
              WV_HVBatChrgPowST_FA_Init_write_IRV: accessed-variable=HVBatChrgPowST_FA_Init_write_IRV
              WV_HVBatChrgPowST_Init_write_IRV: accessed-variable=HVBatChrgPowST_Init_write_IRV
              WV_HVBatCntrWeld_ImpdOpn_write_IRV: accessed-variable=HVBatCntrWeld_ImpdOpn_write_IRV
              WV_HVBatDschrgPowET_FA_Init_write_IRV: accessed-variable=HVBatDschrgPowET_FA_Init_write_IRV
              WV_HVBatDschrgPowET_Init_write_IRV: accessed-variable=HVBatDschrgPowET_Init_write_IRV
              WV_HVBatDschrgPowLT_FA_Init_write_IRV: accessed-variable=HVBatDschrgPowLT_FA_Init_write_IRV
              WV_HVBatDschrgPowLT_Init_write_IRV: accessed-variable=HVBatDschrgPowLT_Init_write_IRV
              WV_HVBatDschrgPowST_FA_Init_write_IRV: accessed-variable=HVBatDschrgPowST_FA_Init_write_IRV
              WV_HVBatDschrgPowST_Init_write_IRV: accessed-variable=HVBatDschrgPowST_Init_write_IRV
              WV_HVBatPackSOC_FA_Init_write_IRV: accessed-variable=HVBatPackSOC_FA_Init_write_IRV
              WV_HVBatPackSOC_Init_write_IRV: accessed-variable=HVBatPackSOC_Init_write_IRV
              WV_HVBatRdy_Init_write_IRV: accessed-variable=HVBatRdy_Init_write_IRV
              WV_HVBat_ThrmlRnawy_WarnFA_Init_write_IRV: accessed-variable=HVBat_ThrmlRnawy_WarnFA_Init_write_IRV
              WV_HVBat_ThrmlRnawy_Warn_Init_write_IRV: accessed-variable=HVBat_ThrmlRnawy_Warn_Init_write_IRV
              WV_HV_BatCntctrOpenPending_write_IRV: accessed-variable=HV_BatCntctrOpenPending_write_IRV
              WV_HV_BatCntctrOpenReq_write_IRV: accessed-variable=HV_BatCntctrOpenReq_write_IRV
              WV_HV_BatCntctrStatFA_write_IRV: accessed-variable=HV_BatCntctrStatFA_write_IRV
              WV_HV_BatCntctrStat_write_IRV: accessed-variable=HV_BatCntctrStat_write_IRV
              WV_HV_BatCurrFA_write_IRV: accessed-variable=HV_BatCurrFA_write_IRV
              WV_HV_BatModTempAvgFA_write_IRV: accessed-variable=HV_BatModTempAvgFA_write_IRV
              WV_HV_BatModTempAvg_write_IRV: accessed-variable=HV_BatModTempAvg_write_IRV
              WV_HV_BatModTempMaxFA_write_IRV: accessed-variable=HV_BatModTempMaxFA_write_IRV
              WV_HV_BatModTempMax_write_IRV: accessed-variable=HV_BatModTempMax_write_IRV
              WV_HV_BatModTempMinFA_write_IRV: accessed-variable=HV_BatModTempMinFA_write_IRV
              WV_HV_BatModTempMin_write_IRV: accessed-variable=HV_BatModTempMin_write_IRV
              WV_HV_BatModVoltMaxFA_write_IRV: accessed-variable=HV_BatModVoltMaxFA_write_IRV
              WV_HV_BatModVoltMax_write_IRV: accessed-variable=HV_BatModVoltMax_write_IRV
              WV_HV_BatModVoltMinFA_write_IRV: accessed-variable=HV_BatModVoltMinFA_write_IRV
              WV_HV_BatModVoltMin_write_IRV: accessed-variable=HV_BatModVoltMin_write_IRV
              WV_HV_BatRdySgnl_Rcvd_write_IRV: accessed-variable=HV_BatRdySgnl_Rcvd_write_IRV
              WV_MILOnRqBPCM_Init_write_IRV: accessed-variable=MILOnRqBPCM_Init_write_IRV
              WV_PwrLimON_IRV: accessed-variable=PwrLimON_IRV
              WV_TracBat_EChrgPowLongV_write_IRV: accessed-variable=TracBat_EChrgPowLongV_write_IRV
              WV_TracBat_EChrgPowLong_write_IRV: accessed-variable=TracBat_EChrgPowLong_write_IRV
              WV_VeBPCI_U_BatVoltModMaxArb_Init_write_IRV: accessed-variable=VeBPCI_U_BatVoltModMaxArb_Init_write_IRV
              WV_VeBPCI_U_BatVoltModMaxArb_write_IRV: accessed-variable=VeBPCI_U_BatVoltModMaxArb_write_IRV
              WV_VeBPCI_U_BatVoltModMinArb_Init_write_IRV: accessed-variable=VeBPCI_U_BatVoltModMinArb_Init_write_IRV
              WV_VeBPCI_U_BatVoltModMinArb_write_IRV: accessed-variable=VeBPCI_U_BatVoltModMinArb_write_IRV
              WV_VeBPCR_T_BatModTmp_write_IRV: accessed-variable=VeBPCR_T_BatModTmp_write_IRV
              WV_VeBPCR_T_HV_BatModTempMax_write_IRV: accessed-variable=VeBPCR_T_HV_BatModTempMax_write_IRV
              WV_VeBPCR_T_HV_BatModTempMin_write_IRV: accessed-variable=VeBPCR_T_HV_BatModTempMin_write_IRV
              WV_VeBPCR_b_PWMBlankAct_write_IRV: accessed-variable=VeBPCR_b_PWMBlankAct_write_IRV
              WV_VeBPCR_b_PWMTimerOOR_write_IRV: accessed-variable=VeBPCR_b_PWMTimerOOR_write_IRV
              WV_VeBPCR_e_PWMDecodedCntctrSts_write_IRV: accessed-variable=VeBPCR_e_PWMDecodedCntctrSts_write_IRV
        BPCR_FastTEF
          data-send-points:
            access OUT_VeBPCR_e_PWMDecodedCntctrSts_Value: accessed-variable=VeBPCR_e_PWMDecodedCntctrSts.Value
            access OUT_VeBPCR_b_PWMTimerOOR_Value: accessed-variable=VeBPCR_b_PWMTimerOOR.Value
          read-local-variables:
            access RV_BSW_PWMTmrRcvd_write_IRV: accessed-variable=BSW_PWMTmrRcvd_write_IRV
          written-local-variables:
            access WV_VeBPCR_b_PWMBlankAct_write_IRV: accessed-variable=VeBPCR_b_PWMBlankAct_write_IRV
            access WV_VeBPCR_b_PWMTimerOOR_write_IRV: accessed-variable=VeBPCR_b_PWMTimerOOR_write_IRV
            access WV_VeBPCR_e_PWMDecodedCntctrSts_write_IRV: accessed-variable=VeBPCR_e_PWMDecodedCntctrSts_write_IRV
        BPCR_MedTEB
          data-receive-point-by-arguments:
            6 x access:
              IN_VeCSVR_v_VehSpd_Value: accessed-variable=VeCSVR_v_VehSpd.Value
              IN_VeDMAB_y_StatusByte_LosCommBECM_A_Value: accessed-variable=VeDMAB_y_StatusByte_LosCommBECM_A.Value
              IN_VeDMAB_y_StatusByte_LosCommBECM_A_CANC11_Value: accessed-variable=VeDMAB_y_StatusByte_LosCommBECM_A_CANC11.Value
              IN_VeHVTR_U_HV_BatVoltModMaxArb_Value: accessed-variable=VeHVTR_U_HV_BatVoltModMaxArb.Value
              IN_VeHVTR_U_HV_BatVoltModMinArb_Value: accessed-variable=VeHVTR_U_HV_BatVoltModMinArb.Value
              IN_VeTHMR_b_HVBR_OvrdReq_Value: accessed-variable=VeTHMR_b_HVBR_OvrdReq.Value
          data-send-points:
            17 x access:
              OUT_VeBPCR_T_HV_BatModTempMax_Value: accessed-variable=VeBPCR_T_HV_BatModTempMax.Value
              OUT_VeBPCR_T_HV_BatModTempMin_Value: accessed-variable=VeBPCR_T_HV_BatModTempMin.Value
              OUT_VeBPCR_T_HV_BatModTempAvg_Value: accessed-variable=VeBPCR_T_HV_BatModTempAvg.Value
              OUT_VeBPCR_b_HEVOnRqBPCM_Debounced_Value: accessed-variable=VeBPCR_b_HEVOnRqBPCM_Debounced.Value
              OUT_VeBPCR_b_HVBatCntrWeld_ImpdOpn_Value: accessed-variable=VeBPCR_b_HVBatCntrWeld_ImpdOpn.Value
              OUT_VeBPCR_b_MIL_OnRq_BPCM_Debounced_Value: accessed-variable=VeBPCR_b_MIL_OnRq_BPCM_Debounced.Value
              OUT_VeBPCR_b_HV_BatCntctrOpenPending_Value: accessed-variable=VeBPCR_b_HV_BatCntctrOpenPending.Value
              OUT_VeBPCR_b_HVBatRdy_Value: accessed-variable=VeBPCR_b_HVBatRdy.Value
              OUT_VeBPCR_b_BPCM_OVActv_Value: accessed-variable=VeBPCR_b_BPCM_OVActv.Value
              OUT_VeBPCR_b_BPCM_UVActv_Value: accessed-variable=VeBPCR_b_BPCM_UVActv.Value
              OUT_VeBPCR_e_HV_BatCntctrStat_Value: accessed-variable=VeBPCR_e_HV_BatCntctrStat.Value
              OUT_VeBPCR_b_HV_BatCntctrStatFA_Value: accessed-variable=VeBPCR_b_HV_BatCntctrStatFA.Value
              OUT_VeBPCR_b_HV_BatCntctrOpenReq_Value: accessed-variable=VeBPCR_b_HV_BatCntctrOpenReq.Value
              OUT_VeBPCR_b_ThrmlRnawyFlg_Value: accessed-variable=VeBPCR_b_ThrmlRnawyFlg.Value
              OUT_VeBPCR_b_BatShtOffFlg_Value: accessed-variable=VeBPCR_b_BatShtOffFlg.Value
              OUT_VeBPCR_e_FaultSts_HybBatPosConConCirPer_Value: accessed-variable=VeBPCR_e_FaultSts_HybBatPosConConCirPer.Value
              OUT_VeBPCR_b_PwrLimON_Value: accessed-variable=VeBPCR_b_PwrLimON.Value
          read-local-variables:
            31 x access:
              RV_CellVoltHighThrsh_write_IRV: accessed-variable=CellVoltHighThrsh_write_IRV
              RV_CellVoltLowThrsh_write_IRV: accessed-variable=CellVoltLowThrsh_write_IRV
              RV_HEVOnRqBPCM_write_IRV: accessed-variable=HEVOnRqBPCM_write_IRV
              RV_HVBatCntrWeld_ImpdOpn_write_IRV: accessed-variable=HVBatCntrWeld_ImpdOpn_write_IRV
              RV_HVBatRdy_Init_write_IRV: accessed-variable=HVBatRdy_Init_write_IRV
              RV_HVBat_ThrmlRnawy_WarnFA_Init_write_IRV: accessed-variable=HVBat_ThrmlRnawy_WarnFA_Init_write_IRV
              RV_HVBat_ThrmlRnawy_Warn_Init_write_IRV: accessed-variable=HVBat_ThrmlRnawy_Warn_Init_write_IRV
              RV_HV_BatCntctrOpenPending_write_IRV: accessed-variable=HV_BatCntctrOpenPending_write_IRV
              RV_HV_BatCntctrOpenReq_write_IRV: accessed-variable=HV_BatCntctrOpenReq_write_IRV
              RV_HV_BatCntctrStatFA_write_IRV: accessed-variable=HV_BatCntctrStatFA_write_IRV
              RV_HV_BatCntctrStat_write_IRV: accessed-variable=HV_BatCntctrStat_write_IRV
              RV_HV_BatModTempAvgFA_write_IRV: accessed-variable=HV_BatModTempAvgFA_write_IRV
              RV_HV_BatModTempAvg_write_IRV: accessed-variable=HV_BatModTempAvg_write_IRV
              RV_HV_BatModTempMaxFA_write_IRV: accessed-variable=HV_BatModTempMaxFA_write_IRV
              RV_HV_BatModTempMax_write_IRV: accessed-variable=HV_BatModTempMax_write_IRV
              RV_HV_BatModTempMinFA_write_IRV: accessed-variable=HV_BatModTempMinFA_write_IRV
              RV_HV_BatModTempMin_write_IRV: accessed-variable=HV_BatModTempMin_write_IRV
              RV_HV_BatModVoltMaxFA_write_IRV: accessed-variable=HV_BatModVoltMaxFA_write_IRV
              RV_HV_BatModVoltMax_write_IRV: accessed-variable=HV_BatModVoltMax_write_IRV
              RV_HV_BatModVoltMinFA_write_IRV: accessed-variable=HV_BatModVoltMinFA_write_IRV
              RV_HV_BatModVoltMin_write_IRV: accessed-variable=HV_BatModVoltMin_write_IRV
              RV_HV_BatRdySgnl_Rcvd_write_IRV: accessed-variable=HV_BatRdySgnl_Rcvd_write_IRV
              RV_MILOnRqBPCM_Init_write_IRV: accessed-variable=MILOnRqBPCM_Init_write_IRV
              RV_PwrLimON_IRV: accessed-variable=PwrLimON_IRV
              RV_VeBPCI_U_BatVoltModMaxArb_Init_write_IRV: accessed-variable=VeBPCI_U_BatVoltModMaxArb_Init_write_IRV
              RV_VeBPCI_U_BatVoltModMinArb_Init_write_IRV: accessed-variable=VeBPCI_U_BatVoltModMinArb_Init_write_IRV
              RV_VeBPCR_b_HVBatCntrWeld_ImpdOpnSgnl_Rcvd_write_IRV: accessed-variable=VeBPCR_b_HVBatCntrWeld_ImpdOpnSgnl_Rcvd_write_IRV
              RV_VeBPCR_b_HV_BatModTempAvgSgnl_Rcvd_write_IRV: accessed-variable=VeBPCR_b_HV_BatModTempAvgSgnl_Rcvd_write_IRV
              RV_VeBPCR_b_HV_BatModTempMaxSgnl_Rcvd_write_IRV: accessed-variable=VeBPCR_b_HV_BatModTempMaxSgnl_Rcvd_write_IRV
              RV_VeBPCR_b_HV_BatModTempMinSgnl_Rcvd_write_IRV: accessed-variable=VeBPCR_b_HV_BatModTempMinSgnl_Rcvd_write_IRV
              RV_VeBPCR_e_PWMDecodedCntctrSts_write_IRV: accessed-variable=VeBPCR_e_PWMDecodedCntctrSts_write_IRV
          written-local-variables:
            4 x access:
              WV_VeBPCI_U_BatVoltModMaxArb_write_IRV: accessed-variable=VeBPCI_U_BatVoltModMaxArb_write_IRV
              WV_VeBPCI_U_BatVoltModMinArb_write_IRV: accessed-variable=VeBPCI_U_BatVoltModMinArb_write_IRV
              WV_VeBPCR_T_HV_BatModTempMax_write_IRV: accessed-variable=VeBPCR_T_HV_BatModTempMax_write_IRV
              WV_VeBPCR_T_HV_BatModTempMin_write_IRV: accessed-variable=VeBPCR_T_HV_BatModTempMin_write_IRV
        BPCR_MedTEH
          data-receive-point-by-arguments:
            access IN_VeHVTR_I_HV_BatCurrArb_Value: accessed-variable=VeHVTR_I_HV_BatCurrArb.Value
          data-send-points:
            26 x access:
              OUT_VeBPCR_T_BatModTmp_Value: accessed-variable=VeBPCR_T_BatModTmp.Value
              OUT_VeBPCR_b_HV_BatPackSOC_FA_Ovrd_Value: accessed-variable=VeBPCR_b_HV_BatPackSOC_FA_Ovrd.Value
              OUT_VeBPCR_T_HV_BatModTempMax_Arb_Value: accessed-variable=VeBPCR_T_HV_BatModTempMax_Arb.Value
              OUT_VeBPCR_T_HV_BatModTempMin_Arb_Value: accessed-variable=VeBPCR_T_HV_BatModTempMin_Arb.Value
              OUT_VeBPCR_b_HV_BatDschrgPwrLT_FA_Ovrd_Value: accessed-variable=VeBPCR_b_HV_BatDschrgPwrLT_FA_Ovrd.Value
              OUT_VeBPCR_P_HV_BatDschrgPwrLT_Arb_Value: accessed-variable=VeBPCR_P_HV_BatDschrgPwrLT_Arb.Value
              OUT_VeBPCR_b_HV_BatChrgPwrLT_FA_Ovrd_Value: accessed-variable=VeBPCR_b_HV_BatChrgPwrLT_FA_Ovrd.Value
              OUT_VeBPCR_P_HV_BatChrgPwrLT_Arb_Value: accessed-variable=VeBPCR_P_HV_BatChrgPwrLT_Arb.Value
              OUT_VeBPCR_b_HV_BatDschrgPwrET_FA_Ovrd_Value: accessed-variable=VeBPCR_b_HV_BatDschrgPwrET_FA_Ovrd.Value
              OUT_VeBPCR_P_HV_BatDschrgPwrET_Arb_Value: accessed-variable=VeBPCR_P_HV_BatDschrgPwrET_Arb.Value
              OUT_VeBPCR_b_HV_BatChrgPwrET_FA_Ovrd_Value: accessed-variable=VeBPCR_b_HV_BatChrgPwrET_FA_Ovrd.Value
              OUT_VeBPCR_P_HV_BatChrgPwrET_Arb_Value: accessed-variable=VeBPCR_P_HV_BatChrgPwrET_Arb.Value
              OUT_VeBPCR_b_HV_BatDschrgPwrST_FA_Ovrd_Value: accessed-variable=VeBPCR_b_HV_BatDschrgPwrST_FA_Ovrd.Value
              OUT_VeBPCR_P_HV_BatDschrgPwrST_Arb_Value: accessed-variable=VeBPCR_P_HV_BatDschrgPwrST_Arb.Value
              OUT_VeBPCR_b_HV_BatChrgPwrST_FA_Ovrd_Value: accessed-variable=VeBPCR_b_HV_BatChrgPwrST_FA_Ovrd.Value
              OUT_VeBPCR_P_HV_BatChrgPwrST_Arb_Value: accessed-variable=VeBPCR_P_HV_BatChrgPwrST_Arb.Value
              OUT_VeBPCR_U_CellVoltOVThrsh_Value: accessed-variable=VeBPCR_U_CellVoltOVThrsh.Value
              OUT_VeBPCR_U_CellVoltUVThrsh_Value: accessed-variable=VeBPCR_U_CellVoltUVThrsh.Value
              OUT_VeBPCR_b_HV_BatCurrSFA_Value: accessed-variable=VeBPCR_b_HV_BatCurrSFA.Value
              OUT_VeBPCR_b_HV_BatPackSOC_SFA_Value: accessed-variable=VeBPCR_b_HV_BatPackSOC_SFA.Value
              OUT_VeBPCR_b_HV_BatVoltModMaxSFA_Value: accessed-variable=VeBPCR_b_HV_BatVoltModMaxSFA.Value
              OUT_VeBPCR_b_CmdBatPwrLimSFA_Enbl_Value: accessed-variable=VeBPCR_b_CmdBatPwrLimSFA_Enbl.Value
              OUT_VeBPCR_b_HV_BatMaxModTmpSFA_Value: accessed-variable=VeBPCR_b_HV_BatMaxModTmpSFA.Value
              OUT_VeBPCR_Pct_HV_BatPackSOC_Ovrd_Value: accessed-variable=VeBPCR_Pct_HV_BatPackSOC_Ovrd.Value
              OUT_VeBPCR_P_TracBat_EChrgPowLongMod_Value: accessed-variable=VeBPCR_P_TracBat_EChrgPowLongMod.Value
              OUT_VeBPCR_Pct_HV_BatPackSOC_Arb_Value: accessed-variable=VeBPCR_Pct_HV_BatPackSOC_Arb.Value
          read-local-variables:
            38 x access:
              RV_CellVoltHighThrshFAInit_write_IRV: accessed-variable=CellVoltHighThrshFAInit_write_IRV
              RV_CellVoltHighThrsh_write_IRV: accessed-variable=CellVoltHighThrsh_write_IRV
              RV_CellVoltLowThrshFAInit_write_IRV: accessed-variable=CellVoltLowThrshFAInit_write_IRV
              RV_CellVoltLowThrsh_write_IRV: accessed-variable=CellVoltLowThrsh_write_IRV
              RV_HVBatChrgPowET_FA_Init_write_IRV: accessed-variable=HVBatChrgPowET_FA_Init_write_IRV
              RV_HVBatChrgPowET_Init_write_IRV: accessed-variable=HVBatChrgPowET_Init_write_IRV
              RV_HVBatChrgPowLT_FA_Init_write_IRV: accessed-variable=HVBatChrgPowLT_FA_Init_write_IRV
              RV_HVBatChrgPowLT_Init_write_IRV: accessed-variable=HVBatChrgPowLT_Init_write_IRV
              RV_HVBatChrgPowST_FA_Init_write_IRV: accessed-variable=HVBatChrgPowST_FA_Init_write_IRV
              RV_HVBatChrgPowST_Init_write_IRV: accessed-variable=HVBatChrgPowST_Init_write_IRV
              RV_HVBatDschrgPowET_FA_Init_write_IRV: accessed-variable=HVBatDschrgPowET_FA_Init_write_IRV
              RV_HVBatDschrgPowET_Init_write_IRV: accessed-variable=HVBatDschrgPowET_Init_write_IRV
              RV_HVBatDschrgPowLT_FA_Init_write_IRV: accessed-variable=HVBatDschrgPowLT_FA_Init_write_IRV
              RV_HVBatDschrgPowLT_Init_write_IRV: accessed-variable=HVBatDschrgPowLT_Init_write_IRV
              RV_HVBatDschrgPowST_FA_Init_write_IRV: accessed-variable=HVBatDschrgPowST_FA_Init_write_IRV
              RV_HVBatDschrgPowST_Init_write_IRV: accessed-variable=HVBatDschrgPowST_Init_write_IRV
              RV_HVBatPackSOC_FA_Init_write_IRV: accessed-variable=HVBatPackSOC_FA_Init_write_IRV
              RV_HVBatPackSOC_Init_write_IRV: accessed-variable=HVBatPackSOC_Init_write_IRV
              RV_HV_BatCurrFA_write_IRV: accessed-variable=HV_BatCurrFA_write_IRV
              RV_HV_BatModTempMaxFA_write_IRV: accessed-variable=HV_BatModTempMaxFA_write_IRV
              RV_HV_BatModTempMinFA_write_IRV: accessed-variable=HV_BatModTempMinFA_write_IRV
              RV_HV_BatModVoltMaxFA_write_IRV: accessed-variable=HV_BatModVoltMaxFA_write_IRV
              RV_TracBat_EChrgPowLongV_write_IRV: accessed-variable=TracBat_EChrgPowLongV_write_IRV
              RV_TracBat_EChrgPowLong_write_IRV: accessed-variable=TracBat_EChrgPowLong_write_IRV
              RV_VeBPCI_U_BatVoltModMaxArb_write_IRV: accessed-variable=VeBPCI_U_BatVoltModMaxArb_write_IRV
              RV_VeBPCI_U_BatVoltModMinArb_write_IRV: accessed-variable=VeBPCI_U_BatVoltModMinArb_write_IRV
              RV_VeBPCR_T_BatModTmp_write_IRV: accessed-variable=VeBPCR_T_BatModTmp_write_IRV
              RV_VeBPCR_T_HV_BatModTempMax_write_IRV: accessed-variable=VeBPCR_T_HV_BatModTempMax_write_IRV
              RV_VeBPCR_T_HV_BatModTempMin_write_IRV: accessed-variable=VeBPCR_T_HV_BatModTempMin_write_IRV
              RV_VeBPCR_b_HV_BatChrgPwrETSgnl_Rcvd_write_IRV: accessed-variable=VeBPCR_b_HV_BatChrgPwrETSgnl_Rcvd_write_IRV
              RV_VeBPCR_b_HV_BatChrgPwrLTSgnl_Rcvd_write_IRV: accessed-variable=VeBPCR_b_HV_BatChrgPwrLTSgnl_Rcvd_write_IRV
              RV_VeBPCR_b_HV_BatChrgPwrSTSgnl_Rcvd_write_IRV: accessed-variable=VeBPCR_b_HV_BatChrgPwrSTSgnl_Rcvd_write_IRV
              RV_VeBPCR_b_HV_BatDschrgPwrETSgnl_Rcvd_write_IRV: accessed-variable=VeBPCR_b_HV_BatDschrgPwrETSgnl_Rcvd_write_IRV
              RV_VeBPCR_b_HV_BatDschrgPwrLTSgnl_Rcvd_write_IRV: accessed-variable=VeBPCR_b_HV_BatDschrgPwrLTSgnl_Rcvd_write_IRV
              RV_VeBPCR_b_HV_BatDschrgPwrSTSgnl_Rcvd_write_IRV: accessed-variable=VeBPCR_b_HV_BatDschrgPwrSTSgnl_Rcvd_write_IRV
              RV_VeBPCR_b_HV_BatModTempMaxSgnl_Rcvd_write_IRV: accessed-variable=VeBPCR_b_HV_BatModTempMaxSgnl_Rcvd_write_IRV
              RV_VeBPCR_b_HV_BatModTempMinSgnl_Rcvd_write_IRV: accessed-variable=VeBPCR_b_HV_BatModTempMinSgnl_Rcvd_write_IRV
              RV_VeBPCR_b_HV_BatPackSOCSgnl_Rcvd_write_IRV: accessed-variable=VeBPCR_b_HV_BatPackSOCSgnl_Rcvd_write_IRV
          written-local-variables:
            access WV_VeBPCR_T_BatModTmp_write_IRV: accessed-variable=VeBPCR_T_BatModTmp_write_IRV
        BPCR_PwrOff
          data-send-points:
            11 x access:
              OUT_NeBPCR_T_BatModTmp_NeBPCR_T_BatModTmp: accessed-variable=NeBPCR_T_BatModTmp.NeBPCR_T_BatModTmp
              OUT_DeBPCR_P_HV_BatDschrgPwrST_DeBPCR_P_HV_BatDschrgPwrST: accessed-variable=DeBPCR_P_HV_BatDschrgPwrST.DeBPCR_P_HV_BatDschrgPwrST
              OUT_NeBPCR_b_HV_BatRdy_NeBPCR_b_HV_BatRdy: accessed-variable=NeBPCR_b_HV_BatRdy.NeBPCR_b_HV_BatRdy
              OUT_NeBPCR_b_HV_BatPackSOC_FA_Ovrd_NeBPCR_b_HV_BatPackSOC_FA_Ovrd: accessed-variable=NeBPCR_b_HV_BatPackSOC_FA_Ovrd.NeBPCR_b_HV_BatPackSOC_FA_Ovrd
              OUT_DeBPCR_Pct_HV_BatSOC_DS_DeBPCR_Pct_HV_BatSOC_DS: accessed-variable=DeBPCR_Pct_HV_BatSOC_DS.DeBPCR_Pct_HV_BatSOC_DS
              OUT_DeBPCR_P_HV_BatChrgPwrST_DeBPCR_P_HV_BatChrgPwrST: accessed-variable=DeBPCR_P_HV_BatChrgPwrST.DeBPCR_P_HV_BatChrgPwrST
              OUT_DeBPCR_P_HV_BatChrgPwrET_DeBPCR_P_HV_BatChrgPwrET: accessed-variable=DeBPCR_P_HV_BatChrgPwrET.DeBPCR_P_HV_BatChrgPwrET
              OUT_DeBPCR_P_HV_BatChrgPwrLT_DeBPCR_P_HV_BatChrgPwrLT: accessed-variable=DeBPCR_P_HV_BatChrgPwrLT.DeBPCR_P_HV_BatChrgPwrLT
              OUT_DeBPCR_P_HV_BatDschrgPwrLT_DeBPCR_P_HV_BatDschrgPwrLT: accessed-variable=DeBPCR_P_HV_BatDschrgPwrLT.DeBPCR_P_HV_BatDschrgPwrLT
              OUT_DeBPCR_P_HV_BatDschrgPwrET_DeBPCR_P_HV_BatDschrgPwrET: accessed-variable=DeBPCR_P_HV_BatDschrgPwrET.DeBPCR_P_HV_BatDschrgPwrET
              OUT_NeBPCR_Cnt_PWMCntctrStMFOP_NeBPCR_Cnt_PWMCntctrStMFOP: accessed-variable=NeBPCR_Cnt_PWMCntctrStMFOP.NeBPCR_Cnt_PWMCntctrStMFOP
        FsftBPCR_I_HV_BatCurr
          data-send-points:
            access OUT_VeBPCR_I_HV_BatCurr_Value: accessed-variable=VeBPCR_I_HV_BatCurr.Value
            access OUT_VeBPCR_b_HV_BatCurrFA_Value: accessed-variable=VeBPCR_b_HV_BatCurrFA.Value
          written-local-variables:
            access WV_HV_BatCurrFA_write_IRV: accessed-variable=HV_BatCurrFA_write_IRV
        FsftBPCR_I_MaxChgCurrAlwd
          data-send-points:
            access OUT_VeBPCR_b_MaxChgCurrAlwdFA_Value: accessed-variable=VeBPCR_b_MaxChgCurrAlwdFA.Value
        FsftBPCR_P_TracBat_EChrgPowLong
          data-send-points:
            access OUT_VeBPCR_b_TracBat_EChrgPowLongFA_Value: accessed-variable=VeBPCR_b_TracBat_EChrgPowLongFA.Value
          written-local-variables:
            access WV_TracBat_EChrgPowLongV_write_IRV: accessed-variable=TracBat_EChrgPowLongV_write_IRV
        FsftBPCR_R_HV_BatImped
        FsftBPCR_U_CellVoltHighThrsh
          data-send-points:
            access OUT_VeBPCR_U_CellVoltHighThrsh_Value: accessed-variable=VeBPCR_U_CellVoltHighThrsh.Value
            access OUT_VeBPCR_b_CellVoltHighThrshFA_Value: accessed-variable=VeBPCR_b_CellVoltHighThrshFA.Value
          written-local-variables:
            access WV_CellVoltHighThrsh_write_IRV: accessed-variable=CellVoltHighThrsh_write_IRV
            access WV_CellVoltHighThrshFAInit_write_IRV: accessed-variable=CellVoltHighThrshFAInit_write_IRV
        FsftBPCR_U_CellVoltLowThrsh
          data-send-points:
            access OUT_VeBPCR_U_CellVoltLowThrsh_Value: accessed-variable=VeBPCR_U_CellVoltLowThrsh.Value
            access OUT_VeBPCR_b_CellVoltLowThrshFA_Value: accessed-variable=VeBPCR_b_CellVoltLowThrshFA.Value
          written-local-variables:
            access WV_CellVoltLowThrsh_write_IRV: accessed-variable=CellVoltLowThrsh_write_IRV
            access WV_CellVoltLowThrshFAInit_write_IRV: accessed-variable=CellVoltLowThrshFAInit_write_IRV
        FsftBPCR_U_HV_BatModVoltAvg
          data-send-points:
            access OUT_VeBPCR_U_HV_BatModVoltAvg_Value: accessed-variable=VeBPCR_U_HV_BatModVoltAvg.Value
            access OUT_VeBPCR_b_HV_BatModVoltAvgFA_Value: accessed-variable=VeBPCR_b_HV_BatModVoltAvgFA.Value
        FsftBPCR_U_HV_BatModVoltMax
          data-send-points:
            access OUT_VeBPCR_U_HV_BatModVoltMax_Value: accessed-variable=VeBPCR_U_HV_BatModVoltMax.Value
            access OUT_VeBPCR_b_HV_BatModVoltMaxFA_Value: accessed-variable=VeBPCR_b_HV_BatModVoltMaxFA.Value
          written-local-variables:
            access WV_HV_BatModVoltMax_write_IRV: accessed-variable=HV_BatModVoltMax_write_IRV
            access WV_HV_BatModVoltMaxFA_write_IRV: accessed-variable=HV_BatModVoltMaxFA_write_IRV
        FsftBPCR_U_HV_BatModVoltMin
          data-send-points:
            access OUT_VeBPCR_U_HV_BatModVoltMin_Value: accessed-variable=VeBPCR_U_HV_BatModVoltMin.Value
            access OUT_VeBPCR_b_HV_BatModVoltMinFA_Value: accessed-variable=VeBPCR_b_HV_BatModVoltMinFA.Value
          written-local-variables:
            access WV_HV_BatModVoltMin_write_IRV: accessed-variable=HV_BatModVoltMin_write_IRV
            access WV_HV_BatModVoltMinFA_write_IRV: accessed-variable=HV_BatModVoltMinFA_write_IRV
        FsftBPCR_U_HV_BatVolt
          data-send-points:
            access OUT_VeBPCR_U_HV_BatVolt_Value: accessed-variable=VeBPCR_U_HV_BatVolt.Value
            access OUT_VeBPCR_b_HV_BatVoltFA_Value: accessed-variable=VeBPCR_b_HV_BatVoltFA.Value
        FsftBPCR_U_MaxCellVltAlld
          data-send-points:
            access OUT_VeBPCR_U_MaxCellVltAlld_Value: accessed-variable=VeBPCR_U_MaxCellVltAlld.Value
            access OUT_VeBPCR_b_MaxCellVltAlld_FA_Value: accessed-variable=VeBPCR_b_MaxCellVltAlld_FA.Value
        FsftBPCR_U_MaxPkVltAlld
          data-send-points:
            access OUT_VeBPCR_U_MaxPkVltAlld_Value: accessed-variable=VeBPCR_U_MaxPkVltAlld.Value
            access OUT_VeBPCR_b_MaxPkVltAlld_FA_Value: accessed-variable=VeBPCR_b_MaxPkVltAlld_FA.Value
        FsftBPCR_U_MinCellVltAlld
          data-send-points:
            access OUT_VeBPCR_U_MinCellVltAlld_Value: accessed-variable=VeBPCR_U_MinCellVltAlld.Value
            access OUT_VeBPCR_b_MinCellVltAlld_FA_Value: accessed-variable=VeBPCR_b_MinCellVltAlld_FA.Value
        FsftBPCR_U_MinPkVltAlld
          data-send-points:
            access OUT_VeBPCR_U_MinPkVltAlld_Value: accessed-variable=VeBPCR_U_MinPkVltAlld.Value
            access OUT_VeBPCR_b_MinPkVltAlld_FA_Value: accessed-variable=VeBPCR_b_MinPkVltAlld_FA.Value
        FsftBPCR_U_OCVAveCellVoltage
          data-send-points:
            access OUT_VeBPCR_b_OCVAvgCellVoltage_FA_Value: accessed-variable=VeBPCR_b_OCVAvgCellVoltage_FA.Value
        FsftBPCR_U_OCVMaxCellVoltage
          data-send-points:
            access OUT_VeBPCR_b_OCVMaxCellVoltage_FA_Value: accessed-variable=VeBPCR_b_OCVMaxCellVoltage_FA.Value
        FsftBPCR_U_OCVMinCellVoltage
          data-send-points:
            access OUT_VeBPCR_b_OCVMinCellVoltage_FA_Value: accessed-variable=VeBPCR_b_OCVMinCellVoltage_FA.Value
        FsftBPCR_Z_MaxCellDischargeImpedance
          data-send-points:
            access OUT_VeBPCR_b_MaxCellDschargeImpedance_FA_Value: accessed-variable=VeBPCR_b_MaxCellDschargeImpedance_FA.Value
        FsftBPCR_Z_MinCellDischargeImpedance
          data-send-points:
            access OUT_VeBPCR_b_MinCellDschargeImpedance_FA_Value: accessed-variable=VeBPCR_b_MinCellDschargeImpedance_FA.Value
        FsftBPCR_b_BPCM_LIN_BusOff
          data-send-points:
            access OUT_VeBPCR_b_BPCM_LIN_BusOff_FA_Value: accessed-variable=VeBPCR_b_BPCM_LIN_BusOff_FA.Value
            access OUT_VeBPCR_b_BPCM_LIN_BusOff_SgnlRcvd_Value: accessed-variable=VeBPCR_b_BPCM_LIN_BusOff_SgnlRcvd.Value
        FsftBPCR_b_BPCM_LOC_BCP
          data-send-points:
            access OUT_VeBPCR_b_BPCM_LOC_BCP_FA_Value: accessed-variable=VeBPCR_b_BPCM_LOC_BCP_FA.Value
            access OUT_VeBPCR_b_BPCM_LOC_BCP_SgnlRcvd_Value: accessed-variable=VeBPCR_b_BPCM_LOC_BCP_SgnlRcvd.Value
        FsftBPCR_b_BPCM_LOC_BatClntHtr
          data-send-points:
            access OUT_VeBPCR_b_BPCM_LOC_BatClntHtr_FA_Value: accessed-variable=VeBPCR_b_BPCM_LOC_BatClntHtr_FA.Value
            access OUT_VeBPCR_b_BPCM_LOC_BatClntHtr_SgnlRcvd_Value: accessed-variable=VeBPCR_b_BPCM_LOC_BatClntHtr_SgnlRcvd.Value
        FsftBPCR_b_HVBatCntrWeld_ImpdOpn
          data-send-points:
            access OUT_VeBPCR_b_Flst_HVBatCntrWeld_ImpdOpn_Value: accessed-variable=VeBPCR_b_Flst_HVBatCntrWeld_ImpdOpn.Value
          written-local-variables:
            access WV_VeBPCR_b_HVBatCntrWeld_ImpdOpnSgnl_Rcvd_write_IRV: accessed-variable=VeBPCR_b_HVBatCntrWeld_ImpdOpnSgnl_Rcvd_write_IRV
        FsftBPCR_b_HVBatRdy
          data-send-points:
            access OUT_VeBPCR_e_HVBatRdy_Value: accessed-variable=VeBPCR_e_HVBatRdy.Value
          written-local-variables:
            access WV_HV_BatRdySgnl_Rcvd_write_IRV: accessed-variable=HV_BatRdySgnl_Rcvd_write_IRV
        FsftBPCR_b_HVBat_DC_CntctrStat
          data-send-points:
            access OUT_VeBPCR_b_HVBat_DC_CntctrStat_FA_Value: accessed-variable=VeBPCR_b_HVBat_DC_CntctrStat_FA.Value
        FsftBPCR_b_HV_AuxLoadOffReq
          data-send-points:
            access OUT_VeBPCR_b_HV_AuxLoadOffReqFA_Value: accessed-variable=VeBPCR_b_HV_AuxLoadOffReqFA.Value
        FsftBPCR_b_HV_BatChrgPwrET
          data-send-points:
            access OUT_VeBPCR_b_HV_BatChrgPwrET_FA_Value: accessed-variable=VeBPCR_b_HV_BatChrgPwrET_FA.Value
            access OUT_VeBPCR_b_HV_BatChrgPwrETSgnl_Rcvd_Value: accessed-variable=VeBPCR_b_HV_BatChrgPwrETSgnl_Rcvd.Value
          written-local-variables:
            access WV_HVBatChrgPowET_FA_Init_write_IRV: accessed-variable=HVBatChrgPowET_FA_Init_write_IRV
            access WV_VeBPCR_b_HV_BatChrgPwrETSgnl_Rcvd_write_IRV: accessed-variable=VeBPCR_b_HV_BatChrgPwrETSgnl_Rcvd_write_IRV
        FsftBPCR_b_HV_BatChrgPwrLT
          data-send-points:
            access OUT_VeBPCR_b_HV_BatChrgPwrLT_FA_Value: accessed-variable=VeBPCR_b_HV_BatChrgPwrLT_FA.Value
            access OUT_VeBPCR_b_HV_BatChrgPwrLTSgnl_Rcvd_Value: accessed-variable=VeBPCR_b_HV_BatChrgPwrLTSgnl_Rcvd.Value
          written-local-variables:
            access WV_HVBatChrgPowLT_FA_Init_write_IRV: accessed-variable=HVBatChrgPowLT_FA_Init_write_IRV
            access WV_VeBPCR_b_HV_BatChrgPwrLTSgnl_Rcvd_write_IRV: accessed-variable=VeBPCR_b_HV_BatChrgPwrLTSgnl_Rcvd_write_IRV
        FsftBPCR_b_HV_BatChrgPwrST
          data-send-points:
            access OUT_VeBPCR_b_HV_BatChrgPwrST_FA_Value: accessed-variable=VeBPCR_b_HV_BatChrgPwrST_FA.Value
            access OUT_VeBPCR_b_HV_BatChrgPwrSTSgnl_Rcvd_Value: accessed-variable=VeBPCR_b_HV_BatChrgPwrSTSgnl_Rcvd.Value
          written-local-variables:
            access WV_HVBatChrgPowST_FA_Init_write_IRV: accessed-variable=HVBatChrgPowST_FA_Init_write_IRV
            access WV_VeBPCR_b_HV_BatChrgPwrSTSgnl_Rcvd_write_IRV: accessed-variable=VeBPCR_b_HV_BatChrgPwrSTSgnl_Rcvd_write_IRV
        FsftBPCR_b_HV_BatCurrString2
          data-send-points:
            access OUT_VeBPCR_b_HV_Current_String2_FA_Value: accessed-variable=VeBPCR_b_HV_Current_String2_FA.Value
        FsftBPCR_b_HV_BatDschrgPwrET
          data-send-points:
            access OUT_VeBPCR_b_HV_BatDschrgPwrET_FA_Value: accessed-variable=VeBPCR_b_HV_BatDschrgPwrET_FA.Value
            access OUT_VeBPCR_b_HV_BatDschrgPwrETSgnl_Rcvd_Value: accessed-variable=VeBPCR_b_HV_BatDschrgPwrETSgnl_Rcvd.Value
          written-local-variables:
            access WV_HVBatDschrgPowET_FA_Init_write_IRV: accessed-variable=HVBatDschrgPowET_FA_Init_write_IRV
            access WV_VeBPCR_b_HV_BatDschrgPwrETSgnl_Rcvd_write_IRV: accessed-variable=VeBPCR_b_HV_BatDschrgPwrETSgnl_Rcvd_write_IRV
        FsftBPCR_b_HV_BatDschrgPwrLT
          data-send-points:
            access OUT_VeBPCR_b_HV_BatDschrgPwrLT_FA_Value: accessed-variable=VeBPCR_b_HV_BatDschrgPwrLT_FA.Value
            access OUT_VeBPCR_b_HV_BatDschrgPwrLTSgnl_Rcvd_Value: accessed-variable=VeBPCR_b_HV_BatDschrgPwrLTSgnl_Rcvd.Value
          written-local-variables:
            access WV_HVBatDschrgPowLT_FA_Init_write_IRV: accessed-variable=HVBatDschrgPowLT_FA_Init_write_IRV
            access WV_VeBPCR_b_HV_BatDschrgPwrLTSgnl_Rcvd_write_IRV: accessed-variable=VeBPCR_b_HV_BatDschrgPwrLTSgnl_Rcvd_write_IRV
        FsftBPCR_b_HV_BatDschrgPwrST
          data-send-points:
            access OUT_VeBPCR_b_HV_BatDschrgPwrST_FA_Value: accessed-variable=VeBPCR_b_HV_BatDschrgPwrST_FA.Value
            access OUT_VeBPCR_b_HV_BatDschrgPwrSTSgnl_Rcvd_Value: accessed-variable=VeBPCR_b_HV_BatDschrgPwrSTSgnl_Rcvd.Value
          written-local-variables:
            access WV_HVBatDschrgPowST_FA_Init_write_IRV: accessed-variable=HVBatDschrgPowST_FA_Init_write_IRV
            access WV_VeBPCR_b_HV_BatDschrgPwrSTSgnl_Rcvd_write_IRV: accessed-variable=VeBPCR_b_HV_BatDschrgPwrSTSgnl_Rcvd_write_IRV
        FsftBPCR_b_HV_BatModTempAvg
          data-send-points:
            access OUT_VeBPCR_b_HV_BatModTempAvgFA_Value: accessed-variable=VeBPCR_b_HV_BatModTempAvgFA.Value
          written-local-variables:
            access WV_HV_BatModTempAvgFA_write_IRV: accessed-variable=HV_BatModTempAvgFA_write_IRV
            access WV_VeBPCR_b_HV_BatModTempAvgSgnl_Rcvd_write_IRV: accessed-variable=VeBPCR_b_HV_BatModTempAvgSgnl_Rcvd_write_IRV
        FsftBPCR_b_HV_BatModTempMax
          data-send-points:
            access OUT_VeBPCR_b_HV_BatModTempMaxFA_Value: accessed-variable=VeBPCR_b_HV_BatModTempMaxFA.Value
          written-local-variables:
            access WV_HV_BatModTempMaxFA_write_IRV: accessed-variable=HV_BatModTempMaxFA_write_IRV
            access WV_VeBPCR_b_HV_BatModTempMaxSgnl_Rcvd_write_IRV: accessed-variable=VeBPCR_b_HV_BatModTempMaxSgnl_Rcvd_write_IRV
        FsftBPCR_b_HV_BatModTempMin
          data-send-points:
            access OUT_VeBPCR_b_HV_BatModTempMinFA_Value: accessed-variable=VeBPCR_b_HV_BatModTempMinFA.Value
          written-local-variables:
            access WV_HV_BatModTempMinFA_write_IRV: accessed-variable=HV_BatModTempMinFA_write_IRV
            access WV_VeBPCR_b_HV_BatModTempMinSgnl_Rcvd_write_IRV: accessed-variable=VeBPCR_b_HV_BatModTempMinSgnl_Rcvd_write_IRV
        FsftBPCR_b_HV_BatPackSOC
          data-send-points:
            access OUT_VeBPCR_b_HV_BatPackSOC_FA_Value: accessed-variable=VeBPCR_b_HV_BatPackSOC_FA.Value
            access OUT_VeBPCR_b_HV_BatPackSOC_SgnlRcvd_Value: accessed-variable=VeBPCR_b_HV_BatPackSOC_SgnlRcvd.Value
          written-local-variables:
            access WV_HVBatPackSOC_FA_Init_write_IRV: accessed-variable=HVBatPackSOC_FA_Init_write_IRV
            access WV_VeBPCR_b_HV_BatPackSOCSgnl_Rcvd_write_IRV: accessed-variable=VeBPCR_b_HV_BatPackSOCSgnl_Rcvd_write_IRV
        FsftBPCR_b_HV_DcChargeTypeStat
          data-send-points:
            access OUT_VeBPCR_b_HVDcChargeTypeStatFA_Value: accessed-variable=VeBPCR_b_HVDcChargeTypeStatFA.Value
        FsftBPCR_b_HV_InternalStringVolt1
          data-send-points:
            access OUT_VeBPCR_b_HV_InternalStringVolt1FA_Value: accessed-variable=VeBPCR_b_HV_InternalStringVolt1FA.Value
        FsftBPCR_b_HV_InternalStringVolt2
          data-send-points:
            access OUT_VeBPCR_b_HV_InternalStringVolt2FA_Value: accessed-variable=VeBPCR_b_HV_InternalStringVolt2FA.Value
        FsftBPCR_b_HV_InternalVolt
          data-send-points:
            access OUT_VeBPCR_b_BPCM_HV_InternalVoltage_FA_Value: accessed-variable=VeBPCR_b_BPCM_HV_InternalVoltage_FA.Value
        FsftBPCR_b_HV_SeriesVolt
          data-send-points:
            access OUT_VeBPCR_b_HV_SeriesVoltFA_Value: accessed-variable=VeBPCR_b_HV_SeriesVoltFA.Value
        FsftBPCR_b_HV_TracBatCntctrConfig
          data-send-points:
            access OUT_VeBPCR_b_HVTracBatCntctrConfigFA_Value: accessed-variable=VeBPCR_b_HVTracBatCntctrConfigFA.Value
        FsftBPCR_b_ThrmlRnawy_Warn
          written-local-variables:
            access WV_HVBat_ThrmlRnawy_WarnFA_Init_write_IRV: accessed-variable=HVBat_ThrmlRnawy_WarnFA_Init_write_IRV
        FsftBPCR_cnt_HVBatt_ModNumMaxTmp
          data-send-points:
            access OUT_VeBPCR_Cnt_HVBat_ModNumMaxTmp_Value: accessed-variable=VeBPCR_Cnt_HVBat_ModNumMaxTmp.Value
        FsftBPCR_cnt_HVBatt_ModNumMinTmp
          data-send-points:
            access OUT_VeBPCR_Cnt_HVBat_ModNumMinTmp_Value: accessed-variable=VeBPCR_Cnt_HVBat_ModNumMinTmp.Value
        FsftBPCR_e_BPCM_Comm_Fail
          data-send-points:
            access OUT_VeBPCR_b_BPCM_CommFailFA_Value: accessed-variable=VeBPCR_b_BPCM_CommFailFA.Value
        FsftBPCR_e_ChargingStat_BPCM
          data-send-points:
            access OUT_VeBPCR_b_ChargingStat_BPCMFA_Value: accessed-variable=VeBPCR_b_ChargingStat_BPCMFA.Value
        FsftBPCR_e_DCIsolSts
          data-send-points:
            access OUT_VeBPCR_b_DCIsolStsFA_Value: accessed-variable=VeBPCR_b_DCIsolStsFA.Value
        FsftBPCR_e_HVBatIntrlkIntrnlStat
          data-send-points:
            access OUT_VeBPCR_b_HVBatIntrlkIntrnlStatFA_Value: accessed-variable=VeBPCR_b_HVBatIntrlkIntrnlStatFA.Value
        FsftBPCR_e_HV_BatCntctrStat
          written-local-variables:
            access WV_HV_BatCntctrStatFA_write_IRV: accessed-variable=HV_BatCntctrStatFA_write_IRV
        FsftBPCR_e_HV_BatInrlkStat
          data-send-points:
            access OUT_VeBPCR_b_HV_BatInrlkStatFA_Value: accessed-variable=VeBPCR_b_HV_BatInrlkStatFA.Value
        FsftBPCR_e_HV_BatIsolStat
          data-send-points:
            access OUT_VeBPCR_e_HV_BatIsolStat_Value: accessed-variable=VeBPCR_e_HV_BatIsolStat.Value
            access OUT_VeBPCR_e_HV_BatIsolStat_raw_Value: accessed-variable=VeBPCR_e_HV_BatIsolStat_raw.Value
        FsftBPCR_q_FullAmpHrCap
          data-send-points:
            access OUT_VeBPCR_q_FullAmpHrCap_Value: accessed-variable=VeBPCR_q_FullAmpHrCap.Value
        FsftBPCR_q_RemainingAmpHrCap
          data-send-points:
            access OUT_VeBPCR_b_RemainingAmpHrCapFA_Value: accessed-variable=VeBPCR_b_RemainingAmpHrCapFA.Value
        FsftBPCR_t_HVBatRealTimeClock
          data-send-points:
            access OUT_VeBPCR_b_HVBatRealTimeClock_FA_Value: accessed-variable=VeBPCR_b_HVBatRealTimeClock_FA.Value
        FsftBPCR_t_HVBattCntctrOpnTm
          data-send-points:
            access OUT_VeBPCR_t_HVBattCntctrOpnTm_Value: accessed-variable=VeBPCR_t_HVBattCntctrOpnTm.Value
        PokeBPCR_Cnt_HVBatt_NumMaxVlt
          data-send-points:
            access OUT_VeBPCR_Cnt_HVBat_NumMaxVlt_Value: accessed-variable=VeBPCR_Cnt_HVBat_NumMaxVlt.Value
        PokeBPCR_Cnt_HVBatt_NumMinVlt
          data-send-points:
            access OUT_VeBPCR_Cnt_HVBat_NumMinVlt_Value: accessed-variable=VeBPCR_Cnt_HVBat_NumMinVlt.Value
        PokeBPCR_DC_CntctrCntrl_PWM
          data-send-points:
            access OUT_VeBPCR_b_CntctrCntrl_PWM_FA_Value: accessed-variable=VeBPCR_b_CntctrCntrl_PWM_FA.Value
        PokeBPCR_I_HV_BatCurr
          data-send-points:
            access OUT_VeBPCR_I_HV_BatCurr_Value: accessed-variable=VeBPCR_I_HV_BatCurr.Value
            access OUT_VeBPCR_b_HV_BatCurrFA_Value: accessed-variable=VeBPCR_b_HV_BatCurrFA.Value
          written-local-variables:
            access WV_HV_BatCurrFA_write_IRV: accessed-variable=HV_BatCurrFA_write_IRV
        PokeBPCR_I_HV_BatCurrString2
          data-send-points:
            access OUT_VeBPCR_I_HV_Current_String2_Value: accessed-variable=VeBPCR_I_HV_Current_String2.Value
            access OUT_VeBPCR_b_HV_Current_String2_FA_Value: accessed-variable=VeBPCR_b_HV_Current_String2_FA.Value
        PokeBPCR_I_MaxChgCurrAlwd
          data-send-points:
            access OUT_VeBPCR_I_MaxChrgCurrAlwd_Value: accessed-variable=VeBPCR_I_MaxChrgCurrAlwd.Value
            access OUT_VeBPCR_b_MaxChgCurrAlwdFA_Value: accessed-variable=VeBPCR_b_MaxChgCurrAlwdFA.Value
        PokeBPCR_I_MaxDisChgCurrAlwd
        PokeBPCR_P_HV_BatChrgPwrET
          data-send-points:
            access OUT_VeBPCR_P_HV_BatChrgPwrET_Value: accessed-variable=VeBPCR_P_HV_BatChrgPwrET.Value
            access OUT_VeBPCR_b_HV_BatChrgPwrET_FA_Value: accessed-variable=VeBPCR_b_HV_BatChrgPwrET_FA.Value
            access OUT_VeBPCR_b_HV_BatChrgPwrETSgnl_Rcvd_Value: accessed-variable=VeBPCR_b_HV_BatChrgPwrETSgnl_Rcvd.Value
          written-local-variables:
            access WV_HVBatChrgPowET_Init_write_IRV: accessed-variable=HVBatChrgPowET_Init_write_IRV
            access WV_HVBatChrgPowET_FA_Init_write_IRV: accessed-variable=HVBatChrgPowET_FA_Init_write_IRV
            access WV_VeBPCR_b_HV_BatChrgPwrETSgnl_Rcvd_write_IRV: accessed-variable=VeBPCR_b_HV_BatChrgPwrETSgnl_Rcvd_write_IRV
        PokeBPCR_P_HV_BatChrgPwrLT
          data-send-points:
            access OUT_VeBPCR_P_HV_BatChrgPwrLT_Value: accessed-variable=VeBPCR_P_HV_BatChrgPwrLT.Value
            access OUT_VeBPCR_b_HV_BatChrgPwrLT_FA_Value: accessed-variable=VeBPCR_b_HV_BatChrgPwrLT_FA.Value
            access OUT_VeBPCR_b_HV_BatChrgPwrLTSgnl_Rcvd_Value: accessed-variable=VeBPCR_b_HV_BatChrgPwrLTSgnl_Rcvd.Value
          written-local-variables:
            access WV_HVBatChrgPowLT_Init_write_IRV: accessed-variable=HVBatChrgPowLT_Init_write_IRV
            access WV_HVBatChrgPowLT_FA_Init_write_IRV: accessed-variable=HVBatChrgPowLT_FA_Init_write_IRV
            access WV_VeBPCR_b_HV_BatChrgPwrLTSgnl_Rcvd_write_IRV: accessed-variable=VeBPCR_b_HV_BatChrgPwrLTSgnl_Rcvd_write_IRV
        PokeBPCR_P_HV_BatChrgPwrST
          data-send-points:
            access OUT_VeBPCR_P_HV_BatChrgPwrST_Value: accessed-variable=VeBPCR_P_HV_BatChrgPwrST.Value
            access OUT_VeBPCR_b_HV_BatChrgPwrST_FA_Value: accessed-variable=VeBPCR_b_HV_BatChrgPwrST_FA.Value
            access OUT_VeBPCR_b_HV_BatChrgPwrSTSgnl_Rcvd_Value: accessed-variable=VeBPCR_b_HV_BatChrgPwrSTSgnl_Rcvd.Value
          written-local-variables:
            access WV_HVBatChrgPowST_Init_write_IRV: accessed-variable=HVBatChrgPowST_Init_write_IRV
            access WV_HVBatChrgPowST_FA_Init_write_IRV: accessed-variable=HVBatChrgPowST_FA_Init_write_IRV
            access WV_VeBPCR_b_HV_BatChrgPwrSTSgnl_Rcvd_write_IRV: accessed-variable=VeBPCR_b_HV_BatChrgPwrSTSgnl_Rcvd_write_IRV
        PokeBPCR_P_HV_BatDschrgPwrET
          data-send-points:
            access OUT_VeBPCR_P_HV_BatDschrgPwrET_Value: accessed-variable=VeBPCR_P_HV_BatDschrgPwrET.Value
            access OUT_VeBPCR_b_HV_BatDschrgPwrET_FA_Value: accessed-variable=VeBPCR_b_HV_BatDschrgPwrET_FA.Value
            access OUT_VeBPCR_b_HV_BatDschrgPwrETSgnl_Rcvd_Value: accessed-variable=VeBPCR_b_HV_BatDschrgPwrETSgnl_Rcvd.Value
          written-local-variables:
            access WV_HVBatDschrgPowET_Init_write_IRV: accessed-variable=HVBatDschrgPowET_Init_write_IRV
            access WV_HVBatDschrgPowET_FA_Init_write_IRV: accessed-variable=HVBatDschrgPowET_FA_Init_write_IRV
            access WV_VeBPCR_b_HV_BatDschrgPwrETSgnl_Rcvd_write_IRV: accessed-variable=VeBPCR_b_HV_BatDschrgPwrETSgnl_Rcvd_write_IRV
        PokeBPCR_P_HV_BatDschrgPwrLT
          data-send-points:
            access OUT_VeBPCR_P_HV_BatDschrgPwrLT_Value: accessed-variable=VeBPCR_P_HV_BatDschrgPwrLT.Value
            access OUT_VeBPCR_b_HV_BatDschrgPwrLT_FA_Value: accessed-variable=VeBPCR_b_HV_BatDschrgPwrLT_FA.Value
            access OUT_VeBPCR_b_HV_BatDschrgPwrLTSgnl_Rcvd_Value: accessed-variable=VeBPCR_b_HV_BatDschrgPwrLTSgnl_Rcvd.Value
          written-local-variables:
            access WV_HVBatDschrgPowLT_Init_write_IRV: accessed-variable=HVBatDschrgPowLT_Init_write_IRV
            access WV_HVBatDschrgPowLT_FA_Init_write_IRV: accessed-variable=HVBatDschrgPowLT_FA_Init_write_IRV
            access WV_VeBPCR_b_HV_BatDschrgPwrLTSgnl_Rcvd_write_IRV: accessed-variable=VeBPCR_b_HV_BatDschrgPwrLTSgnl_Rcvd_write_IRV
        PokeBPCR_P_HV_BatDschrgPwrST
          data-send-points:
            access OUT_VeBPCR_P_HV_BatDschrgPwrST_Value: accessed-variable=VeBPCR_P_HV_BatDschrgPwrST.Value
            access OUT_VeBPCR_b_HV_BatDschrgPwrST_FA_Value: accessed-variable=VeBPCR_b_HV_BatDschrgPwrST_FA.Value
            access OUT_VeBPCR_b_HV_BatDschrgPwrSTSgnl_Rcvd_Value: accessed-variable=VeBPCR_b_HV_BatDschrgPwrSTSgnl_Rcvd.Value
          written-local-variables:
            access WV_HVBatDschrgPowST_Init_write_IRV: accessed-variable=HVBatDschrgPowST_Init_write_IRV
            access WV_HVBatDschrgPowST_FA_Init_write_IRV: accessed-variable=HVBatDschrgPowST_FA_Init_write_IRV
            access WV_VeBPCR_b_HV_BatDschrgPwrSTSgnl_Rcvd_write_IRV: accessed-variable=VeBPCR_b_HV_BatDschrgPwrSTSgnl_Rcvd_write_IRV
        PokeBPCR_P_TracBat_EChrgPowLong
          data-send-points:
            access OUT_VeBPCR_P_TracBat_EChrgPowLong_Value: accessed-variable=VeBPCR_P_TracBat_EChrgPowLong.Value
            access OUT_VeBPCR_b_TracBat_EChrgPowLongFA_Value: accessed-variable=VeBPCR_b_TracBat_EChrgPowLongFA.Value
          written-local-variables:
            access WV_TracBat_EChrgPowLong_write_IRV: accessed-variable=TracBat_EChrgPowLong_write_IRV
            access WV_TracBat_EChrgPowLongV_write_IRV: accessed-variable=TracBat_EChrgPowLongV_write_IRV
        PokeBPCR_Pct_ContctCntrlVerif
        PokeBPCR_Pct_HVBatSOH
          data-send-points:
            access OUT_VeBPCR_Pct_HVBatSOH_Value: accessed-variable=VeBPCR_Pct_HVBatSOH.Value
        PokeBPCR_Pct_HVBatSOHLow
          data-send-points:
            access OUT_VeBPCR_Pct_HVBatSOHLow_Value: accessed-variable=VeBPCR_Pct_HVBatSOHLow.Value
        PokeBPCR_Pct_HV_BatPackSOC
          data-send-points:
            access OUT_VeBPCR_Pct_HV_BatPackSOC_Value: accessed-variable=VeBPCR_Pct_HV_BatPackSOC.Value
            access OUT_VeBPCR_b_HV_BatPackSOC_FA_Value: accessed-variable=VeBPCR_b_HV_BatPackSOC_FA.Value
            access OUT_VeBPCR_b_HV_BatPackSOC_SgnlRcvd_Value: accessed-variable=VeBPCR_b_HV_BatPackSOC_SgnlRcvd.Value
          written-local-variables:
            access WV_HVBatPackSOC_Init_write_IRV: accessed-variable=HVBatPackSOC_Init_write_IRV
            access WV_HVBatPackSOC_FA_Init_write_IRV: accessed-variable=HVBatPackSOC_FA_Init_write_IRV
            access WV_VeBPCR_b_HV_BatPackSOCSgnl_Rcvd_write_IRV: accessed-variable=VeBPCR_b_HV_BatPackSOCSgnl_Rcvd_write_IRV
        PokeBPCR_R_HV_BatImped
        PokeBPCR_T_BDUBusBarTemp
          data-send-points:
            access OUT_VeBPCR_T_BDUBusBarTemp_Value: accessed-variable=VeBPCR_T_BDUBusBarTemp.Value
        PokeBPCR_T_BusBarTemp
          data-send-points:
            access OUT_VeBPCR_T_BusBarTemp_Value: accessed-variable=VeBPCR_T_BusBarTemp.Value
        PokeBPCR_T_HVBatClgOutletTemp
          data-send-points:
            access OUT_VeBPCR_T_HVBatClgOutletTemp_Value: accessed-variable=VeBPCR_T_HVBatClgOutletTemp.Value
            access OUT_VeBPCR_b_HVBatClgOutletTempFA_Value: accessed-variable=VeBPCR_b_HVBatClgOutletTempFA.Value
        PokeBPCR_T_HV_BatModTempAvg
          data-send-points:
            access OUT_VeBPCR_b_HV_BatModTempAvgFA_Value: accessed-variable=VeBPCR_b_HV_BatModTempAvgFA.Value
          written-local-variables:
            access WV_HV_BatModTempAvg_write_IRV: accessed-variable=HV_BatModTempAvg_write_IRV
            access WV_HV_BatModTempAvgFA_write_IRV: accessed-variable=HV_BatModTempAvgFA_write_IRV
            access WV_VeBPCR_b_HV_BatModTempAvgSgnl_Rcvd_write_IRV: accessed-variable=VeBPCR_b_HV_BatModTempAvgSgnl_Rcvd_write_IRV
        PokeBPCR_T_HV_BatModTempMax
          data-send-points:
            access OUT_VeBPCR_b_HV_BatModTempMaxFA_Value: accessed-variable=VeBPCR_b_HV_BatModTempMaxFA.Value
          written-local-variables:
            access WV_HV_BatModTempMax_write_IRV: accessed-variable=HV_BatModTempMax_write_IRV
            access WV_HV_BatModTempMaxFA_write_IRV: accessed-variable=HV_BatModTempMaxFA_write_IRV
            access WV_VeBPCR_b_HV_BatModTempMaxSgnl_Rcvd_write_IRV: accessed-variable=VeBPCR_b_HV_BatModTempMaxSgnl_Rcvd_write_IRV
        PokeBPCR_T_HV_BatModTempMin
          data-send-points:
            access OUT_VeBPCR_b_HV_BatModTempMinFA_Value: accessed-variable=VeBPCR_b_HV_BatModTempMinFA.Value
          written-local-variables:
            access WV_HV_BatModTempMin_write_IRV: accessed-variable=HV_BatModTempMin_write_IRV
            access WV_HV_BatModTempMinFA_write_IRV: accessed-variable=HV_BatModTempMinFA_write_IRV
            access WV_VeBPCR_b_HV_BatModTempMinSgnl_Rcvd_write_IRV: accessed-variable=VeBPCR_b_HV_BatModTempMinSgnl_Rcvd_write_IRV
        PokeBPCR_U_CellVoltHighThrsh
          data-send-points:
            access OUT_VeBPCR_U_CellVoltHighThrsh_Value: accessed-variable=VeBPCR_U_CellVoltHighThrsh.Value
            access OUT_VeBPCR_b_CellVoltHighThrshFA_Value: accessed-variable=VeBPCR_b_CellVoltHighThrshFA.Value
          written-local-variables:
            access WV_CellVoltHighThrsh_write_IRV: accessed-variable=CellVoltHighThrsh_write_IRV
            access WV_CellVoltHighThrshFAInit_write_IRV: accessed-variable=CellVoltHighThrshFAInit_write_IRV
        PokeBPCR_U_CellVoltLowThrsh
          data-send-points:
            access OUT_VeBPCR_U_CellVoltLowThrsh_Value: accessed-variable=VeBPCR_U_CellVoltLowThrsh.Value
            access OUT_VeBPCR_b_CellVoltLowThrshFA_Value: accessed-variable=VeBPCR_b_CellVoltLowThrshFA.Value
          written-local-variables:
            access WV_CellVoltLowThrsh_write_IRV: accessed-variable=CellVoltLowThrsh_write_IRV
            access WV_CellVoltLowThrshFAInit_write_IRV: accessed-variable=CellVoltLowThrshFAInit_write_IRV
        PokeBPCR_U_HV_BatModVoltAvg
          data-send-points:
            access OUT_VeBPCR_U_HV_BatModVoltAvg_Value: accessed-variable=VeBPCR_U_HV_BatModVoltAvg.Value
            access OUT_VeBPCR_b_HV_BatModVoltAvgFA_Value: accessed-variable=VeBPCR_b_HV_BatModVoltAvgFA.Value
        PokeBPCR_U_HV_BatModVoltMax
          data-send-points:
            access OUT_VeBPCR_U_HV_BatModVoltMax_Value: accessed-variable=VeBPCR_U_HV_BatModVoltMax.Value
            access OUT_VeBPCR_b_HV_BatModVoltMaxFA_Value: accessed-variable=VeBPCR_b_HV_BatModVoltMaxFA.Value
          written-local-variables:
            access WV_HV_BatModVoltMax_write_IRV: accessed-variable=HV_BatModVoltMax_write_IRV
            access WV_HV_BatModVoltMaxFA_write_IRV: accessed-variable=HV_BatModVoltMaxFA_write_IRV
        PokeBPCR_U_HV_BatModVoltMin
          data-send-points:
            access OUT_VeBPCR_U_HV_BatModVoltMin_Value: accessed-variable=VeBPCR_U_HV_BatModVoltMin.Value
            access OUT_VeBPCR_b_HV_BatModVoltMinFA_Value: accessed-variable=VeBPCR_b_HV_BatModVoltMinFA.Value
          written-local-variables:
            access WV_HV_BatModVoltMin_write_IRV: accessed-variable=HV_BatModVoltMin_write_IRV
            access WV_HV_BatModVoltMinFA_write_IRV: accessed-variable=HV_BatModVoltMinFA_write_IRV
        PokeBPCR_U_HV_BatVolt
          data-send-points:
            access OUT_VeBPCR_U_HV_BatVolt_Value: accessed-variable=VeBPCR_U_HV_BatVolt.Value
            access OUT_VeBPCR_b_HV_BatVoltFA_Value: accessed-variable=VeBPCR_b_HV_BatVoltFA.Value
        PokeBPCR_U_HV_InternalStringVolt1
          data-send-points:
            access OUT_VeBPCR_U_HV_InternalStringVolt1_Value: accessed-variable=VeBPCR_U_HV_InternalStringVolt1.Value
            access OUT_VeBPCR_b_HV_InternalStringVolt1FA_Value: accessed-variable=VeBPCR_b_HV_InternalStringVolt1FA.Value
        PokeBPCR_U_HV_InternalStringVolt2
          data-send-points:
            access OUT_VeBPCR_U_HV_InternalStringVolt2_Value: accessed-variable=VeBPCR_U_HV_InternalStringVolt2.Value
            access OUT_VeBPCR_b_HV_InternalStringVolt2FA_Value: accessed-variable=VeBPCR_b_HV_InternalStringVolt2FA.Value
        PokeBPCR_U_HV_InternalVolt
          data-send-points:
            access OUT_VeBPCR_U_BPCM_HV_InternalVoltage_Value: accessed-variable=VeBPCR_U_BPCM_HV_InternalVoltage.Value
            access OUT_VeBPCR_b_BPCM_HV_InternalVoltage_FA_Value: accessed-variable=VeBPCR_b_BPCM_HV_InternalVoltage_FA.Value
        PokeBPCR_U_HV_SeriesVolt
          data-send-points:
            access OUT_VeBPCR_U_HV_SeriesVolt_Value: accessed-variable=VeBPCR_U_HV_SeriesVolt.Value
            access OUT_VeBPCR_b_HV_SeriesVoltFA_Value: accessed-variable=VeBPCR_b_HV_SeriesVoltFA.Value
        PokeBPCR_U_MaxCellVltAlld
          data-send-points:
            access OUT_VeBPCR_U_MaxCellVltAlld_Value: accessed-variable=VeBPCR_U_MaxCellVltAlld.Value
            access OUT_VeBPCR_b_MaxCellVltAlld_FA_Value: accessed-variable=VeBPCR_b_MaxCellVltAlld_FA.Value
        PokeBPCR_U_MaxPkVltAlld
          data-send-points:
            access OUT_VeBPCR_U_MaxPkVltAlld_Value: accessed-variable=VeBPCR_U_MaxPkVltAlld.Value
            access OUT_VeBPCR_b_MaxPkVltAlld_FA_Value: accessed-variable=VeBPCR_b_MaxPkVltAlld_FA.Value
        PokeBPCR_U_MinCellVltAlld
          data-send-points:
            access OUT_VeBPCR_U_MinCellVltAlld_Value: accessed-variable=VeBPCR_U_MinCellVltAlld.Value
            access OUT_VeBPCR_b_MinCellVltAlld_FA_Value: accessed-variable=VeBPCR_b_MinCellVltAlld_FA.Value
        PokeBPCR_U_MinPkVltAlld
          data-send-points:
            access OUT_VeBPCR_U_MinPkVltAlld_Value: accessed-variable=VeBPCR_U_MinPkVltAlld.Value
            access OUT_VeBPCR_b_MinPkVltAlld_FA_Value: accessed-variable=VeBPCR_b_MinPkVltAlld_FA.Value
        PokeBPCR_U_OCVAveCellVoltage
          data-send-points:
            access OUT_VeBPCR_U_OCVAvgCellVoltage_Value: accessed-variable=VeBPCR_U_OCVAvgCellVoltage.Value
            access OUT_VeBPCR_b_OCVAvgCellVoltage_FA_Value: accessed-variable=VeBPCR_b_OCVAvgCellVoltage_FA.Value
        PokeBPCR_U_OCVMaxCellVoltage
          data-send-points:
            access OUT_VeBPCR_U_OCVMaxCellVoltage_Value: accessed-variable=VeBPCR_U_OCVMaxCellVoltage.Value
            access OUT_VeBPCR_b_OCVMaxCellVoltage_FA_Value: accessed-variable=VeBPCR_b_OCVMaxCellVoltage_FA.Value
        PokeBPCR_U_OCVMinCellVoltage
          data-send-points:
            access OUT_VeBPCR_U_OCVMinCellVoltage_Value: accessed-variable=VeBPCR_U_OCVMinCellVoltage.Value
            access OUT_VeBPCR_b_OCVMinCellVoltage_FA_Value: accessed-variable=VeBPCR_b_OCVMinCellVoltage_FA.Value
        PokeBPCR_U_OCVPckVoltage
        PokeBPCR_Z_MaxCellChargeImpedance
        PokeBPCR_Z_MaxCellDischargeImpedance
          data-send-points:
            access OUT_VeBPCR_Z_MaxCellDschargeImpedance_Value: accessed-variable=VeBPCR_Z_MaxCellDschargeImpedance.Value
            access OUT_VeBPCR_b_MaxCellDschargeImpedance_FA_Value: accessed-variable=VeBPCR_b_MaxCellDschargeImpedance_FA.Value
        PokeBPCR_Z_MinCellChargeImpedance
        PokeBPCR_Z_MinCellDischargeImpedance
          data-send-points:
            access OUT_VeBPCR_Z_MinCellDschargeImpedance_Value: accessed-variable=VeBPCR_Z_MinCellDschargeImpedance.Value
            access OUT_VeBPCR_b_MinCellDschargeImpedance_FA_Value: accessed-variable=VeBPCR_b_MinCellDschargeImpedance_FA.Value
        PokeBPCR_b_BalMd
        PokeBPCR_b_CellVoltImbalance
        PokeBPCR_b_ChrgFail_On_BPCM
        PokeBPCR_b_DC_Isolation_Sts
          data-send-points:
            access OUT_VeBPCR_b_DC_Isolation_Sts_Value: accessed-variable=VeBPCR_b_DC_Isolation_Sts.Value
        PokeBPCR_b_EVSer_On_BPCM
        PokeBPCR_b_HBCNC_LV_LO
        PokeBPCR_b_HEVOnRqBPCM
          data-send-points:
            access OUT_VeBPCR_b_HEVOnRqBPCM_Value: accessed-variable=VeBPCR_b_HEVOnRqBPCM.Value
          written-local-variables:
            access WV_HEVOnRqBPCM_write_IRV: accessed-variable=HEVOnRqBPCM_write_IRV
        PokeBPCR_b_HVBatPerWU12VChrg
          data-send-points:
            access OUT_VeBPCR_b_HVBatPerWU12VChrg_Value: accessed-variable=VeBPCR_b_HVBatPerWU12VChrg.Value
        PokeBPCR_b_HVBatPerWUBal
        PokeBPCR_b_HVBatPerWUCharge
        PokeBPCR_b_HVBatPerWUThermal
          data-send-points:
            access OUT_VeBPCR_b_HVBatPerWUThermal_Value: accessed-variable=VeBPCR_b_HVBatPerWUThermal.Value
        PokeBPCR_b_HVBatRdy
          data-send-points:
            access OUT_VeBPCR_e_HVBatRdy_Value: accessed-variable=VeBPCR_e_HVBatRdy.Value
          written-local-variables:
            access WV_HV_BatRdySgnl_Rcvd_write_IRV: accessed-variable=HV_BatRdySgnl_Rcvd_write_IRV
            access WV_HVBatRdy_Init_write_IRV: accessed-variable=HVBatRdy_Init_write_IRV
        PokeBPCR_b_HVBatRdyForChrg
        PokeBPCR_b_HVBat_DC_CntctrOpn
          data-send-points:
            access OUT_VeBPCR_b_HVBat_DC_CntctrOpn_Value: accessed-variable=VeBPCR_b_HVBat_DC_CntctrOpn.Value
        PokeBPCR_b_HVBat_DC_CntctrReq
          data-send-points:
            access OUT_VeBPCR_b_HVBat_DC_CntctrReq_Value: accessed-variable=VeBPCR_b_HVBat_DC_CntctrReq.Value
        PokeBPCR_b_HVBat_Real_Time_Clock_V
        PokeBPCR_b_HVBattPerWakeUp
          data-send-points:
            access OUT_VeBPCR_b_HVBatPerWakeUp_Value: accessed-variable=VeBPCR_b_HVBatPerWakeUp.Value
        PokeBPCR_b_HV_AuxLoadOffReq
          data-send-points:
            access OUT_VeBPCR_b_HV_AuxLoadOffReq_Value: accessed-variable=VeBPCR_b_HV_AuxLoadOffReq.Value
            access OUT_VeBPCR_b_HV_AuxLoadOffReqFA_Value: accessed-variable=VeBPCR_b_HV_AuxLoadOffReqFA.Value
        PokeBPCR_b_HV_BatCntctrOpenPending
          written-local-variables:
            access WV_HV_BatCntctrOpenPending_write_IRV: accessed-variable=HV_BatCntctrOpenPending_write_IRV
        PokeBPCR_b_HV_BatCntctrOpenReq
          written-local-variables:
            access WV_HV_BatCntctrOpenReq_write_IRV: accessed-variable=HV_BatCntctrOpenReq_write_IRV
        PokeBPCR_b_HV_BatDriveRdy
        PokeBPCR_b_MIL_OnRq_BPCM
          written-local-variables:
            access WV_MILOnRqBPCM_Init_write_IRV: accessed-variable=MILOnRqBPCM_Init_write_IRV
        PokeBPCR_b_PwrLimON
          written-local-variables:
            access WV_PwrLimON_IRV: accessed-variable=PwrLimON_IRV
        PokeBPCR_b_StkOpnChkCmpl
          data-send-points:
            access OUT_VeBPCR_b_StkOpnChkCmpl_Value: accessed-variable=VeBPCR_b_StkOpnChkCmpl.Value
        PokeBPCR_cnt_BatteryModel
        PokeBPCR_cnt_HVBatt_ModNumMaxTmp
          data-send-points:
            access OUT_VeBPCR_Cnt_HVBat_ModNumMaxTmp_Value: accessed-variable=VeBPCR_Cnt_HVBat_ModNumMaxTmp.Value
        PokeBPCR_cnt_HVBatt_ModNumMinTmp
          data-send-points:
            access OUT_VeBPCR_Cnt_HVBat_ModNumMinTmp_Value: accessed-variable=VeBPCR_Cnt_HVBat_ModNumMinTmp.Value
        PokeBPCR_e_BPCMShtDwnRdy
          data-send-points:
            access OUT_VeBPCR_e_BPCMShtDwnRdy_Value: accessed-variable=VeBPCR_e_BPCMShtDwnRdy.Value
        PokeBPCR_e_BPCM_Comm_Fail
          data-send-points:
            access OUT_VeBPCR_e_BPCM_CommFail_Value: accessed-variable=VeBPCR_e_BPCM_CommFail.Value
            access OUT_VeBPCR_b_BPCM_CommFailFA_Value: accessed-variable=VeBPCR_b_BPCM_CommFailFA.Value
        PokeBPCR_e_BPCM_LIN_BusOff
          data-send-points:
            access OUT_VeBPCR_e_BPCM_LIN_BusOff_Value: accessed-variable=VeBPCR_e_BPCM_LIN_BusOff.Value
            access OUT_VeBPCR_b_BPCM_LIN_BusOff_FA_Value: accessed-variable=VeBPCR_b_BPCM_LIN_BusOff_FA.Value
            access OUT_VeBPCR_b_BPCM_LIN_BusOff_SgnlRcvd_Value: accessed-variable=VeBPCR_b_BPCM_LIN_BusOff_SgnlRcvd.Value
        PokeBPCR_e_BPCM_LOC_BCP
          data-send-points:
            access OUT_VeBPCR_e_BPCM_LOC_BCP_Value: accessed-variable=VeBPCR_e_BPCM_LOC_BCP.Value
            access OUT_VeBPCR_b_BPCM_LOC_BCP_FA_Value: accessed-variable=VeBPCR_b_BPCM_LOC_BCP_FA.Value
            access OUT_VeBPCR_b_BPCM_LOC_BCP_SgnlRcvd_Value: accessed-variable=VeBPCR_b_BPCM_LOC_BCP_SgnlRcvd.Value
        PokeBPCR_e_BPCM_LOC_BatClntHtr
          data-send-points:
            access OUT_VeBPCR_e_BPCM_LOC_BatClntHtr_Value: accessed-variable=VeBPCR_e_BPCM_LOC_BatClntHtr.Value
            access OUT_VeBPCR_b_BPCM_LOC_BatClntHtr_FA_Value: accessed-variable=VeBPCR_b_BPCM_LOC_BatClntHtr_FA.Value
            access OUT_VeBPCR_b_BPCM_LOC_BatClntHtr_SgnlRcvd_Value: accessed-variable=VeBPCR_b_BPCM_LOC_BatClntHtr_SgnlRcvd.Value
        PokeBPCR_e_ChargingStat_BPCM
          data-send-points:
            access OUT_VeBPCR_e_ChargingStat_BPCM_Value: accessed-variable=VeBPCR_e_ChargingStat_BPCM.Value
            access OUT_VeBPCR_b_ChargingStat_BPCMFA_Value: accessed-variable=VeBPCR_b_ChargingStat_BPCMFA.Value
        PokeBPCR_e_DCIsolSts
          data-send-points:
            access OUT_VeBPCR_e_DCIsolSts_Value: accessed-variable=VeBPCR_e_DCIsolSts.Value
            access OUT_VeBPCR_b_DCIsolStsFA_Value: accessed-variable=VeBPCR_b_DCIsolStsFA.Value
        PokeBPCR_e_HVBatCntrWeld_ImpdOpn
          data-send-points:
            access OUT_VeBPCR_b_Flst_HVBatCntrWeld_ImpdOpn_Value: accessed-variable=VeBPCR_b_Flst_HVBatCntrWeld_ImpdOpn.Value
          written-local-variables:
            access WV_VeBPCR_b_HVBatCntrWeld_ImpdOpnSgnl_Rcvd_write_IRV: accessed-variable=VeBPCR_b_HVBatCntrWeld_ImpdOpnSgnl_Rcvd_write_IRV
            access WV_HVBatCntrWeld_ImpdOpn_write_IRV: accessed-variable=HVBatCntrWeld_ImpdOpn_write_IRV
        PokeBPCR_e_HVBatIntrlkIntrnlStat
          data-send-points:
            access OUT_VeBPCR_e_HVBatIntrlkIntrnlStat_Value: accessed-variable=VeBPCR_e_HVBatIntrlkIntrnlStat.Value
            access OUT_VeBPCR_b_HVBatIntrlkIntrnlStatFA_Value: accessed-variable=VeBPCR_b_HVBatIntrlkIntrnlStatFA.Value
        PokeBPCR_e_HVBatPerWU_Rsn
        PokeBPCR_e_HVBat_DC_CntctrStat
          data-send-points:
            access OUT_VeBPCR_e_HVBat_DC_CntctrStat_Value: accessed-variable=VeBPCR_e_HVBat_DC_CntctrStat.Value
            access OUT_VeBPCR_b_HVBat_DC_CntctrStat_FA_Value: accessed-variable=VeBPCR_b_HVBat_DC_CntctrStat_FA.Value
        PokeBPCR_e_HV_BatCntctrStat
          written-local-variables:
            access WV_HV_BatCntctrStatFA_write_IRV: accessed-variable=HV_BatCntctrStatFA_write_IRV
            access WV_HV_BatCntctrStat_write_IRV: accessed-variable=HV_BatCntctrStat_write_IRV
        PokeBPCR_e_HV_BatInrlkStat
          data-send-points:
            access OUT_VeBPCR_e_HV_BatInrlkStat_Value: accessed-variable=VeBPCR_e_HV_BatInrlkStat.Value
            access OUT_VeBPCR_b_HV_BatInrlkStatFA_Value: accessed-variable=VeBPCR_b_HV_BatInrlkStatFA.Value
        PokeBPCR_e_HV_BatIsolStat
          data-send-points:
            access OUT_VeBPCR_e_HV_BatIsolStat_Value: accessed-variable=VeBPCR_e_HV_BatIsolStat.Value
            access OUT_VeBPCR_e_HV_BatIsolStat_raw_Value: accessed-variable=VeBPCR_e_HV_BatIsolStat_raw.Value
        PokeBPCR_e_HV_DcChargeTypeStat
          data-send-points:
            access OUT_VeBPCR_e_HVDcChargeTypeStat_Value: accessed-variable=VeBPCR_e_HVDcChargeTypeStat.Value
        PokeBPCR_e_HV_TracBatCntctrConfig
          data-send-points:
            access OUT_VeBPCR_e_HVTracBatCntctrConfig_Value: accessed-variable=VeBPCR_e_HVTracBatCntctrConfig.Value
        PokeBPCR_e_PowerModeState
        PokeBPCR_e_PwrtrnHV_IsolStat
          data-send-points:
            access OUT_VeBPCR_e_PwrtrnHV_IsolStat_Value: accessed-variable=VeBPCR_e_PwrtrnHV_IsolStat.Value
        PokeBPCR_e_ThrmlRnawy_Warn
          written-local-variables:
            access WV_HVBat_ThrmlRnawy_WarnFA_Init_write_IRV: accessed-variable=HVBat_ThrmlRnawy_WarnFA_Init_write_IRV
            access WV_HVBat_ThrmlRnawy_Warn_Init_write_IRV: accessed-variable=HVBat_ThrmlRnawy_Warn_Init_write_IRV
        PokeBPCR_i_DC_Isolation_Sts_M182
          data-send-points:
            access OUT_VeBPCR_b_DC_Isolation_Sts_Value: accessed-variable=VeBPCR_b_DC_Isolation_Sts.Value
        PokeBPCR_q_FullAmpHrCap
          data-send-points:
            access OUT_VeBPCR_q_FullAmpHrCap_Value: accessed-variable=VeBPCR_q_FullAmpHrCap.Value
        PokeBPCR_q_RemainingAmpHrCap
          data-send-points:
            access OUT_VeBPCR_q_RemainingAmpHrCap_Value: accessed-variable=VeBPCR_q_RemainingAmpHrCap.Value
            access OUT_VeBPCR_b_RemainingAmpHrCapFA_Value: accessed-variable=VeBPCR_b_RemainingAmpHrCapFA.Value
        PokeBPCR_t_BSW_PWMCntctrTmr
          written-local-variables:
            access WV_BSW_PWMTmrRcvd_write_IRV: accessed-variable=BSW_PWMTmrRcvd_write_IRV
        PokeBPCR_t_HVBatRealTimeClock
          data-send-points:
            access OUT_VeBPCR_t_HVBatRealTimeClock_Value: accessed-variable=VeBPCR_t_HVBatRealTimeClock.Value
            access OUT_VeBPCR_b_HVBatRealTimeClock_FA_Value: accessed-variable=VeBPCR_b_HVBatRealTimeClock_FA.Value
        PokeBPCR_t_HVBatSleepTime
          data-send-points:
            access OUT_VeBPCR_t_HVBatSleepTime_Value: accessed-variable=VeBPCR_t_HVBatSleepTime.Value
        PokeBPCR_t_HVBattCntctrOpnTm
          data-send-points:
            access OUT_VeBPCR_t_HVBattCntctrOpnTm_Value: accessed-variable=VeBPCR_t_HVBattCntctrOpnTm.Value
        PokeBPCR_t_PrechrgPnltyTimer
          data-send-points:
            access OUT_VeBPCR_t_PrechrgPnltyTimer_Value: accessed-variable=VeBPCR_t_PrechrgPnltyTimer.Value
        TmotBPCR_b_HVBatCntrWeld_ImpdOpn
          written-local-variables:
            access WV_VeBPCR_b_HVBatCntrWeld_ImpdOpnSgnl_Rcvd_write_IRV: accessed-variable=VeBPCR_b_HVBatCntrWeld_ImpdOpnSgnl_Rcvd_write_IRV
        TmotBPCR_b_HVBatRdy
          data-send-points:
            access OUT_VeBPCR_e_HVBatRdy_Value: accessed-variable=VeBPCR_e_HVBatRdy.Value
          written-local-variables:
            access WV_HV_BatRdySgnl_Rcvd_write_IRV: accessed-variable=HV_BatRdySgnl_Rcvd_write_IRV
        TmotBPCR_b_HV_BatChrgPwrET
          data-send-points:
            access OUT_VeBPCR_b_HV_BatChrgPwrETSgnl_Rcvd_Value: accessed-variable=VeBPCR_b_HV_BatChrgPwrETSgnl_Rcvd.Value
          written-local-variables:
            access WV_VeBPCR_b_HV_BatChrgPwrETSgnl_Rcvd_write_IRV: accessed-variable=VeBPCR_b_HV_BatChrgPwrETSgnl_Rcvd_write_IRV
        TmotBPCR_b_HV_BatChrgPwrLT
          data-send-points:
            access OUT_VeBPCR_b_HV_BatChrgPwrLTSgnl_Rcvd_Value: accessed-variable=VeBPCR_b_HV_BatChrgPwrLTSgnl_Rcvd.Value
          written-local-variables:
            access WV_VeBPCR_b_HV_BatChrgPwrLTSgnl_Rcvd_write_IRV: accessed-variable=VeBPCR_b_HV_BatChrgPwrLTSgnl_Rcvd_write_IRV
        TmotBPCR_b_HV_BatChrgPwrST
          data-send-points:
            access OUT_VeBPCR_b_HV_BatChrgPwrSTSgnl_Rcvd_Value: accessed-variable=VeBPCR_b_HV_BatChrgPwrSTSgnl_Rcvd.Value
          written-local-variables:
            access WV_VeBPCR_b_HV_BatChrgPwrSTSgnl_Rcvd_write_IRV: accessed-variable=VeBPCR_b_HV_BatChrgPwrSTSgnl_Rcvd_write_IRV
        TmotBPCR_b_HV_BatDschrgPwrET
          data-send-points:
            access OUT_VeBPCR_b_HV_BatDschrgPwrETSgnl_Rcvd_Value: accessed-variable=VeBPCR_b_HV_BatDschrgPwrETSgnl_Rcvd.Value
          written-local-variables:
            access WV_VeBPCR_b_HV_BatDschrgPwrETSgnl_Rcvd_write_IRV: accessed-variable=VeBPCR_b_HV_BatDschrgPwrETSgnl_Rcvd_write_IRV
        TmotBPCR_b_HV_BatDschrgPwrLT
          data-send-points:
            access OUT_VeBPCR_b_HV_BatDschrgPwrLTSgnl_Rcvd_Value: accessed-variable=VeBPCR_b_HV_BatDschrgPwrLTSgnl_Rcvd.Value
          written-local-variables:
            access WV_VeBPCR_b_HV_BatDschrgPwrLTSgnl_Rcvd_write_IRV: accessed-variable=VeBPCR_b_HV_BatDschrgPwrLTSgnl_Rcvd_write_IRV
        TmotBPCR_b_HV_BatDschrgPwrST
          data-send-points:
            access OUT_VeBPCR_b_HV_BatDschrgPwrSTSgnl_Rcvd_Value: accessed-variable=VeBPCR_b_HV_BatDschrgPwrSTSgnl_Rcvd.Value
          written-local-variables:
            access WV_VeBPCR_b_HV_BatDschrgPwrSTSgnl_Rcvd_write_IRV: accessed-variable=VeBPCR_b_HV_BatDschrgPwrSTSgnl_Rcvd_write_IRV
        TmotBPCR_b_HV_BatModTempAvg
          written-local-variables:
            access WV_VeBPCR_b_HV_BatModTempAvgSgnl_Rcvd_write_IRV: accessed-variable=VeBPCR_b_HV_BatModTempAvgSgnl_Rcvd_write_IRV
        TmotBPCR_b_HV_BatModTempMax
          written-local-variables:
            access WV_VeBPCR_b_HV_BatModTempMaxSgnl_Rcvd_write_IRV: accessed-variable=VeBPCR_b_HV_BatModTempMaxSgnl_Rcvd_write_IRV
        TmotBPCR_b_HV_BatModTempMin
          written-local-variables:
            access WV_VeBPCR_b_HV_BatModTempMinSgnl_Rcvd_write_IRV: accessed-variable=VeBPCR_b_HV_BatModTempMinSgnl_Rcvd_write_IRV
        TmotBPCR_b_HV_BatPackSOC
          data-send-points:
            access OUT_VeBPCR_b_HV_BatPackSOC_SgnlRcvd_Value: accessed-variable=VeBPCR_b_HV_BatPackSOC_SgnlRcvd.Value
          written-local-variables:
            access WV_VeBPCR_b_HV_BatPackSOCSgnl_Rcvd_write_IRV: accessed-variable=VeBPCR_b_HV_BatPackSOCSgnl_Rcvd_write_IRV
        TmotBPCR_e_BPCM_LIN_BusOff
          data-send-points:
            access OUT_VeBPCR_b_BPCM_LIN_BusOff_SgnlRcvd_Value: accessed-variable=VeBPCR_b_BPCM_LIN_BusOff_SgnlRcvd.Value
        TmotBPCR_e_BPCM_LOC_BCP
          data-send-points:
            access OUT_VeBPCR_b_BPCM_LOC_BCP_SgnlRcvd_Value: accessed-variable=VeBPCR_b_BPCM_LOC_BCP_SgnlRcvd.Value
        TmotBPCR_e_BPCM_LOC_BatClntHtr
          data-send-points:
            access OUT_VeBPCR_b_BPCM_LOC_BatClntHtr_SgnlRcvd_Value: accessed-variable=VeBPCR_b_BPCM_LOC_BatClntHtr_SgnlRcvd.Value
      4 x variation point proxy, all with category=CONDITION, condition-access=0:
        Variant_BPCR_1
        Variant_BPCR_3
        Variant_BPCR_5
        Variant_BPCR_BatPckSOCFAInit
